VERSION "dbc-export 1 2025.20.8"

NS_ :

BS_:

BU_: ADSP APB APP APS BB BMS CC CP DAS DI DIF DIR EPAS3P EPAS3S EPBL EPBR GTW HVP ICR IDB PCS PM TCU UI UIS VC VCFRONT VCLEFT VCRIGHT VCSEC

BO_ 691 VCRIGHT_logging1Hz: 8 VCRIGHT
 SG_ VCRIGHT_logging1HzIndex M : 0|5@1+ (1,0) [0|31] "" Vector__XXX
 SG_ VCRIGHT_tempIncarCabinProbe m0 : 8|8@1+ (0.5,-40) [-40|85] "degC" Vector__XXX
 SG_ VCRIGHT_tempIncarCabinDeep m0 : 16|8@1+ (0.5,-40) [-40|85] "degC" Vector__XXX
 SG_ VCRIGHT_cabinTempInteriorL2 m0 : 24|8@1+ (0.5,-40) [-40|80] "degC" Vector__XXX
 SG_ VCRIGHT_tempIncarCabinMid m0 : 32|8@1+ (0.5,-40) [-40|85] "degC" Vector__XXX
 SG_ VCRIGHT_cabinTempInteriorSunnyL2 m0 : 40|8@1+ (0.6,-40) [-40|100] "degC" Vector__XXX
 SG_ VCRIGHT_cabinTempInteriorL3 m0 : 48|8@1+ (0.5,-40) [-40|80] "degC" Vector__XXX
 SG_ VCRIGHT_cabinTempInteriorSunnyL3 m0 : 56|8@1+ (0.6,-40) [-40|100] "degC" Vector__XXX
 SG_ VCRIGHT_cabinTempGlassRoof m1 : 8|8@1+ (0.5,-40) [-40|80] "degC" Vector__XXX
 SG_ VCRIGHT_cabinTempWindshield m1 : 16|8@1+ (0.5,-40) [-40|80] "degC" Vector__XXX
 SG_ VCRIGHT_cabinTempInterior m1 : 24|8@1+ (0.5,-40) [-40|80] "degC" Vector__XXX
 SG_ VCRIGHT_cabinTempInteriorSunny m1 : 32|8@1+ (0.6,-40) [-40|100] "degC" Vector__XXX
 SG_ VCRIGHT_cabinTempSideGlassLeft m1 : 40|8@1+ (0.5,-40) [-40|80] "degC" Vector__XXX
 SG_ VCRIGHT_cabinTempSideGlassRight m1 : 48|8@1+ (0.5,-40) [-40|80] "degC" Vector__XXX
 SG_ VCRIGHT_cabinTempBreathLevel m1 : 56|8@1+ (0.5,-40) [-40|80] "degC" Vector__XXX
 SG_ VCRIGHT_pcbaTemperature m2 : 5|11@1+ (0.125,-40) [-40|150] "degC" Vector__XXX
 SG_ VCRIGHT_wattsHeaterLeftTotal m2 : 16|10@1+ (5,0) [0|4000] "W" Vector__XXX
 SG_ VCRIGHT_wattsHeaterRightTotal m2 : 26|10@1+ (5,0) [0|4000] "W" Vector__XXX
 SG_ VCRIGHT_qdotLeftFFUnsat m2 : 36|9@1- (10,0) [-1500|1500] "W" Vector__XXX
 SG_ VCRIGHT_qdotRightFFUnsat m2 : 45|9@1- (10,0) [-1500|1500] "W" Vector__XXX
 SG_ VCRIGHT_nvhLevelDb m2 : 54|9@1+ (0.1,30) [30|80] "dB" Vector__XXX
 SG_ VCRIGHT_hvacSetTempActualLeft m3 : 8|8@1+ (0.1,15) [15|28] "degC" Vector__XXX
 SG_ VCRIGHT_hvacSetTempActualRight m3 : 16|8@1+ (0.1,15) [15|28] "degC" Vector__XXX
 SG_ VCRIGHT_hvacAutoTransitionReason m3 : 24|5@1+ (1,0) [0|31] "" Vector__XXX
 SG_ VCRIGHT_hvacMassflowTarget m3 : 29|8@1+ (1,0) [0|200] "g/s" Vector__XXX
 SG_ VCRIGHT_hvacQdotLimitedLeft m3 : 37|1@1+ (1,0) [0|1] "" Vector__XXX
 SG_ VCRIGHT_hvacQdotLimitedRight m3 : 38|1@1+ (1,0) [0|1] "" Vector__XXX
 SG_ VCRIGHT_LHPanelAirflowBlocked m3 : 39|1@1+ (1,0) [0|1] "" Vector__XXX
 SG_ VCRIGHT_RHPanelAirflowBlocked m3 : 40|1@1+ (1,0) [0|1] "" Vector__XXX
 SG_ VCRIGHT_floorAirflowBlocked m3 : 41|1@1+ (1,0) [0|1] "" Vector__XXX
 SG_ VCRIGHT_defrostAirflowBlocked m3 : 42|1@1+ (1,0) [0|1] "" Vector__XXX
 SG_ VCRIGHT_hvacFilterLifeDetectActi m3 : 43|1@1+ (1,0) [0|1] "" Vector__XXX
 SG_ VCRIGHT_hvacLHBleedOperationMode m3 : 44|1@1+ (1,0) [0|1] "" Vector__XXX
 SG_ VCRIGHT_hvacRHBleedOperationMode m3 : 45|1@1+ (1,0) [0|1] "" Vector__XXX
 SG_ VCRIGHT_hvacLHVaneOperationMode m3 : 46|1@1+ (1,0) [0|1] "" Vector__XXX
 SG_ VCRIGHT_hvacRHVaneOperationMode m3 : 47|1@1+ (1,0) [0|1] "" Vector__XXX
 SG_ VCRIGHT_hvacUpperModeOpMode m3 : 48|1@1+ (1,0) [0|1] "" Vector__XXX
 SG_ VCRIGHT_hvacLowerModeOpMode m3 : 49|1@1+ (1,0) [0|1] "" Vector__XXX
 SG_ VCRIGHT_hvacIntakeOperationMode m3 : 50|1@1+ (1,0) [0|1] "" Vector__XXX
 SG_ VCRIGHT_isProbeFeedbackApplied m3 : 52|3@1+ (1,0) [0|7] "" Vector__XXX
 SG_ VCRIGHT_feedbackPullDownScalar m3 : 55|2@1+ (30,70) [70|130] "-" Vector__XXX
 SG_ VCRIGHT_feedForwardPullDownScala m3 : 57|6@1+ (1,70) [70|130] "-" Vector__XXX
 SG_ VCRIGHT_convectionTargetLeft m4 : 5|9@1+ (4,-1000) [-1000|1000] "W/m2" Vector__XXX
 SG_ VCRIGHT_convectionTargetRight m4 : 14|9@1+ (4,-1000) [-1000|1000] "W/m2" Vector__XXX
 SG_ VCRIGHT_convectionDeliveredLeft m4 : 23|9@1+ (4,-1000) [-1000|1000] "W/m2" Vector__XXX
 SG_ VCRIGHT_convectionDeliveredRight m4 : 32|9@1+ (4,-1000) [-1000|1000] "W/m2" Vector__XXX
 SG_ VCRIGHT_solarLoadRightOccupant m4 : 41|7@1+ (2,0) [0|252] "W/m2" Vector__XXX
 SG_ VCRIGHT_solarLoadLeftOccupant m4 : 48|7@1+ (2,0) [0|252] "W/m2" Vector__XXX
 SG_ VCRIGHT_ptcShutOutletMitigationA m4 : 55|1@1+ (1,0) [0|1] "" Vector__XXX
 SG_ VCRIGHT_solarLoadFromThsTemp m4 : 56|8@1+ (8,-1020) [-1020|1012] "W/m2" Vector__XXX
 SG_ VCRIGHT_ptcHeaterTempDuctHigh m5 : 5|1@1+ (1,0) [0|1] "" Vector__XXX
 SG_ VCRIGHT_ptcHeaterTempDuctFault m5 : 6|1@1+ (1,0) [0|1] "" Vector__XXX
 SG_ VCRIGHT_ptcHeaterNoAirflow m5 : 7|1@1+ (1,0) [0|1] "" Vector__XXX
 SG_ VCRIGHT_ptcHeaterHvacActNotReady m5 : 8|1@1+ (1,0) [0|1] "" Vector__XXX
 SG_ VCRIGHT_ptcHeaterNoUiRequest m5 : 9|1@1+ (1,0) [0|1] "" Vector__XXX
 SG_ VCRIGHT_ptcHeaterNoHighVoltage m5 : 10|1@1+ (1,0) [0|1] "" Vector__XXX
 SG_ VCRIGHT_ptcHeaterLAirPathBlocked m5 : 11|1@1+ (1,0) [0|1] "" Vector__XXX
 SG_ VCRIGHT_ptcHeaterRAirPathBlocked m5 : 12|1@1+ (1,0) [0|1] "" Vector__XXX
 SG_ VCRIGHT_ptcHeaterReqAirpathBlock m5 : 13|1@1+ (1,0) [0|1] "" Vector__XXX
 SG_ VCRIGHT_hvacQdotFeedforward m5 : 16|16@1+ (1,-32767) [-32767|32767] "W" Vector__XXX
 SG_ VCRIGHT_evapLoadInFresh m5 : 32|8@1+ (35,0) [0|8000] "W" Vector__XXX
 SG_ VCRIGHT_evapLoadInRecirc m5 : 40|8@1+ (35,0) [0|8000] "W" Vector__XXX
 SG_ VCRIGHT_cabinTempWshldDefog m5 : 48|8@1+ (0.5,-40) [-40|80] "degC" Vector__XXX
 SG_ VCRIGHT_cabinTempWshldDefogTop m5 : 56|8@1+ (0.5,-40) [-40|80] "degC" Vector__XXX
 SG_ VCRIGHT_hvacLHBleedVoltage m6 : 8|8@1+ (0.02,0) [0|5] "V" Vector__XXX
 SG_ VCRIGHT_hvacRHBleedVoltage m6 : 16|8@1+ (0.02,0) [0|5] "V" Vector__XXX
 SG_ VCRIGHT_hvacLHVaneVoltage m6 : 24|8@1+ (0.02,0) [0|5] "V" Vector__XXX
 SG_ VCRIGHT_hvacRHVaneVoltage m6 : 32|8@1+ (0.02,0) [0|5] "V" Vector__XXX
 SG_ VCRIGHT_hvacUpperModeVoltage m6 : 40|8@1+ (0.02,0) [0|5] "V" Vector__XXX
 SG_ VCRIGHT_hvacLowerModeVoltage m6 : 48|8@1+ (0.02,0) [0|5] "V" Vector__XXX
 SG_ VCRIGHT_hvacIntakeVoltage m6 : 56|8@1+ (0.02,0) [0|5] "V" Vector__XXX
 SG_ VCRIGHT_cabinTempBreathLevelFHea m7 : 8|8@1+ (0.5,-40) [-40|80] "degC" Vector__XXX
 SG_ VCRIGHT_cabinTempBreathLevelFCoo m7 : 16|8@1+ (0.5,-40) [-40|80] "degC" Vector__XXX
 SG_ VCRIGHT_cabinTempBreathLeve_0002 m7 : 24|8@1+ (0.5,-40) [-40|80] "degC" Vector__XXX
 SG_ VCRIGHT_cabinTempBreathLevelF5mi m7 : 32|8@1+ (0.5,-40) [-40|80] "degC" Vector__XXX
 SG_ VCRIGHT_cabinTempBreathLeve_0001 m7 : 40|8@1+ (0.5,-40) [-40|80] "degC" Vector__XXX
 SG_ VCRIGHT_cabinTempBreathLevelF10m m7 : 48|8@1+ (0.5,-40) [-40|80] "degC" Vector__XXX
 SG_ VCRIGHT_cabinTempInteriorFHeatin m7 : 56|8@1+ (0.5,-40) [-40|80] "degC" Vector__XXX
 SG_ VCRIGHT_hvacCabOvrheatProtActive m8 : 5|1@1+ (1,0) [0|1] "" Vector__XXX
 SG_ VCRIGHT_hvacCabinPurgeAllowed m8 : 6|1@1+ (1,0) [0|1] "" Vector__XXX
 SG_ VCRIGHT_hvacCabOvrheatProtAllowe m8 : 7|1@1+ (1,0) [0|1] "" Vector__XXX
 SG_ VCRIGHT_filterLifeBlowerTorque m8 : 8|10@1+ (0.006,-1.5) [-1.5|4.5] "Nm" Vector__XXX
 SG_ VCRIGHT_cabinTempFanCurrent m8 : 18|6@1+ (0.001,-0.01) [-0.01|0.05] "A" Vector__XXX
 SG_ VCRIGHT_cabinTempFanOutput m8 : 24|1@1+ (1,0) [0|1] "" Vector__XXX
 SG_ VCRIGHT_cloudinessEstimatedPct m8 : 25|7@1+ (1,0) [0|100] "%" Vector__XXX
 SG_ VCRIGHT_solarLoadOnVehFiltered m8 : 32|8@1+ (4,0) [0|1016] "W/m2" Vector__XXX
 SG_ VCRIGHT_cabinTempProbeEstimate m8 : 40|8@1+ (0.5,-40) [-40|80] "degC" Vector__XXX
 SG_ VCRIGHT_cabinTempThs m8 : 48|8@1+ (0.5,-40) [-40|80] "degC" Vector__XXX
 SG_ VCRIGHT_cabinTempThsBracket m8 : 56|8@1+ (0.5,-40) [-40|80] "degC" Vector__XXX
 SG_ VCRIGHT_leftHeatOvertempProtect m9 : 5|1@1+ (1,0) [0|1] "" Vector__XXX
 SG_ VCRIGHT_rightHeatOvertempProtect m9 : 6|1@1+ (1,0) [0|1] "" Vector__XXX
 SG_ VCRIGHT_CO2ppm m9 : 7|10@1+ (5,0) [0|4000] "-" Vector__XXX
 SG_ VCRIGHT_timeLeftToCabinModelInit m9 : 17|7@1+ (1,0) [0|127] "" Vector__XXX
 SG_ VCRIGHT_hvacEstimateWindshieldRH m9 : 24|8@1+ (1,0) [0|150] "%" Vector__XXX
 SG_ VCRIGHT_hvacFoggingRiskLevel m9 : 32|7@1+ (1,0) [0|100] "%" Vector__XXX
 SG_ VCRIGHT_hvacCabinHumidityLevel m9 : 39|7@1+ (1,0) [0|100] "%" Vector__XXX
 SG_ VCRIGHT_hvacFlashFoggingDetected m9 : 47|1@1+ (1,0) [0|1] "" Vector__XXX
 SG_ VCRIGHT_solarSensitivityInfr m9 : 48|7@1+ (1,0) [0|100] "-" Vector__XXX
 SG_ VCRIGHT_solarSensitivityInfrCorr m9 : 55|7@1+ (1,0) [0|100] "-" Vector__XXX
 SG_ VCRIGHT_lumbarCurrent m10 : 5|4@1+ (0.2,0) [0|3] "A" Vector__XXX
 SG_ VCRIGHT_ocsCurrent m10 : 9|3@1+ (0.01,0) [0|0.07] "A" Vector__XXX
 SG_ VCRIGHT_rcmCurrent m10 : 12|5@1+ (0.1,0) [0|3.1] "A" Vector__XXX
 SG_ VCRIGHT_radioTunerCurrent m10 : 17|4@1+ (0.1,0) [0|1.5] "A" Vector__XXX
 SG_ VCRIGHT_rearOilPumpCurrent m10 : 21|5@1+ (0.5,0) [0|15.5] "A" Vector__XXX
 SG_ VCRIGHT_rearDefrostCurrent m10 : 26|5@1+ (2,0) [0|62] "A" Vector__XXX
 SG_ VCRIGHT_tailLightCurrent m10 : 31|4@1+ (0.1,0) [0|1.5] "A" Vector__XXX
 SG_ VCRIGHT_turnTailStopLightCurrent m10 : 35|4@1+ (0.1,0) [0|1.5] "A" Vector__XXX
 SG_ VCRIGHT_reverseFogLightsCurrent m10 : 39|4@1+ (0.1,0) [0|1.4] "A" Vector__XXX
 SG_ VCRIGHT_stopReverseTurnLightCurr m10 : 43|4@1+ (0.1,0) [0|1.5] "A" Vector__XXX
 SG_ VCRIGHT_sideMirrorCurrent m10 : 47|5@1+ (0.2,0) [0|6.2] "A" Vector__XXX
 SG_ VCRIGHT_sideMirrorHeaterCurrent m10 : 52|5@1+ (0.2,0) [0|6] "A" Vector__XXX
 SG_ VCRIGHT_frontSeatHeatCushionPwr m10 : 57|7@1+ (1,0) [0|127] "W" Vector__XXX
 SG_ VCRIGHT_trunkInteriorLEDCurrent m11 : 8|4@1+ (5,0) [0|70] "mA" Vector__XXX
 SG_ VCRIGHT_mapPocketLEDsCurrent m11 : 12|4@1+ (5,0) [0|70] "mA" Vector__XXX
 SG_ VCRIGHT_miscEFuseCurrent m11 : 16|5@1+ (0.05,0) [0|1.5] "A" Vector__XXX
 SG_ VCRIGHT_interiorHandleLEDCurrent m11 : 21|4@1+ (2,0) [0|30] "mA" Vector__XXX
 SG_ VCRIGHT_miscInteriorLightsCurren m11 : 25|3@1+ (5,0) [0|30] "mA" Vector__XXX
 SG_ VCRIGHT_frontPuddleLEDCurrent m11 : 28|3@1+ (0.05,0) [0|0.3] "A" Vector__XXX
 SG_ VCRIGHT_rearPuddleLEDCurrent m11 : 31|3@1+ (0.05,0) [0|0.3] "A" Vector__XXX
 SG_ VCRIGHT_liftgateShutfaceLEDCurre m11 : 34|3@1+ (5,0) [0|30] "mA" Vector__XXX
 SG_ VCRIGHT_3rSeatTOSCurrent m11 : 37|4@1+ (5,0) [0|70] "mA" Vector__XXX
 SG_ VCRIGHT_vbatFusedCurrent m11 : 41|4@1+ (0.1,0) [0|1.4] "A" Vector__XXX
 SG_ VCRIGHT_cabinTempGlassGridHeater m11 : 45|8@1+ (0.5,-40) [-40|80] "degC" Vector__XXX
 SG_ VCRIGHT_hvacAirflowReasonRight m11 : 53|5@1+ (1,0) [0|31] "" Vector__XXX
 SG_ VCRIGHT_hvacAirflowReasonLeft m11 : 58|5@1+ (1,0) [0|31] "" Vector__XXX
 SG_ VCRIGHT_hvacMassflowTargetLeft m12 : 5|8@1+ (1,0) [0|200] "g/s" Vector__XXX
 SG_ VCRIGHT_hvacMassflowTargetRight m12 : 13|8@1+ (1,0) [0|200] "g/s" Vector__XXX
 SG_ VCRIGHT_solarLoadLeftOccupantFil m12 : 21|7@1+ (2,0) [0|252] "W/m2" Vector__XXX
 SG_ VCRIGHT_solarLoadRightOccupantFi m12 : 28|7@1+ (2,0) [0|252] "W/m2" Vector__XXX
 SG_ VCRIGHT_windshieldRHCapped m12 : 35|8@1+ (1,0) [0|150] "%" Vector__XXX
 SG_ VCRIGHT_feedbackWarmUpScalar m12 : 43|2@1+ (16,84) [84|116] "-" Vector__XXX
 SG_ VCRIGHT_maxMassflowScalarWarmUp m12 : 45|5@1+ (1,74) [74|100] "-" Vector__XXX
 SG_ VCRIGHT_feedforwardWarmUpScalar m12 : 50|6@1+ (1,80) [80|120] "-" Vector__XXX
 SG_ VCRIGHT_frontSeatHeatBackrestPwr m12 : 56|7@1+ (1,0) [0|127] "W" Vector__XXX
 SG_ VCRIGHT_maxMassflowScalar m13 : 5|6@1+ (1,60) [60|100] "-" Vector__XXX
 SG_ VCRIGHT_massflowTargetAutoInManu m13 : 11|8@1+ (1,0) [0|250] "g/s" Vector__XXX
 SG_ VCRIGHT_airflowReasonAutoInManua m13 : 19|5@1+ (1,0) [0|31] "" Vector__XXX
 SG_ VCRIGHT_airflowReasonAutoIn_0001 m13 : 24|5@1+ (1,0) [0|31] "" Vector__XXX
 SG_ VCRIGHT_airflowReasonAutoIn_0002 m13 : 29|5@1+ (1,0) [0|31] "" Vector__XXX
 SG_ VCRIGHT_cabinTempInteriorFCoolin m13 : 34|8@1+ (0.5,-40) [-40|80] "degC" Vector__XXX
 SG_ VCRIGHT_averageDuctTempFHeating m13 : 42|8@1+ (0.5,-40) [-40|80] "degC" Vector__XXX
 SG_ VCRIGHT_averageDuctTempFCooling m13 : 50|8@1+ (0.5,-40) [-40|80] "degC" Vector__XXX
 SG_ VCRIGHT_hvacBiLevelWhsldRhEst m13 : 58|6@1+ (2,20) [20|120] "%" Vector__XXX
 SG_ VCRIGHT_steeringWheelSurfaceTemp m14 : 5|10@1+ (0.1,-35) [-35|65] "degC" Vector__XXX
 SG_ VCRIGHT_steeringWheelSurfac_0001 m14 : 16|10@1+ (0.1,-35) [-35|65] "degC" Vector__XXX
 SG_ VCRIGHT_timeToComfortHeating m14 : 26|6@1+ (15,-15) [-15|930] "s" Vector__XXX
 SG_ VCRIGHT_timeToComfortCooling m14 : 32|6@1+ (15,-15) [-15|930] "s" Vector__XXX
 SG_ VCRIGHT_cabinWaterMassRaw m14 : 40|8@1+ (0.1,0) [0|25] "g/kg" Vector__XXX
 SG_ VCRIGHT_massflowSingleZoneSplit m14 : 48|7@1+ (1,0) [0|100] "-" Vector__XXX
 SG_ VCRIGHT_VOCPurgeState m14 : 56|3@1+ (1,0) [0|7] "" Vector__XXX
 SG_ VCRIGHT_cameraFoggingMonitorStat m14 : 59|3@1+ (1,0) [0|7] "" Vector__XXX
 SG_ VCRIGHT_cabinOverheatProtectNotR m15 : 5|14@1+ (1,0) [0|16383] "" Vector__XXX
 SG_ VCRIGHT_hvacIntakeReason m15 : 19|5@1+ (1,0) [0|31] "" Vector__XXX
 SG_ VCRIGHT_hvacCabinPurgeActive m15 : 24|1@1+ (1,0) [0|1] "" Vector__XXX
 SG_ VCRIGHT_solarAzimuthCarRef m15 : 25|11@1- (0.5,0) [-511|511.5] "deg" Vector__XXX
 SG_ VCRIGHT_massflowPulldownBias m15 : 36|4@1+ (7,0) [0|100] "%" Vector__XXX
 SG_ VCRIGHT_evapPulldownBias m15 : 40|4@1+ (7,0) [0|100] "%" Vector__XXX
 SG_ VCRIGHT_modeledMassflowFresh m15 : 44|8@1+ (1,0) [0|255] "g/s" Vector__XXX
 SG_ VCRIGHT_modeledMassflowRecirc m15 : 52|8@1+ (1,0) [0|255] "g/s" Vector__XXX
 SG_ VCRIGHT_hvacLimpModeStatus m15 : 60|3@1+ (1,0) [0|7] "" Vector__XXX
 SG_ VCRIGHT_hvacEstimatedCameraWinds m16 : 8|8@1+ (1,0) [0|150] "%" Vector__XXX

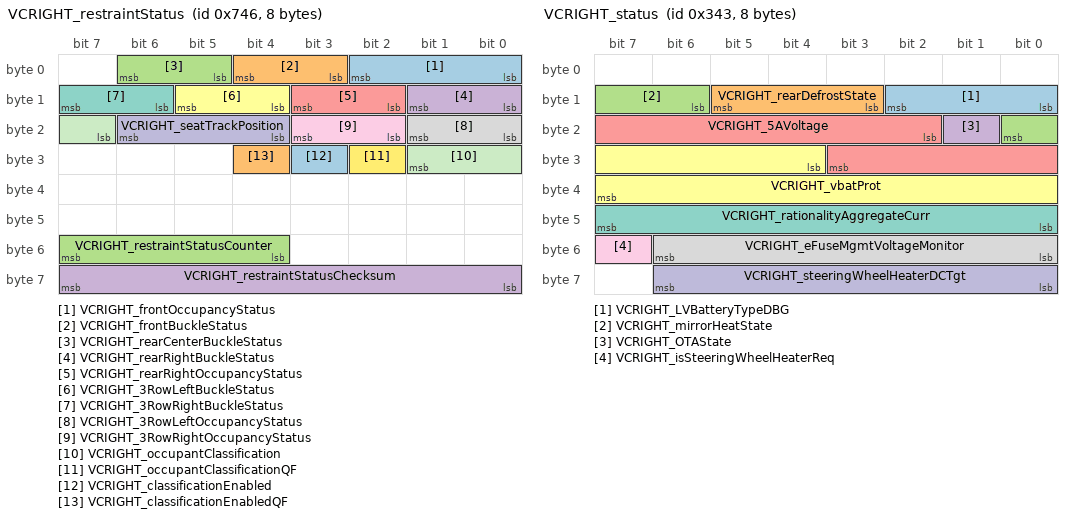
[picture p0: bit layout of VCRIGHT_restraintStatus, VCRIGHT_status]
BO_ 1862 VCRIGHT_restraintStatus: 8 VCRIGHT
 SG_ VCRIGHT_frontOccupancyStatus : 0|3@1+ (1,0) [0|6] "" Vector__XXX
 SG_ VCRIGHT_frontBuckleStatus : 3|2@1+ (1,0) [0|2] "" Vector__XXX
 SG_ VCRIGHT_rearCenterBuckleStatus : 5|2@1+ (1,0) [0|2] "" Vector__XXX
 SG_ VCRIGHT_rearRightBuckleStatus : 8|2@1+ (1,0) [0|2] "" Vector__XXX
 SG_ VCRIGHT_rearRightOccupancyStatus : 10|2@1+ (1,0) [0|2] "" Vector__XXX
 SG_ VCRIGHT_3RowLeftBuckleStatus : 12|2@1+ (1,0) [0|2] "" Vector__XXX
 SG_ VCRIGHT_3RowRightBuckleStatus : 14|2@1+ (1,0) [0|2] "" Vector__XXX
 SG_ VCRIGHT_3RowLeftOccupancyStatus : 16|2@1+ (1,0) [0|2] "" Vector__XXX
 SG_ VCRIGHT_3RowRightOccupancyStatus : 18|2@1+ (1,0) [0|2] "" Vector__XXX
 SG_ VCRIGHT_seatTrackPosition : 20|3@1+ (1,0) [0|6] "" Vector__XXX
 SG_ VCRIGHT_occupantClassification : 23|3@1+ (1,0) [0|6] "" Vector__XXX
 SG_ VCRIGHT_occupantClassificationQF : 26|1@1+ (1,0) [0|1] "" Vector__XXX
 SG_ VCRIGHT_classificationEnabled : 27|1@1+ (1,0) [0|1] "" Vector__XXX
 SG_ VCRIGHT_classificationEnabledQF : 28|1@1+ (1,0) [0|1] "" Vector__XXX
 SG_ VCRIGHT_restraintStatusCounter : 52|4@1+ (1,0) [0|15] "" Vector__XXX
 SG_ VCRIGHT_restraintStatusChecksum : 56|8@1+ (1,0) [0|255] "" Vector__XXX

BO_ 1251 VCRIGHT_seatStatus: 8 VCRIGHT
 SG_ VCRIGHT_seatStatusIndex M : 0|3@1+ (1,0) [0|7] "" Vector__XXX
 SG_ VCRIGHT_frontSeatTrackPos m0 : 8|16@1- (1,0) [-32768|32767] "" Vector__XXX
 SG_ VCRIGHT_frontSeatTrackCurrent m0 : 24|12@1- (0.01,0) [-20.48|20.47] "A" Vector__XXX
 SG_ VCRIGHT_frontSeatTrackDuty m0 : 36|12@1- (0.1,0) [-204.8|204.7] "%" Vector__XXX
 SG_ VCRIGHT_frontSeatTrackState m0 : 48|3@1+ (1,0) [0|7] "" Vector__XXX
 SG_ VCRIGHT_frontSeatTrackCalibrated m0 : 51|1@1+ (1,0) [0|1] "" Vector__XXX
 SG_ VCRIGHT_frontSeatTrackLog m0 : 52|1@1+ (1,0) [0|1] "" Vector__XXX
 SG_ VCRIGHT_frontSeatTrackBridgeSt m0 : 53|2@1+ (1,0) [0|3] "" Vector__XXX
 SG_ VCRIGHT_frontSeatBackPos m1 : 8|16@1- (1,0) [-32768|32767] "" Vector__XXX
 SG_ VCRIGHT_frontSeatBackCurrent m1 : 24|12@1- (0.01,0) [-20.48|20.47] "A" Vector__XXX
 SG_ VCRIGHT_frontSeatBackDuty m1 : 36|12@1- (0.1,0) [-204.8|204.7] "%" Vector__XXX
 SG_ VCRIGHT_frontSeatBackState m1 : 48|3@1+ (1,0) [0|7] "" Vector__XXX
 SG_ VCRIGHT_frontSeatBackCalibrated m1 : 51|1@1+ (1,0) [0|1] "" Vector__XXX
 SG_ VCRIGHT_frontSeatBackLog m1 : 52|1@1+ (1,0) [0|1] "" Vector__XXX
 SG_ VCRIGHT_frontSeatBackBridgeSt m1 : 53|2@1+ (1,0) [0|3] "" Vector__XXX
 SG_ VCRIGHT_frontSeatLiftPos m2 : 8|16@1- (1,0) [-32768|32767] "" Vector__XXX
 SG_ VCRIGHT_frontSeatLiftCurrent m2 : 24|12@1- (0.01,0) [-20.48|20.47] "A" Vector__XXX
 SG_ VCRIGHT_frontSeatLiftDuty m2 : 36|12@1- (0.1,0) [-204.8|204.7] "%" Vector__XXX
 SG_ VCRIGHT_frontSeatLiftState m2 : 48|3@1+ (1,0) [0|7] "" Vector__XXX
 SG_ VCRIGHT_frontSeatLiftCalibrated m2 : 51|1@1+ (1,0) [0|1] "" Vector__XXX
 SG_ VCRIGHT_frontSeatLiftLog m2 : 52|1@1+ (1,0) [0|1] "" Vector__XXX
 SG_ VCRIGHT_frontSeatLiftBridgeSt m2 : 53|2@1+ (1,0) [0|3] "" Vector__XXX
 SG_ VCRIGHT_frontSeatTiltPos m3 : 8|16@1- (1,0) [-32768|32767] "" Vector__XXX
 SG_ VCRIGHT_frontSeatTiltCurrent m3 : 24|12@1- (0.01,0) [-20.48|20.47] "A" Vector__XXX
 SG_ VCRIGHT_frontSeatTiltDuty m3 : 36|12@1- (0.1,0) [-204.8|204.7] "%" Vector__XXX
 SG_ VCRIGHT_frontSeatTiltState m3 : 48|3@1+ (1,0) [0|7] "" Vector__XXX
 SG_ VCRIGHT_frontSeatTiltCalibrated m3 : 51|1@1+ (1,0) [0|1] "" Vector__XXX
 SG_ VCRIGHT_frontSeatTiltLog m3 : 52|1@1+ (1,0) [0|1] "" Vector__XXX
 SG_ VCRIGHT_frontSeatTiltBridgeSt m3 : 53|2@1+ (1,0) [0|3] "" Vector__XXX
 SG_ VCRIGHT_lumbarAState m4 : 3|3@1+ (1,0) [0|7] "" Vector__XXX
 SG_ VCRIGHT_lumbarBState m4 : 6|3@1+ (1,0) [0|7] "" Vector__XXX
 SG_ VCRIGHT_lumbarAPressureHpa m4 : 9|12@1+ (1,0) [0|4095] "" Vector__XXX
 SG_ VCRIGHT_lumbarAPressureHpaFilt m4 : 21|10@1+ (1,0) [0|1023] "" Vector__XXX
 SG_ VCRIGHT_lumbarBPressureHpa m4 : 31|12@1+ (1,0) [0|4095] "" Vector__XXX
 SG_ VCRIGHT_lumbarBPressureHpaFilt m4 : 43|10@1+ (1,0) [0|1023] "" Vector__XXX
 SG_ VCRIGHT_lumbarActiveTooLongErr m4 : 53|1@1+ (1,0) [0|1] "" Vector__XXX
 SG_ VCRIGHT_lumbarMaxPErr m4 : 54|1@1+ (1,0) [0|1] "" Vector__XXX
 SG_ VCRIGHT_lumbarOvercurrentErr m4 : 55|1@1+ (1,0) [0|1] "" Vector__XXX
 SG_ VCRIGHT_lumbarMaxOperatingPErr m4 : 56|1@1+ (1,0) [0|1] "" Vector__XXX
 SG_ VCRIGHT_lumbarMinPErr m4 : 57|1@1+ (1,0) [0|1] "" Vector__XXX
 SG_ VCRIGHT_lumbarGeneralErr m4 : 58|1@1+ (1,0) [0|1] "" Vector__XXX
 SG_ VCRIGHT_lumbarDevMaxPumpPressA m4 : 59|1@1+ (1,0) [0|1] "" Vector__XXX
 SG_ VCRIGHT_lumbarDevMaxPumpPressB m4 : 60|1@1+ (1,0) [0|1] "" Vector__XXX
 SG_ VCRIGHT_frontSeatTrackPosReal m5 : 3|12@1- (1,0) [-2048|2047] "mm" Vector__XXX
 SG_ VCRIGHT_frontSeatBackPosReal m5 : 16|12@1- (0.1,0) [-204.8|204.7] "deg" Vector__XXX
 SG_ VCRIGHT_frontSeatLiftPosReal m5 : 28|12@1- (1,0) [-2048|2047] "mm" Vector__XXX
 SG_ VCRIGHT_frontSeatTiltPosReal m5 : 40|12@1- (0.1,0) [-204.8|204.7] "deg" Vector__XXX
 SG_ VCRIGHT_frontSeatTrackPosOffset m6 : 3|12@1- (1,0) [-2048|2047] "mm" Vector__XXX
 SG_ VCRIGHT_frontSeatBackPosOffset m6 : 16|12@1- (0.1,0) [-204.8|204.7] "deg" Vector__XXX
 SG_ VCRIGHT_frontSeatLiftPosOffset m6 : 28|12@1- (1,0) [-2048|2047] "mm" Vector__XXX
 SG_ VCRIGHT_frontSeatTiltPosOffset m6 : 40|12@1- (0.1,0) [-204.8|204.7] "deg" Vector__XXX

BO_ 739 VCRIGHT_seatStatus2: 7 VCRIGHT
 SG_ VCRIGHT_seatStatus2Index M : 0|4@1+ (1,0) [0|15] "" Vector__XXX
 SG_ VCRIGHT_frontSeatHeatCurrent m0 : 4|12@1+ (0.01,0) [0|40.95] "A" Vector__XXX
 SG_ VCRIGHT_frontSeatHeatDuty m0 : 16|8@1+ (1,0) [0|255] "%" Vector__XXX
 SG_ VCRIGHT_frontSeatHeatTmp m0 : 24|12@1- (0.05,0) [-40|80] "degC" Vector__XXX
 SG_ VCRIGHT_frontSeatHeatTmpTarget m0 : 36|8@1- (0.5,0) [0|60] "degC" Vector__XXX
 SG_ VCRIGHT_frontSeatHeatInhibited m0 : 44|1@1+ (1,0) [0|1] "" Vector__XXX
 SG_ VCRIGHT_frontSeatHeatPowered m0 : 45|1@1+ (1,0) [0|1] "" Vector__XXX
 SG_ VCRIGHT_rearLSeatHeatCurrent m1 : 4|12@1+ (0.01,0) [0|40.95] "A" Vector__XXX
 SG_ VCRIGHT_rearLSeatHeatDuty m1 : 16|8@1+ (1,0) [0|255] "%" Vector__XXX
 SG_ VCRIGHT_rearLSeatHeatTmp m1 : 24|12@1- (0.05,0) [-40|80] "degC" Vector__XXX
 SG_ VCRIGHT_rearLSeatHeatTmpTarget m1 : 36|8@1- (0.5,0) [0|60] "degC" Vector__XXX
 SG_ VCRIGHT_rearLSeatHeatInhibited m1 : 44|1@1+ (1,0) [0|1] "" Vector__XXX
 SG_ VCRIGHT_rearLSeatHeatPowered m1 : 45|1@1+ (1,0) [0|1] "" Vector__XXX
 SG_ VCRIGHT_rearCSeatHeatCurrent m2 : 4|12@1+ (0.01,0) [0|40.95] "A" Vector__XXX
 SG_ VCRIGHT_rearCSeatHeatDuty m2 : 16|8@1+ (1,0) [0|255] "%" Vector__XXX
 SG_ VCRIGHT_rearCSeatHeatTmp m2 : 24|12@1- (0.05,0) [-40|80] "degC" Vector__XXX
 SG_ VCRIGHT_rearCSeatHeatTmpTarget m2 : 36|8@1- (0.5,0) [0|60] "degC" Vector__XXX
 SG_ VCRIGHT_rearCSeatHeatInhibited m2 : 44|1@1+ (1,0) [0|1] "" Vector__XXX
 SG_ VCRIGHT_rearCSeatHeatPowered m2 : 45|1@1+ (1,0) [0|1] "" Vector__XXX
 SG_ VCRIGHT_rearRSeatHeatCurrent m3 : 4|12@1+ (0.01,0) [0|40.95] "A" Vector__XXX
 SG_ VCRIGHT_rearRSeatHeatDuty m3 : 16|8@1+ (1,0) [0|255] "%" Vector__XXX
 SG_ VCRIGHT_rearRSeatHeatTmp m3 : 24|12@1- (0.05,0) [-40|80] "degC" Vector__XXX
 SG_ VCRIGHT_rearRSeatHeatTmpTarget m3 : 36|8@1- (0.5,0) [0|60] "degC" Vector__XXX
 SG_ VCRIGHT_rearRSeatHeatInhibited m3 : 44|1@1+ (1,0) [0|1] "" Vector__XXX
 SG_ VCRIGHT_rearRSeatHeatPowered m3 : 45|1@1+ (1,0) [0|1] "" Vector__XXX

BO_ 835 VCRIGHT_status: 8 VCRIGHT
 SG_ VCRIGHT_LVBatteryTypeDBG : 8|3@1+ (1,0) [0|7] "" Vector__XXX
 SG_ VCRIGHT_rearDefrostState : 11|3@1+ (1,0) [1|7] "" Vector__XXX
 SG_ VCRIGHT_mirrorHeatState : 14|3@1+ (1,0) [1|7] "" Vector__XXX
 SG_ VCRIGHT_OTAState : 17|1@1+ (1,0) [0|1] "" Vector__XXX
 SG_ VCRIGHT_5AVoltage : 18|10@1+ (0.005443676,0) [0|5.568880548] "V" Vector__XXX
 SG_ VCRIGHT_vbatProt : 28|12@1+ (0.005443676,0) [0|22.29185322] "V" Vector__XXX
 SG_ VCRIGHT_rationalityAggregateCurr : 40|8@1+ (0.5,0) [0|127.5] "A" Vector__XXX
 SG_ VCRIGHT_eFuseMgmtVoltageMonitor : 48|7@1+ (0.125,0) [0|15.875] "V" Vector__XXX
 SG_ VCRIGHT_isSteeringWheelHeaterReq : 55|1@1+ (1,0) [0|1] "" Vector__XXX
 SG_ VCRIGHT_steeringWheelHeaterDCTgt : 56|7@1+ (0.01,0) [0|1] "-" Vector__XXX

BO_ 963 VCRIGHT_switchStatus: 8 VCRIGHT
 SG_ VCRIGHT_switchStatusIndex M : 0|1@1+ (1,0) [0|1] "" Vector__XXX
 SG_ VCRIGHT_trunkExtReleasePressedPe m1 : 1|1@1+ (1,0) [0|1] "" Vector__XXX
 SG_ VCRIGHT_frontSeatTrackBack m1 : 2|2@1+ (1,0) [1|3] "" Vector__XXX
 SG_ VCRIGHT_frontSeatTrackForward m1 : 4|2@1+ (1,0) [1|3] "" Vector__XXX
 SG_ VCRIGHT_frontSeatTiltDown m1 : 6|2@1+ (1,0) [1|3] "" Vector__XXX
 SG_ VCRIGHT_frontSeatTiltUp m1 : 8|2@1+ (1,0) [1|3] "" Vector__XXX
 SG_ VCRIGHT_frontSeatLiftDown m1 : 10|2@1+ (1,0) [1|3] "" Vector__XXX
 SG_ VCRIGHT_frontSeatLiftUp m1 : 12|2@1+ (1,0) [1|3] "" Vector__XXX
 SG_ VCRIGHT_frontSeatBackrestBack m1 : 14|2@1+ (1,0) [1|3] "" Vector__XXX
 SG_ VCRIGHT_frontSeatBackrestForward m1 : 16|2@1+ (1,0) [1|3] "" Vector__XXX
 SG_ VCRIGHT_frontSeatLumbarDown m1 : 18|2@1+ (1,0) [1|3] "" Vector__XXX
 SG_ VCRIGHT_frontSeatLumbarUp m1 : 20|2@1+ (1,0) [1|3] "" Vector__XXX
 SG_ VCRIGHT_frontSeatLumbarIn m1 : 22|2@1+ (1,0) [1|3] "" Vector__XXX
 SG_ VCRIGHT_frontSeatLumbarOut m1 : 24|2@1+ (1,0) [1|3] "" Vector__XXX
 SG_ VCRIGHT_frontHandlePWM m1 : 32|7@1+ (1,0) [0|100] "%" Vector__XXX
 SG_ VCRIGHT_rearHandlePWM m1 : 40|7@1+ (1,0) [0|100] "%" Vector__XXX
 SG_ VCRIGHT_gloveboxLightCurrent m1 : 47|5@1+ (2,0) [0|62] "mA" Vector__XXX
 SG_ VCRIGHT_frontSeatALR m1 : 52|2@1+ (1,0) [1|3] "" Vector__XXX
 SG_ VCRIGHT_frontSeatResistiveOccupa m1 : 54|2@1+ (1,0) [1|3] "" Vector__XXX
 SG_ VCRIGHT_2RowSeatReclineSwitchpac m1 : 56|3@1+ (1,0) [0|7] "" Vector__XXX

BO_ 537 VCSEC_TPMSData: 7 VCSEC
 SG_ VCSEC_TPMSDataIndex M : 0|3@1+ (1,0) [0|7] "" Vector__XXX
 SG_ VCSEC_TPMSCapabilityPressureInAd m0 : 3|1@1+ (1,0) [0|1] "" Vector__XXX
 SG_ VCSEC_TPMSCapabilityConfigurable m0 : 4|1@1+ (1,0) [0|1] "" Vector__XXX
 SG_ VCSEC_TPMSPressureRateOfChange0 m0 : 5|10@1- (0.02,0) [-10.24|10.22] "kPa/S" Vector__XXX
 SG_ VCSEC_TPMSPressure0 m0 : 15|9@1+ (0.025,0) [0|12.75] "bar" Vector__XXX
 SG_ VCSEC_TPMSTemperature0 m0 : 24|8@1+ (1,-40) [-40|214] "degC" Vector__XXX
 SG_ VCSEC_TPMSBatVoltage0 m0 : 32|8@1+ (0.01,1.5) [1.5|4.04] "V" Vector__XXX
 SG_ VCSEC_TPMSLocation0 m0 : 40|3@1+ (1,0) [0|7] "" Vector__XXX
 SG_ VCSEC_TPMSTemperatureCompensated m0 : 43|9@1+ (0.025,0) [0|12.75] "bar" Vector__XXX
 SG_ VCSEC_TPMSCapabilityPressur_0001 m1 : 3|1@1+ (1,0) [0|1] "" Vector__XXX
 SG_ VCSEC_TPMSCapabilityConfigu_0001 m1 : 4|1@1+ (1,0) [0|1] "" Vector__XXX
 SG_ VCSEC_TPMSPressureRateOfChange1 m1 : 5|10@1- (0.02,0) [-10.24|10.22] "kPa/S" Vector__XXX
 SG_ VCSEC_TPMSPressure1 m1 : 15|9@1+ (0.025,0) [0|12.75] "bar" Vector__XXX
 SG_ VCSEC_TPMSTemperature1 m1 : 24|8@1+ (1,-40) [-40|214] "degC" Vector__XXX
 SG_ VCSEC_TPMSBatVoltage1 m1 : 32|8@1+ (0.01,1.5) [1.5|4.04] "V" Vector__XXX
 SG_ VCSEC_TPMSLocation1 m1 : 40|3@1+ (1,0) [0|7] "" Vector__XXX
 SG_ VCSEC_TPMSTemperatureCompen_0001 m1 : 43|9@1+ (0.025,0) [0|12.75] "bar" Vector__XXX
 SG_ VCSEC_TPMSCapabilityPressur_0002 m2 : 3|1@1+ (1,0) [0|1] "" Vector__XXX
 SG_ VCSEC_TPMSCapabilityConfigu_0002 m2 : 4|1@1+ (1,0) [0|1] "" Vector__XXX
 SG_ VCSEC_TPMSPressureRateOfChange2 m2 : 5|10@1- (0.02,0) [-10.24|10.22] "kPa/S" Vector__XXX
 SG_ VCSEC_TPMSPressure2 m2 : 15|9@1+ (0.025,0) [0|12.75] "bar" Vector__XXX
 SG_ VCSEC_TPMSTemperature2 m2 : 24|8@1+ (1,-40) [-40|214] "degC" Vector__XXX
 SG_ VCSEC_TPMSBatVoltage2 m2 : 32|8@1+ (0.01,1.5) [1.5|4.04] "V" Vector__XXX
 SG_ VCSEC_TPMSLocation2 m2 : 40|3@1+ (1,0) [0|7] "" Vector__XXX
 SG_ VCSEC_TPMSTemperatureCompen_0002 m2 : 43|9@1+ (0.025,0) [0|12.75] "bar" Vector__XXX
 SG_ VCSEC_TPMSCapabilityPressur_0003 m3 : 3|1@1+ (1,0) [0|1] "" Vector__XXX
 SG_ VCSEC_TPMSCapabilityConfigu_0003 m3 : 4|1@1+ (1,0) [0|1] "" Vector__XXX
 SG_ VCSEC_TPMSPressureRateOfChange3 m3 : 5|10@1- (0.02,0) [-10.24|10.22] "kPa/S" Vector__XXX
 SG_ VCSEC_TPMSPressure3 m3 : 15|9@1+ (0.025,0) [0|12.75] "bar" Vector__XXX
 SG_ VCSEC_TPMSTemperature3 m3 : 24|8@1+ (1,-40) [-40|214] "degC" Vector__XXX
 SG_ VCSEC_TPMSBatVoltage3 m3 : 32|8@1+ (0.01,1.5) [1.5|4.04] "V" Vector__XXX
 SG_ VCSEC_TPMSLocation3 m3 : 40|3@1+ (1,0) [0|7] "" Vector__XXX
 SG_ VCSEC_TPMSTemperatureCompen_0003 m3 : 43|9@1+ (0.025,0) [0|12.75] "bar" Vector__XXX
 SG_ VCSEC_TPMSRecommendedColdPressur m4 : 8|8@1+ (0.025,0) [0|6.35] "bar" Vector__XXX
 SG_ VCSEC_TPMSRecommendedColdPr_0001 m4 : 16|8@1+ (0.025,0) [0|6.35] "bar" Vector__XXX
 SG_ VCSEC_TPMSFeature0 m4 : 24|3@1+ (1,0) [0|7] "" Vector__XXX
 SG_ VCSEC_TPMSFeature1 m4 : 27|3@1+ (1,0) [0|7] "" Vector__XXX
 SG_ VCSEC_TPMSFeature0Count m4 : 32|4@1+ (1,0) [0|15] "" Vector__XXX
 SG_ VCSEC_TPMSFeature0TimeS m4 : 36|11@1+ (1,0) [0|2047] "" Vector__XXX

BO_ 570 VCSEC_TPMSStatus: 8 VCSEC
 SG_ VCSEC_TPMSStatusIndex M : 0|5@1+ (1,0) [0|31] "" Vector__XXX
 SG_ VCSEC_TPMSSystemState : 5|1@1+ (1,0) [0|1] "" Vector__XXX
 SG_ VCSEC_TPMSSensorMACAddress0 m0 : 8|48@1+ (1,0) [0|281474976710655] "" Vector__XXX
 SG_ VCSEC_TPMSSensorMACAddress1 m1 : 8|48@1+ (1,0) [0|281474976710655] "" Vector__XXX
 SG_ VCSEC_TPMSSensorMACAddress2 m2 : 8|48@1+ (1,0) [0|281474976710655] "" Vector__XXX
 SG_ VCSEC_TPMSSensorMACAddress3 m3 : 8|48@1+ (1,0) [0|281474976710655] "" Vector__XXX
 SG_ VCSEC_BLESuccessfulConnEventCoun m4 : 6|15@1+ (1,0) [0|32767] "" Vector__XXX
 SG_ VCSEC_BLEMissedConnEventCount0 m4 : 21|14@1+ (1,0) [0|16383] "" Vector__XXX
 SG_ VCSEC_BLECRCErrorConnEventCount0 m4 : 35|14@1+ (1,0) [0|16383] "" Vector__XXX
 SG_ VCSEC_BLEOtherFailuresCount0 m4 : 49|5@1+ (1,0) [0|31] "" Vector__XXX
 SG_ VCSEC_BLEUnsuccessfulConnEventRa m4 : 54|10@1+ (0.08,0) [0|81.76] "%" Vector__XXX
 SG_ VCSEC_BLESuccessfulConnEven_0001 m5 : 6|15@1+ (1,0) [0|32767] "" Vector__XXX
 SG_ VCSEC_BLEMissedConnEventCount1 m5 : 21|14@1+ (1,0) [0|16383] "" Vector__XXX
 SG_ VCSEC_BLECRCErrorConnEventCount1 m5 : 35|14@1+ (1,0) [0|16383] "" Vector__XXX
 SG_ VCSEC_BLEOtherFailuresCount1 m5 : 49|5@1+ (1,0) [0|31] "" Vector__XXX
 SG_ VCSEC_BLEUnsuccessfulConnEv_0001 m5 : 54|10@1+ (0.08,0) [0|81.76] "%" Vector__XXX
 SG_ VCSEC_BLESuccessfulConnEven_0002 m6 : 6|15@1+ (1,0) [0|32767] "" Vector__XXX
 SG_ VCSEC_BLEMissedConnEventCount2 m6 : 21|14@1+ (1,0) [0|16383] "" Vector__XXX
 SG_ VCSEC_BLECRCErrorConnEventCount2 m6 : 35|14@1+ (1,0) [0|16383] "" Vector__XXX
 SG_ VCSEC_BLEOtherFailuresCount2 m6 : 49|5@1+ (1,0) [0|31] "" Vector__XXX
 SG_ VCSEC_BLEUnsuccessfulConnEv_0002 m6 : 54|10@1+ (0.08,0) [0|81.76] "%" Vector__XXX
 SG_ VCSEC_BLESuccessfulConnEven_0003 m7 : 6|15@1+ (1,0) [0|32767] "" Vector__XXX
 SG_ VCSEC_BLEMissedConnEventCount3 m7 : 21|14@1+ (1,0) [0|16383] "" Vector__XXX
 SG_ VCSEC_BLECRCErrorConnEventCount3 m7 : 35|14@1+ (1,0) [0|16383] "" Vector__XXX
 SG_ VCSEC_BLEOtherFailuresCount3 m7 : 49|5@1+ (1,0) [0|31] "" Vector__XXX
 SG_ VCSEC_BLEUnsuccessfulConnEv_0003 m7 : 54|10@1+ (0.08,0) [0|81.76] "%" Vector__XXX
 SG_ VCSEC_TPMSSensorTIAppCRC0 m8 : 8|32@1+ (1,0) [1|4294967295] "" Vector__XXX
 SG_ VCSEC_TPMSSensorMLXAppCRC0 m8 : 40|24@1+ (1,0) [1|16777215] "" Vector__XXX
 SG_ VCSEC_TPMSSensorTIAppCRC1 m9 : 8|32@1+ (1,0) [1|4294967295] "" Vector__XXX
 SG_ VCSEC_TPMSSensorMLXAppCRC1 m9 : 40|24@1+ (1,0) [1|16777215] "" Vector__XXX
 SG_ VCSEC_TPMSSensorTIAppCRC2 m10 : 8|32@1+ (1,0) [1|4294967295] "" Vector__XXX
 SG_ VCSEC_TPMSSensorMLXAppCRC2 m10 : 40|24@1+ (1,0) [1|16777215] "" Vector__XXX
 SG_ VCSEC_TPMSSensorTIAppCRC3 m11 : 8|32@1+ (1,0) [1|4294967295] "" Vector__XXX
 SG_ VCSEC_TPMSSensorMLXAppCRC3 m11 : 40|24@1+ (1,0) [1|16777215] "" Vector__XXX
 SG_ VCSEC_TPMStotalAwakeTime0 m16 : 8|32@1+ (1,0) [0|4294967295] "" Vector__XXX
 SG_ VCSEC_TPMSTrimAdjusted0 m16 : 40|1@1+ (1,0) [0|1] "" Vector__XXX
 SG_ VCSEC_TPMSGenealogySensorState0 m16 : 41|3@1+ (1,0) [0|7] "" Vector__XXX
 SG_ VCSEC_TPMSSensorType0 m16 : 44|3@1+ (1,0) [0|7] "" Vector__XXX
 SG_ VCSEC_TPMStotalAwakeTime1 m17 : 8|32@1+ (1,0) [0|4294967295] "" Vector__XXX
 SG_ VCSEC_TPMSTrimAdjusted1 m17 : 40|1@1+ (1,0) [0|1] "" Vector__XXX
 SG_ VCSEC_TPMSGenealogySensorState1 m17 : 41|3@1+ (1,0) [0|7] "" Vector__XXX
 SG_ VCSEC_TPMSSensorType1 m17 : 44|3@1+ (1,0) [0|7] "" Vector__XXX
 SG_ VCSEC_TPMStotalAwakeTime2 m18 : 8|32@1+ (1,0) [0|4294967295] "" Vector__XXX
 SG_ VCSEC_TPMSTrimAdjusted2 m18 : 40|1@1+ (1,0) [0|1] "" Vector__XXX
 SG_ VCSEC_TPMSGenealogySensorState2 m18 : 41|3@1+ (1,0) [0|7] "" Vector__XXX
 SG_ VCSEC_TPMSSensorType2 m18 : 44|3@1+ (1,0) [0|7] "" Vector__XXX
 SG_ VCSEC_TPMStotalAwakeTime3 m19 : 8|32@1+ (1,0) [0|4294967295] "" Vector__XXX
 SG_ VCSEC_TPMSTrimAdjusted3 m19 : 40|1@1+ (1,0) [0|1] "" Vector__XXX
 SG_ VCSEC_TPMSGenealogySensorState3 m19 : 41|3@1+ (1,0) [0|7] "" Vector__XXX
 SG_ VCSEC_TPMSSensorType3 m19 : 44|3@1+ (1,0) [0|7] "" Vector__XXX

BO_ 1067 VCSEC_UWBData: 8 VCSEC
 SG_ VCSEC_UWBEndpointIndex M : 0|2@1+ (1,0) [0|3] "" Vector__XXX
 SG_ VCSEC_UWBRearRightDistance0 m0 : 2|12@1+ (1,0) [0|4094] "cm" Vector__XXX
 SG_ VCSEC_UWBRearRightDistance1 m0 : 16|12@1+ (1,0) [0|4094] "cm" Vector__XXX
 SG_ VCSEC_UWBRearRightDistance2 m0 : 28|12@1+ (1,0) [0|4094] "cm" Vector__XXX
 SG_ VCSEC_UWBLeftDistance2 m1 : 2|12@1+ (1,0) [0|4094] "cm" Vector__XXX
 SG_ VCSEC_UWBRightDistance2 m1 : 16|12@1+ (1,0) [0|4094] "cm" Vector__XXX
 SG_ VCSEC_UWBRearDistance2 m1 : 28|12@1+ (1,0) [0|4094] "cm" Vector__XXX
 SG_ VCSEC_UWBRearLeftDistance2 m1 : 40|12@1+ (1,0) [0|4094] "cm" Vector__XXX
 SG_ VCSEC_UWBCenterDistance2 m1 : 52|12@1+ (1,0) [0|4094] "cm" Vector__XXX
 SG_ VCSEC_UWBLeftDistance1 m2 : 2|12@1+ (1,0) [0|4094] "cm" Vector__XXX
 SG_ VCSEC_UWBRightDistance1 m2 : 16|12@1+ (1,0) [0|4094] "cm" Vector__XXX
 SG_ VCSEC_UWBRearDistance1 m2 : 28|12@1+ (1,0) [0|4094] "cm" Vector__XXX
 SG_ VCSEC_UWBRearLeftDistance1 m2 : 40|12@1+ (1,0) [0|4094] "cm" Vector__XXX
 SG_ VCSEC_UWBCenterDistance1 m2 : 52|12@1+ (1,0) [0|4094] "cm" Vector__XXX
 SG_ VCSEC_UWBLeftDistance0 m3 : 2|12@1+ (1,0) [0|4094] "cm" Vector__XXX
 SG_ VCSEC_UWBRightDistance0 m3 : 16|12@1+ (1,0) [0|4094] "cm" Vector__XXX
 SG_ VCSEC_UWBRearDistance0 m3 : 28|12@1+ (1,0) [0|4094] "cm" Vector__XXX
 SG_ VCSEC_UWBRearLeftDistance0 m3 : 40|12@1+ (1,0) [0|4094] "cm" Vector__XXX
 SG_ VCSEC_UWBCenterDistance0 m3 : 52|12@1+ (1,0) [0|4094] "cm" Vector__XXX

BO_ 761 VCSEC_additionalAuthInfo: 8 VCSEC
 SG_ VCSEC_activeKeyDebug : 2|5@1+ (1,0) [0|31] "" Vector__XXX
 SG_ VCSEC_bleChannelDisconnected : 7|4@1+ (1,0) [0|15] "" Vector__XXX
 SG_ VCSEC_bleDisconnectionReason : 11|8@1+ (1,0) [0|255] "" Vector__XXX
 SG_ VCSEC_bleConnetionAttemptWLEntry : 19|5@1+ (1,0) [0|31] "" Vector__XXX
 SG_ VCSEC_AdditionalAuthInfoIndex M : 27|3@1+ (1,0) [0|7] "" Vector__XXX
 SG_ VCSEC_activeKeyReason m0 : 24|3@1+ (1,0) [0|7] "" Vector__XXX
 SG_ VCSEC_activeKeySHA1 m0 : 32|32@1+ (1,0) [0|4294967295] "" Vector__XXX
 SG_ VCSEC_algoUsedForSummonRange0 m1 : 0|1@1+ (1,0) [0|1] "" Vector__XXX
 SG_ VCSEC_keyWithinSummonRange0 m1 : 32|32@1+ (1,0) [0|4294967295] "" Vector__XXX
 SG_ VCSEC_algoUsedForSummonRange1 m2 : 0|1@1+ (1,0) [0|1] "" Vector__XXX
 SG_ VCSEC_keyWithinSummonRange1 m2 : 32|32@1+ (1,0) [0|4294967295] "" Vector__XXX
 SG_ VCSEC_algoUsedForSummonRange2 m3 : 0|1@1+ (1,0) [0|1] "" Vector__XXX
 SG_ VCSEC_keyWithinSummonRange2 m3 : 32|32@1+ (1,0) [0|4294967295] "" Vector__XXX
 SG_ VCSEC_BLEDeviceWithinSummonRange m4 : 32|32@1+ (1,0) [0|4294967295] "" Vector__XXX
 SG_ VCSEC_NFCAuthFromBPillarFormFact m5 : 56|3@1+ (1,0) [0|7] "" Vector__XXX
 SG_ VCSEC_NFCAuthFromCenterConsoleFo m5 : 59|3@1+ (1,0) [0|7] "" Vector__XXX

BO_ 1817 VCSEC_debug100ms: 8 VCSEC
 SG_ VCSEC_debug100msIndex M : 0|5@1+ (1,0) [0|31] "" Vector__XXX
 SG_ VCSEC_walkAwayLockKeyState m0 : 5|2@1+ (1,0) [0|3] "" Vector__XXX
 SG_ VCSEC_thresholdOffsetVersion m0 : 8|3@1+ (1,0) [0|7] "" Vector__XXX
 SG_ VCSEC_walkAwayLockState m0 : 11|3@1+ (1,0) [0|7] "" Vector__XXX
 SG_ VCSEC_rssi0WLEntry m0 : 16|5@1+ (1,0) [0|31] "" Vector__XXX
 SG_ VCSEC_endpointLayout m0 : 21|2@1+ (1,0) [0|3] "" Vector__XXX
 SG_ VCSEC_rssi1WLEntry m0 : 24|5@1+ (1,0) [0|31] "" Vector__XXX
 SG_ VCSEC_rssi2WLEntry m0 : 32|5@1+ (1,0) [0|31] "" Vector__XXX
 SG_ VCSEC_walkUpUnlockState m0 : 37|3@1+ (1,0) [0|7] "" Vector__XXX
 SG_ VCSEC_algoHighThreshLeft m0 : 40|1@1+ (1,0) [0|1] "" Vector__XXX
 SG_ VCSEC_algoHighThreshRight m0 : 41|1@1+ (1,0) [0|1] "" Vector__XXX
 SG_ VCSEC_algoHighThreshCenter m0 : 42|1@1+ (1,0) [0|1] "" Vector__XXX
 SG_ VCSEC_pollingReason m0 : 43|4@1+ (1,0) [0|15] "" Vector__XXX
 SG_ VCSEC_numberOfPubKeysOnWhitelist m0 : 56|5@1+ (1,0) [0|31] "" Vector__XXX
 SG_ VCSEC_thermalDetectState m0 : 61|2@1+ (1,0) [0|3] "" Vector__XXX
 SG_ VCSEC_connection0BondingState m7 : 8|4@1+ (1,0) [0|15] "" Vector__XXX
 SG_ VCSEC_connection1BondingState m7 : 12|4@1+ (1,0) [0|15] "" Vector__XXX
 SG_ VCSEC_connection2BondingState m7 : 16|4@1+ (1,0) [0|15] "" Vector__XXX
 SG_ VCSEC_connection0UWBAvailability m7 : 24|5@1+ (1,0) [0|31] "" Vector__XXX
 SG_ VCSEC_connection1UWBAvailability m7 : 32|5@1+ (1,0) [0|31] "" Vector__XXX
 SG_ VCSEC_connection2UWBAvailability m7 : 40|5@1+ (1,0) [0|31] "" Vector__XXX
 SG_ VCSEC_NISessionStateCenter0 m8 : 8|5@1+ (1,0) [0|31] "" Vector__XXX
 SG_ VCSEC_NISessionStateLeft0 m8 : 16|5@1+ (1,0) [0|31] "" Vector__XXX
 SG_ VCSEC_NISessionStateRight0 m8 : 24|5@1+ (1,0) [0|31] "" Vector__XXX
 SG_ VCSEC_NISessionStateRearLeft0 m8 : 29|5@1+ (1,0) [0|31] "" Vector__XXX
 SG_ VCSEC_NISessionStateRearRight0 m8 : 34|5@1+ (1,0) [0|31] "" Vector__XXX
 SG_ VCSEC_NISessionStateRear0 m8 : 39|5@1+ (1,0) [0|31] "" Vector__XXX
 SG_ VCSEC_NISessionStateCenter1 m8 : 44|5@1+ (1,0) [0|31] "" Vector__XXX
 SG_ VCSEC_NISessionStateLeft1 m8 : 49|5@1+ (1,0) [0|31] "" Vector__XXX
 SG_ VCSEC_NISessionStateRight1 m8 : 54|5@1+ (1,0) [0|31] "" Vector__XXX
 SG_ VCSEC_NISessionStateRearLeft1 m8 : 59|5@1+ (1,0) [0|31] "" Vector__XXX
 SG_ VCSEC_NISessionStateRearRight1 m9 : 8|5@1+ (1,0) [0|31] "" Vector__XXX
 SG_ VCSEC_NISessionStateRear1 m9 : 16|5@1+ (1,0) [0|31] "" Vector__XXX
 SG_ VCSEC_NISessionStateCenter2 m9 : 24|5@1+ (1,0) [0|31] "" Vector__XXX
 SG_ VCSEC_NISessionStateLeft2 m9 : 32|5@1+ (1,0) [0|31] "" Vector__XXX
 SG_ VCSEC_NISessionStateRight2 m9 : 40|5@1+ (1,0) [0|31] "" Vector__XXX
 SG_ VCSEC_NISessionStateRearLeft2 m9 : 48|5@1+ (1,0) [0|31] "" Vector__XXX
 SG_ VCSEC_NISessionStateRearRight2 m9 : 53|5@1+ (1,0) [0|31] "" Vector__XXX
 SG_ VCSEC_NISessionStateRear2 m9 : 58|5@1+ (1,0) [0|31] "" Vector__XXX

BO_ 1655 VC_LVBMS_statusHigh: 8 VC
 SG_ VC_lvbmsStatusHighIndex M : 0|3@1+ (1,0) [0|7] "" Vector__XXX
 SG_ VC_LVBMS_packCurrent m0 : 3|22@1+ (0.001,-2000) [-2000|2194.302] "A" Vector__XXX
 SG_ VC_LVBMS_packVoltage m0 : 25|16@1+ (0.001,0) [0|65.534] "V" Vector__XXX
 SG_ VC_LVBMS_packTemperature m0 : 41|9@1+ (0.5,-50) [-50|205] "degC" Vector__XXX
 SG_ VC_LVBMS_MOSTemperature m0 : 50|12@1+ (0.5,-50) [-50|1997] "degC" Vector__XXX
 SG_ VC_LVBMS_sumCellVoltage m1 : 8|16@1+ (0.001,0) [0|65.534] "V" Vector__XXX
 SG_ VC_LVBMS_maxBrickVoltage m1 : 24|13@1+ (0.001,0) [0|8.19] "V" Vector__XXX
 SG_ VC_LVBMS_maxBrickVoltageIndex m1 : 40|8@1+ (1,0) [0|254] "" Vector__XXX
 SG_ VC_LVBMS_avgBrickVoltage m2 : 3|13@1+ (0.001,0) [0|8.19] "V" Vector__XXX
 SG_ VC_LVBMS_minBrickVoltage m2 : 16|13@1+ (0.001,0) [0|8.19] "V" Vector__XXX
 SG_ VC_LVBMS_minBrickVoltageIndex m2 : 32|8@1+ (1,0) [0|254] "" Vector__XXX
 SG_ VC_LVBMS_voltageTarget m3 : 3|16@1+ (0.001,0) [0|65.534] "V" Vector__XXX
 SG_ VC_LVBMS_currentTarget m3 : 19|17@1+ (0.001,-61) [-61|70.07] "A" Vector__XXX
 SG_ VC_LVBMS_maxAllowedChargeCurrent m3 : 36|13@1+ (0.1,0) [0|819] "A" Vector__XXX
 SG_ VC_LVBMS_maxAllowedDischargeCurr m3 : 49|13@1+ (0.1,0) [0|819] "A" Vector__XXX
 SG_ VC_LVBMS_MOSCommand m4 : 3|1@1+ (1,0) [0|1] "" Vector__XXX
 SG_ VC_LVBMS_ClearErrorCntrCommand m4 : 4|1@1+ (1,0) [0|1] "" Vector__XXX
 SG_ VC_LVBMS_ClearHistoricFaultComma m4 : 5|1@1+ (1,0) [0|1] "" Vector__XXX
 SG_ VC_LVBMS_ResetLVBMSCommand m4 : 6|1@1+ (1,0) [0|1] "" Vector__XXX
 SG_ VC_LVBMS_EnterHibernationCommand m4 : 7|1@1+ (1,0) [0|1] "" Vector__XXX
 SG_ VC_LVBMS_ECPAState m4 : 8|2@1+ (1,0) [0|2] "" Vector__XXX
 SG_ VC_LVBMS_MOSState m4 : 10|2@1+ (1,0) [0|2] "" Vector__XXX
 SG_ VC_LVBMS_VehicleState m4 : 12|2@1+ (1,0) [0|3] "" Vector__XXX
 SG_ VC_LVBMS_LINWakeDisabled m4 : 14|1@1+ (1,0) [0|1] "" Vector__XXX
 SG_ VC_LVBMS_chargeType m4 : 16|3@1+ (1,0) [0|7] "" Vector__XXX
 SG_ VC_LVBMS_cellAndArcProtEnabled m4 : 19|1@1+ (1,0) [0|1] "" Vector__XXX
 SG_ VC_totalLVLoadCurrent m5 : 8|14@1- (0.1,0) [-200|400] "A" Vector__XXX
 SG_ VC_LVPackChargeCurrentLimit m5 : 22|12@1+ (0.1,0) [0|400] "A" Vector__XXX
 SG_ VC_LVPackCurrent m5 : 34|14@1- (0.1,0) [-200|400] "A" Vector__XXX
 SG_ VC_LVBMS_estimatedPackOcv m5 : 48|16@1+ (0.001,0) [0|65.535] "V" Vector__XXX

BO_ 1816 VC_LVBMS_statusLow: 7 VC
 SG_ VC_lvbmsStatusLowIndex M : 0|3@1+ (1,0) [0|7] "" Vector__XXX
 SG_ VC_LVBMS_SOC m0 : 8|7@1+ (1,0) [0|102.2] "%" Vector__XXX
 SG_ VC_LVBMS_SOE m0 : 16|7@1+ (1,0) [0|126] "%" Vector__XXX
 SG_ VC_LVBMS_SOH m0 : 24|7@1+ (1,0) [0|126] "%" Vector__XXX
 SG_ VC_LVBMS_SOP m0 : 32|24@1+ (0.001,0) [0|5080] "W" Vector__XXX
 SG_ VC_LVBMS_AvgSleepCurrent m1 : 8|16@1+ (0.01,-200) [-200|455.34] "A" Vector__XXX
 SG_ VC_LVBMS_TimeSlept m1 : 24|24@1+ (1,0) [0|16777214] "min" Vector__XXX
 SG_ VC_LVBMS_AhCharged m2 : 8|32@1+ (0.001,0) [0|4294967.294] "Ah" Vector__XXX
 SG_ VC_LVBMS_MinSleepCurrent m2 : 40|16@1+ (0.01,-200) [-200|455.34] "A" Vector__XXX
 SG_ VC_LVBMS_AhDischarged m3 : 8|32@1+ (0.001,0) [0|4294967.294] "Ah" Vector__XXX
 SG_ VC_LVBMS_MaxSleepCurrent m3 : 40|16@1+ (0.01,-200) [-200|455.34] "A" Vector__XXX
 SG_ VC_LVBMS_sumCellVoltageFiltered m4 : 8|16@1+ (0.001,0) [0|65.534] "V" Vector__XXX
 SG_ VC_LVBMS_maxCellSOC m4 : 24|7@1+ (1,0) [0|102.2] "%" Vector__XXX
 SG_ VC_LVBMS_minCellSOC m4 : 32|7@1+ (1,0) [0|102.2] "%" Vector__XXX
 SG_ VC_LVBMS_staticSOCCorrection m4 : 39|1@1+ (1,0) [0|1] "" Vector__XXX
 SG_ VC_LVBMS_dynamicSOCCorrection m4 : 40|1@1+ (1,0) [0|1] "" Vector__XXX
 SG_ VC_LVBMS_usableEnergyAvailable m4 : 41|12@1+ (1,0) [0|4000] "Wh" Vector__XXX
 SG_ VC_LVBMS_CellOVLevel1 m5 : 3|1@1+ (1,0) [0|1] "" Vector__XXX
 SG_ VC_LVBMS_CellOVLevel2 m5 : 4|1@1+ (1,0) [0|1] "" Vector__XXX
 SG_ VC_LVBMS_CellOVLevel3 m5 : 5|1@1+ (1,0) [0|1] "" Vector__XXX
 SG_ VC_LVBMS_CellUVLevel1 m5 : 6|1@1+ (1,0) [0|1] "" Vector__XXX
 SG_ VC_LVBMS_CellUVLevel2 m5 : 7|1@1+ (1,0) [0|1] "" Vector__XXX
 SG_ VC_LVBMS_ModuleOTLevel1 m5 : 8|1@1+ (1,0) [0|1] "" Vector__XXX
 SG_ VC_LVBMS_PackOVLevel1 m5 : 9|1@1+ (1,0) [0|1] "" Vector__XXX
 SG_ VC_LVBMS_PackOVLevel2 m5 : 10|1@1+ (1,0) [0|1] "" Vector__XXX
 SG_ VC_LVBMS_DischrgOCLevel1 m5 : 11|1@1+ (1,0) [0|1] "" Vector__XXX
 SG_ VC_LVBMS_DischrgOCLevel2 m5 : 12|1@1+ (1,0) [0|1] "" Vector__XXX
 SG_ VC_LVBMS_ChrgOCLevel1 m5 : 13|1@1+ (1,0) [0|1] "" Vector__XXX
 SG_ VC_LVBMS_ChrgOCLevel2 m5 : 14|1@1+ (1,0) [0|1] "" Vector__XXX
 SG_ VC_LVBMS_MOSFETOTLevel1 m5 : 15|1@1+ (1,0) [0|1] "" Vector__XXX
 SG_ VC_LVBMS_KBValueLostFault m5 : 16|1@1+ (1,0) [0|1] "" Vector__XXX
 SG_ VC_LVBMS_BalanceCircuitFault m5 : 17|1@1+ (1,0) [0|1] "" Vector__XXX
 SG_ VC_LVBMS_MOSStateFault m5 : 18|1@1+ (1,0) [0|1] "" Vector__XXX
 SG_ VC_LVBMS_NTCTempDiffWarnLevel1 m5 : 19|1@1+ (1,0) [0|1] "" Vector__XXX
 SG_ VC_LVBMS_DeepDischargeFlag m5 : 20|1@1+ (1,0) [0|1] "" Vector__XXX
 SG_ VC_LVBMS_SamplingError m5 : 21|1@1+ (1,0) [0|1] "" Vector__XXX
 SG_ VC_LVBMS_MosfetStuckCloseError m5 : 22|1@1+ (1,0) [0|1] "" Vector__XXX
 SG_ VC_LVBMS_MosfetStuckOpenError m5 : 23|1@1+ (1,0) [0|1] "" Vector__XXX

BO_ 1089 VC_pcsInterface: 8 VC
 SG_ VC_pcsInterfaceMuxIndex M : 48|1@1+ (1,0) [0|1] "" Vector__XXX
 SG_ VC_pcsInterfaceCounter : 50|4@1+ (1,0) [0|15] "" Vector__XXX
 SG_ VC_pcsInterfaceChecksum : 56|8@1+ (1,0) [0|255] "" Vector__XXX
 SG_ VC_pcsLVVoltageTarget m0 : 0|13@1+ (0.01,0) [0|65.535] "V" Vector__XXX
 SG_ VC_pcsLVMinVoltageLimit m0 : 13|13@1+ (0.01,0) [0|65.535] "V" Vector__XXX
 SG_ VC_pcsLVMaxVoltageLimit m0 : 27|13@1+ (0.01,0) [0|65.535] "V" Vector__XXX
 SG_ VC_goodForPCSPowerCycle m0 : 46|1@1+ (1,0) [0|1] "" Vector__XXX
 SG_ VC_LVBatteryCannotSupportVehicle m0 : 47|1@1+ (1,0) [0|1] "" Vector__XXX
 SG_ VC_pcsResistanceFiltered m1 : 0|16@1+ (0.01,0) [0|655.34] "mOhm" Vector__XXX
 SG_ VC_pcsLVMaxDchrgCurrentLimit m1 : 16|12@1+ (0.1,0) [0|400] "A" Vector__XXX
 SG_ VC_defaultPcsLVVoltageTarget m1 : 28|13@1+ (0.01,0) [0|65.535] "V" Vector__XXX
 SG_ VC_lvHwProtSelfTestActive m1 : 41|1@1+ (1,0) [0|1] "" Vector__XXX

BO_TX_BU_ 691 : VCRIGHT;
BO_TX_BU_ 1862 : VCRIGHT;
BO_TX_BU_ 1251 : VCRIGHT;
BO_TX_BU_ 739 : VCRIGHT;
BO_TX_BU_ 835 : VCRIGHT;
BO_TX_BU_ 963 : VCRIGHT;
BO_TX_BU_ 537 : VCSEC;
BO_TX_BU_ 570 : VCSEC;
BO_TX_BU_ 1067 : VCSEC;
BO_TX_BU_ 761 : VCSEC;
BO_TX_BU_ 1817 : VCSEC;
BO_TX_BU_ 1655 : VC;
BO_TX_BU_ 1816 : VC;
BO_TX_BU_ 1089 : VC;
CM_ BO_ 691 "Right body controller message: logging1 hz";
CM_ SG_ 691 VCRIGHT_logging1HzIndex "Right body controller: logging1 hz index";
CM_ SG_ 691 VCRIGHT_tempIncarCabinProbe "Right body controller: temp incar cabin probe; raw 255 = signal not available (SNA)";
CM_ SG_ 691 VCRIGHT_tempIncarCabinDeep "Right body controller: temp incar cabin deep; raw 255 = signal not available (SNA)";
CM_ SG_ 691 VCRIGHT_cabinTempInteriorL2 "Right body controller: cabin temp interior L2; raw 255 = signal not available (SNA)";
CM_ SG_ 691 VCRIGHT_tempIncarCabinMid "Right body controller: temp incar cabin mid; raw 250 = signal not available (SNA)";
CM_ SG_ 691 VCRIGHT_cabinTempInteriorSunnyL2 "Right body controller: cabin temp interior sunny L2; raw 255 = signal not available (SNA)";
CM_ SG_ 691 VCRIGHT_cabinTempInteriorL3 "Right body controller: cabin temp interior L3; raw 255 = signal not available (SNA)";
CM_ SG_ 691 VCRIGHT_cabinTempInteriorSunnyL3 "Right body controller: cabin temp interior sunny L3; raw 255 = signal not available (SNA)";
CM_ SG_ 691 VCRIGHT_cabinTempGlassRoof "Modeled cabin temperature near the glass roof; raw 255 = signal not available (SNA)";
CM_ SG_ 691 VCRIGHT_cabinTempWindshield "Windshield temperature estimate; raw 255 = signal not available (SNA)";
CM_ SG_ 691 VCRIGHT_cabinTempInterior "Modeled interior cabin temperature; raw 255 = signal not available (SNA)";
CM_ SG_ 691 VCRIGHT_cabinTempInteriorSunny "Modeled interior surface temperature exposed to direct sunlight; raw 255 = signal not available (SNA)";
CM_ SG_ 691 VCRIGHT_cabinTempSideGlassLeft "Modeled glass temperature left; raw 255 = signal not available (SNA)";
CM_ SG_ 691 VCRIGHT_cabinTempSideGlassRight "Modeled glass temperature right; raw 255 = signal not available (SNA)";
CM_ SG_ 691 VCRIGHT_cabinTempBreathLevel "Modeled cabin temperature near occupant breathing level; raw 255 = signal not available (SNA)";
CM_ SG_ 691 VCRIGHT_pcbaTemperature "Right body controller: pcba temperature";
CM_ SG_ 691 VCRIGHT_wattsHeaterLeftTotal "Right body controller: watts heater left total";
CM_ SG_ 691 VCRIGHT_wattsHeaterRightTotal "Right body controller: watts heater right total";
CM_ SG_ 691 VCRIGHT_qdotLeftFFUnsat "Right body controller: qdot left FF unsat";
CM_ SG_ 691 VCRIGHT_qdotRightFFUnsat "Right body controller: qdot right FF unsat";
CM_ SG_ 691 VCRIGHT_nvhLevelDb "Right body controller: nvh level db";
CM_ SG_ 691 VCRIGHT_hvacSetTempActualLeft "HVAC internal left temperature set point";
CM_ SG_ 691 VCRIGHT_hvacSetTempActualRight "HVAC internal right temperature set point";
CM_ SG_ 691 VCRIGHT_hvacAutoTransitionReason "Reason for airflow mode change when system is operating in auto";
CM_ SG_ 691 VCRIGHT_hvacMassflowTarget "Right body controller: hvac massflow target";
CM_ SG_ 691 VCRIGHT_hvacQdotLimitedLeft "Right body controller: hvac qdot limited left";
CM_ SG_ 691 VCRIGHT_hvacQdotLimitedRight "Right body controller: hvac qdot limited right";
CM_ SG_ 691 VCRIGHT_LHPanelAirflowBlocked "Right body controller: LH panel airflow blocked";
CM_ SG_ 691 VCRIGHT_RHPanelAirflowBlocked "Right body controller: RH panel airflow blocked";
CM_ SG_ 691 VCRIGHT_floorAirflowBlocked "Right body controller: floor airflow blocked";
CM_ SG_ 691 VCRIGHT_defrostAirflowBlocked "Right body controller: defrost airflow blocked";
CM_ SG_ 691 VCRIGHT_hvacFilterLifeDetectActi "Indicates when filter life detection is active";
CM_ SG_ 691 VCRIGHT_hvacLHBleedOperationMode "Right body controller: hvac LH bleed operation mode";
CM_ SG_ 691 VCRIGHT_hvacRHBleedOperationMode "Right body controller: hvac RH bleed operation mode";
CM_ SG_ 691 VCRIGHT_hvacLHVaneOperationMode "Right body controller: hvac LH vane operation mode";
CM_ SG_ 691 VCRIGHT_hvacRHVaneOperationMode "Right body controller: hvac RH vane operation mode";
CM_ SG_ 691 VCRIGHT_hvacUpperModeOpMode "Right body controller: hvac upper mode op mode";
CM_ SG_ 691 VCRIGHT_hvacLowerModeOpMode "Right body controller: hvac lower mode op mode";
CM_ SG_ 691 VCRIGHT_hvacIntakeOperationMode "Right body controller: hvac intake operation mode";
CM_ SG_ 691 VCRIGHT_isProbeFeedbackApplied "Right body controller: is probe feedback applied";
CM_ SG_ 691 VCRIGHT_feedbackPullDownScalar "Right body controller: feedback pull down scalar";
CM_ SG_ 691 VCRIGHT_feedForwardPullDownScala "Right body controller: feed forward pull down scalar";
CM_ SG_ 691 VCRIGHT_convectionTargetLeft "Right body controller: convection target left; raw 511 = signal not available (SNA)";
CM_ SG_ 691 VCRIGHT_convectionTargetRight "Right body controller: convection target right; raw 511 = signal not available (SNA)";
CM_ SG_ 691 VCRIGHT_convectionDeliveredLeft "Right body controller: convection delivered left; raw 511 = signal not available (SNA)";
CM_ SG_ 691 VCRIGHT_convectionDeliveredRight "Right body controller: convection delivered right; raw 511 = signal not available (SNA)";
CM_ SG_ 691 VCRIGHT_solarLoadRightOccupant "Right body controller: solar load right occupant; raw 127 = signal not available (SNA)";
CM_ SG_ 691 VCRIGHT_solarLoadLeftOccupant "Right body controller: solar load left occupant; raw 127 = signal not available (SNA)";
CM_ SG_ 691 VCRIGHT_ptcShutOutletMitigationA "Right body controller: ptc shut outlet mitigation active";
CM_ SG_ 691 VCRIGHT_solarLoadFromThsTemp "Right body controller: solar load from ths temp; raw 255 = signal not available (SNA)";
CM_ SG_ 691 VCRIGHT_ptcHeaterTempDuctHigh "Right body controller: ptc heater temp duct high";
CM_ SG_ 691 VCRIGHT_ptcHeaterTempDuctFault "Right body controller: ptc heater temp duct fault";
CM_ SG_ 691 VCRIGHT_ptcHeaterNoAirflow "Right body controller: ptc heater no airflow";
CM_ SG_ 691 VCRIGHT_ptcHeaterHvacActNotReady "Right body controller: ptc heater hvac act not ready";
CM_ SG_ 691 VCRIGHT_ptcHeaterNoUiRequest "Right body controller: ptc heater no ui request";
CM_ SG_ 691 VCRIGHT_ptcHeaterNoHighVoltage "Right body controller: ptc heater no high voltage";
CM_ SG_ 691 VCRIGHT_ptcHeaterLAirPathBlocked "Right body controller: ptc heater l air path blocked";
CM_ SG_ 691 VCRIGHT_ptcHeaterRAirPathBlocked "Right body controller: ptc heater r air path blocked";
CM_ SG_ 691 VCRIGHT_ptcHeaterReqAirpathBlock "Right body controller: ptc heater req airpath blocked";
CM_ SG_ 691 VCRIGHT_hvacQdotFeedforward "Right body controller: hvac qdot feedforward";
CM_ SG_ 691 VCRIGHT_evapLoadInFresh "Right body controller: evap load in fresh";
CM_ SG_ 691 VCRIGHT_evapLoadInRecirc "Right body controller: evap load in recirc";
CM_ SG_ 691 VCRIGHT_cabinTempWshldDefog "Windshield temperature estimate used for defogging; raw 255 = signal not available (SNA)";
CM_ SG_ 691 VCRIGHT_cabinTempWshldDefogTop "Right body controller: cabin temp wshld defog top; raw 255 = signal not available (SNA)";
CM_ SG_ 691 VCRIGHT_hvacLHBleedVoltage "Right body controller: hvac LH bleed voltage";
CM_ SG_ 691 VCRIGHT_hvacRHBleedVoltage "Right body controller: hvac RH bleed voltage";
CM_ SG_ 691 VCRIGHT_hvacLHVaneVoltage "Right body controller: hvac LH vane voltage";
CM_ SG_ 691 VCRIGHT_hvacRHVaneVoltage "Right body controller: hvac RH vane voltage";
CM_ SG_ 691 VCRIGHT_hvacUpperModeVoltage "Right body controller: hvac upper mode voltage";
CM_ SG_ 691 VCRIGHT_hvacLowerModeVoltage "Right body controller: hvac lower mode voltage";
CM_ SG_ 691 VCRIGHT_hvacIntakeVoltage "Right body controller: hvac intake voltage";
CM_ SG_ 691 VCRIGHT_cabinTempBreathLevelFHea "Right body controller: cabin temp breath level f heating; raw 255 = signal not available (SNA)";
CM_ SG_ 691 VCRIGHT_cabinTempBreathLevelFCoo "Right body controller: cabin temp breath level f cooling; raw 255 = signal not available (SNA)";
CM_ SG_ 691 VCRIGHT_cabinTempBreathLeve_0002 "Right body controller: cabin temp breath level f5min heating; raw 255 = signal not available (SNA)";
CM_ SG_ 691 VCRIGHT_cabinTempBreathLevelF5mi "Right body controller: cabin temp breath level f5min cooling; raw 255 = signal not available (SNA)";
CM_ SG_ 691 VCRIGHT_cabinTempBreathLeve_0001 "Right body controller: cabin temp breath level f10min heating; raw 255 = signal not available (SNA)";
CM_ SG_ 691 VCRIGHT_cabinTempBreathLevelF10m "Right body controller: cabin temp breath level f10min cooling; raw 255 = signal not available (SNA)";
CM_ SG_ 691 VCRIGHT_cabinTempInteriorFHeatin "Right body controller: cabin temp interior f heating; raw 255 = signal not available (SNA)";
CM_ SG_ 691 VCRIGHT_hvacCabOvrheatProtActive "Status of cabin overheat protection";
CM_ SG_ 691 VCRIGHT_hvacCabinPurgeAllowed "Right body controller: hvac cabin purge allowed";
CM_ SG_ 691 VCRIGHT_hvacCabOvrheatProtAllowe "Cabin overheat protection is allowed to run";
CM_ SG_ 691 VCRIGHT_filterLifeBlowerTorque "Right body controller: filter life blower torque; raw 1023 = signal not available (SNA)";
CM_ SG_ 691 VCRIGHT_cabinTempFanCurrent "Right body controller: cabin temp fan current";
CM_ SG_ 691 VCRIGHT_cabinTempFanOutput "Right body controller: cabin temp fan output";
CM_ SG_ 691 VCRIGHT_cloudinessEstimatedPct "Right body controller: cloudiness estimated pct";
CM_ SG_ 691 VCRIGHT_solarLoadOnVehFiltered "Right body controller: solar load on veh filtered; raw 255 = signal not available (SNA)";
CM_ SG_ 691 VCRIGHT_cabinTempProbeEstimate "Right body controller: cabin temp probe estimate; raw 255 = signal not available (SNA)";
CM_ SG_ 691 VCRIGHT_cabinTempThs "Estimated temperature from Tesla HVAC Sensor; raw 255 = signal not available (SNA)";
CM_ SG_ 691 VCRIGHT_cabinTempThsBracket "Right body controller: cabin temp ths bracket; raw 255 = signal not available (SNA)";
CM_ SG_ 691 VCRIGHT_leftHeatOvertempProtect "Right body controller: left heat overtemp protect";
CM_ SG_ 691 VCRIGHT_rightHeatOvertempProtect "Right body controller: right heat overtemp protect";
CM_ SG_ 691 VCRIGHT_CO2ppm "Right body controller: co2ppm; raw 1023 = signal not available (SNA)";
CM_ SG_ 691 VCRIGHT_timeLeftToCabinModelInit "Right body controller: time left to cabin model init";
CM_ SG_ 691 VCRIGHT_hvacEstimateWindshieldRH "Estimated windshield relative humidity";
CM_ SG_ 691 VCRIGHT_hvacFoggingRiskLevel "Control signal of the windshield fogging risk controller";
CM_ SG_ 691 VCRIGHT_hvacCabinHumidityLevel "Control signal of the cabin humidity controller";
CM_ SG_ 691 VCRIGHT_hvacFlashFoggingDetected "Windshield flash fogging risk detected";
CM_ SG_ 691 VCRIGHT_solarSensitivityInfr "Right body controller: solar sensitivity infr";
CM_ SG_ 691 VCRIGHT_solarSensitivityInfrCorr "Right body controller: solar sensitivity infr corr";
CM_ SG_ 691 VCRIGHT_lumbarCurrent "Electrical current of the lumbar ECU";
CM_ SG_ 691 VCRIGHT_ocsCurrent "Electrical current of the OCS ECU";
CM_ SG_ 691 VCRIGHT_rcmCurrent "Electrical current of the RCM ECU";
CM_ SG_ 691 VCRIGHT_radioTunerCurrent "Electrical current of the Radio Tuner";
CM_ SG_ 691 VCRIGHT_rearOilPumpCurrent "Right body controller: rear oil pump current";
CM_ SG_ 691 VCRIGHT_rearDefrostCurrent "Right body controller: rear defrost current";
CM_ SG_ 691 VCRIGHT_tailLightCurrent "Electrical current of the tail and license plate lights";
CM_ SG_ 691 VCRIGHT_turnTailStopLightCurrent "Reports the electrical current of the right rear turn indicator, right rear tail light, or right rear brake light";
CM_ SG_ 691 VCRIGHT_reverseFogLightsCurrent "Electrical current of the trunk fog light; raw 15 = signal not available (SNA)";
CM_ SG_ 691 VCRIGHT_stopReverseTurnLightCurr "Reports the electrical current of the right rear brake light, right rear reverse light, or right rear turn indicator";
CM_ SG_ 691 VCRIGHT_sideMirrorCurrent "Electrical current of side mirror tilt and fold";
CM_ SG_ 691 VCRIGHT_sideMirrorHeaterCurrent "Electrical current of the mirror heater; raw 31 = signal not available (SNA)";
CM_ SG_ 691 VCRIGHT_frontSeatHeatCushionPwr "Right body controller: front seat heat cushion pwr";
CM_ SG_ 691 VCRIGHT_trunkInteriorLEDCurrent "Electrical current of the trunk interior light; raw 15 = signal not available (SNA)";
CM_ SG_ 691 VCRIGHT_mapPocketLEDsCurrent "Electrical current of the map pocket lights; raw 15 = signal not available (SNA)";
CM_ SG_ 691 VCRIGHT_miscEFuseCurrent "Right body controller: misc e fuse current; raw 31 = signal not available (SNA)";
CM_ SG_ 691 VCRIGHT_interiorHandleLEDCurrent "Electrical current of the interior handle LED";
CM_ SG_ 691 VCRIGHT_miscInteriorLightsCurren "Electrical current of the misc interior lights; raw 7 = signal not available (SNA)";
CM_ SG_ 691 VCRIGHT_frontPuddleLEDCurrent "Electrical current of the front puddle LED; raw 7 = signal not available (SNA)";
CM_ SG_ 691 VCRIGHT_rearPuddleLEDCurrent "Electrical current of the rear puddle LED; raw 7 = signal not available (SNA)";
CM_ SG_ 691 VCRIGHT_liftgateShutfaceLEDCurre "Electrical current of the liftgate shutface LED; raw 7 = signal not available (SNA)";
CM_ SG_ 691 VCRIGHT_3rSeatTOSCurrent "Electrical current of the 3R TOS; raw 15 = signal not available (SNA)";
CM_ SG_ 691 VCRIGHT_vbatFusedCurrent "Right body controller: vbat fused current; raw 15 = signal not available (SNA)";
CM_ SG_ 691 VCRIGHT_cabinTempGlassGridHeater "Right body controller: cabin temp glass grid heater; raw 255 = signal not available (SNA)";
CM_ SG_ 691 VCRIGHT_hvacAirflowReasonRight "Right body controller: hvac airflow reason right";
CM_ SG_ 691 VCRIGHT_hvacAirflowReasonLeft "Right body controller: hvac airflow reason left";
CM_ SG_ 691 VCRIGHT_hvacMassflowTargetLeft "Right body controller: hvac massflow target left";
CM_ SG_ 691 VCRIGHT_hvacMassflowTargetRight "Right body controller: hvac massflow target right";
CM_ SG_ 691 VCRIGHT_solarLoadLeftOccupantFil "Right body controller: solar load left occupant filt; raw 127 = signal not available (SNA)";
CM_ SG_ 691 VCRIGHT_solarLoadRightOccupantFi "Right body controller: solar load right occupant filt; raw 127 = signal not available (SNA)";
CM_ SG_ 691 VCRIGHT_windshieldRHCapped "Estimated windshield relative humidity";
CM_ SG_ 691 VCRIGHT_feedbackWarmUpScalar "Right body controller: feedback warm up scalar";
CM_ SG_ 691 VCRIGHT_maxMassflowScalarWarmUp "Right body controller: max massflow scalar warm up";
CM_ SG_ 691 VCRIGHT_feedforwardWarmUpScalar "Right body controller: feedforward warm up scalar";
CM_ SG_ 691 VCRIGHT_frontSeatHeatBackrestPwr "Right body controller: front seat heat backrest pwr";
CM_ SG_ 691 VCRIGHT_maxMassflowScalar "Right body controller: max massflow scalar";
CM_ SG_ 691 VCRIGHT_massflowTargetAutoInManu "Right body controller: massflow target auto in manual mode";
CM_ SG_ 691 VCRIGHT_airflowReasonAutoInManua "Right body controller: airflow reason auto in manual mode";
CM_ SG_ 691 VCRIGHT_airflowReasonAutoIn_0001 "Right body controller: airflow reason auto in manual mode left";
CM_ SG_ 691 VCRIGHT_airflowReasonAutoIn_0002 "Right body controller: airflow reason auto in manual mode right";
CM_ SG_ 691 VCRIGHT_cabinTempInteriorFCoolin "Right body controller: cabin temp interior f cooling; raw 255 = signal not available (SNA)";
CM_ SG_ 691 VCRIGHT_averageDuctTempFHeating "Estimated average duct temp temp 15 min into the drive; raw 255 = signal not available (SNA)";
CM_ SG_ 691 VCRIGHT_averageDuctTempFCooling "Estimated average duct temp temp 15 min into the drive; raw 255 = signal not available (SNA)";
CM_ SG_ 691 VCRIGHT_hvacBiLevelWhsldRhEst "Right body controller: hvac bi level whsld rh est";
CM_ SG_ 691 VCRIGHT_steeringWheelSurfaceTemp "Right body controller: steering wheel surface temp est; raw 1023 = signal not available (SNA)";
CM_ SG_ 691 VCRIGHT_steeringWheelSurfac_0001 "Right body controller: steering wheel surface temp tgt; raw 1023 = signal not available (SNA)";
CM_ SG_ 691 VCRIGHT_timeToComfortHeating "Right body controller: time to comfort heating";
CM_ SG_ 691 VCRIGHT_timeToComfortCooling "Right body controller: time to comfort cooling";
CM_ SG_ 691 VCRIGHT_cabinWaterMassRaw "Right body controller: cabin water mass raw; raw 255 = signal not available (SNA)";
CM_ SG_ 691 VCRIGHT_massflowSingleZoneSplit "Right body controller: massflow single zone split";
CM_ SG_ 691 VCRIGHT_VOCPurgeState "Right body controller: VOC purge state";
CM_ SG_ 691 VCRIGHT_cameraFoggingMonitorStat "Right body controller: camera fogging monitor state";
CM_ SG_ 691 VCRIGHT_cabinOverheatProtectNotR "Reports all reasons cabin overheat protection is not running.";
CM_ SG_ 691 VCRIGHT_hvacIntakeReason "Reason for current intake door position";
CM_ SG_ 691 VCRIGHT_hvacCabinPurgeActive "Indicates if cabin purge is active";
CM_ SG_ 691 VCRIGHT_solarAzimuthCarRef "Right body controller: solar azimuth car ref; raw 1025 = signal not available (SNA)";
CM_ SG_ 691 VCRIGHT_massflowPulldownBias "Right body controller: massflow pulldown bias";
CM_ SG_ 691 VCRIGHT_evapPulldownBias "Right body controller: evap pulldown bias";
CM_ SG_ 691 VCRIGHT_modeledMassflowFresh "Right body controller: modeled massflow fresh";
CM_ SG_ 691 VCRIGHT_modeledMassflowRecirc "Right body controller: modeled massflow recirc";
CM_ SG_ 691 VCRIGHT_hvacLimpModeStatus "Reports the cabin model limp mode status.";
CM_ SG_ 691 VCRIGHT_hvacEstimatedCameraWinds "Right body controller: hvac estimated camera windshield RH";
CM_ BO_ 1862 "Right body controller message: restraint status";
CM_ SG_ 1862 VCRIGHT_frontOccupancyStatus "Right body controller: front occupancy status; raw 7 = signal not available (SNA)";
CM_ SG_ 1862 VCRIGHT_frontBuckleStatus "Status of front right seatbelt buckle; raw 3 = signal not available (SNA)";
CM_ SG_ 1862 VCRIGHT_rearCenterBuckleStatus "Right body controller: rear center buckle status; raw 3 = signal not available (SNA)";
CM_ SG_ 1862 VCRIGHT_rearRightBuckleStatus "Right body controller: rear right buckle status; raw 3 = signal not available (SNA)";
CM_ SG_ 1862 VCRIGHT_rearRightOccupancyStatus "Right body controller: rear right occupancy status; raw 3 = signal not available (SNA)";
CM_ SG_ 1862 VCRIGHT_3RowLeftBuckleStatus "Status of third row left seatbelt buckle; raw 3 = signal not available (SNA)";
CM_ SG_ 1862 VCRIGHT_3RowRightBuckleStatus "Right body controller: 3 row right buckle status; raw 3 = signal not available (SNA)";
CM_ SG_ 1862 VCRIGHT_3RowLeftOccupancyStatus "Right body controller: 3 row left occupancy status; raw 3 = signal not available (SNA)";
CM_ SG_ 1862 VCRIGHT_3RowRightOccupancyStatus "Right body controller: 3 row right occupancy status; raw 3 = signal not available (SNA)";
CM_ SG_ 1862 VCRIGHT_seatTrackPosition "Right body controller: seat track position; raw 7 = signal not available (SNA)";
CM_ SG_ 1862 VCRIGHT_occupantClassification "Right body controller: occupant classification; raw 7 = signal not available (SNA)";
CM_ SG_ 1862 VCRIGHT_occupantClassificationQF "Right body controller: occupant classification QF";
CM_ SG_ 1862 VCRIGHT_classificationEnabled "Indicates whether the RCM should consume VCRIGHT occupant classification rather than another source such as OCS1P";
CM_ SG_ 1862 VCRIGHT_classificationEnabledQF "Indicates whether the VCRIGHT_classificationEnabled signal is valid";
CM_ SG_ 1862 VCRIGHT_restraintStatusCounter "Right body controller: restraint status counter";
CM_ SG_ 1862 VCRIGHT_restraintStatusChecksum "Right body controller: restraint status checksum";
CM_ BO_ 1251 "Right body controller message: seat status";
CM_ SG_ 1251 VCRIGHT_seatStatusIndex "Right body controller: seat status index";
CM_ SG_ 1251 VCRIGHT_frontSeatTrackPos "Motor encoder value representing front left seat track position";
CM_ SG_ 1251 VCRIGHT_frontSeatTrackCurrent "Current drawn by front left seat track motor";
CM_ SG_ 1251 VCRIGHT_frontSeatTrackDuty "Front left seat track motor duty cycle";
CM_ SG_ 1251 VCRIGHT_frontSeatTrackState "State of front right seat track motor";
CM_ SG_ 1251 VCRIGHT_frontSeatTrackCalibrated "Right body controller: front seat track calibrated";
CM_ SG_ 1251 VCRIGHT_frontSeatTrackLog "Right body controller: front seat track log";
CM_ SG_ 1251 VCRIGHT_frontSeatTrackBridgeSt "Bridge state";
CM_ SG_ 1251 VCRIGHT_frontSeatBackPos "Motor encoder value representing front right seat backrest position";
CM_ SG_ 1251 VCRIGHT_frontSeatBackCurrent "Current drawn by front right seat backrest motor";
CM_ SG_ 1251 VCRIGHT_frontSeatBackDuty "Front right seat backrest motor duty cycle";
CM_ SG_ 1251 VCRIGHT_frontSeatBackState "Active state of front right seat backrest";
CM_ SG_ 1251 VCRIGHT_frontSeatBackCalibrated "Right body controller: front seat back calibrated";
CM_ SG_ 1251 VCRIGHT_frontSeatBackLog "Right body controller: front seat back log";
CM_ SG_ 1251 VCRIGHT_frontSeatBackBridgeSt "Bridge state";
CM_ SG_ 1251 VCRIGHT_frontSeatLiftPos "Motor encoder value representing front left seat lift position";
CM_ SG_ 1251 VCRIGHT_frontSeatLiftCurrent "Current drawn by front left seat lift motor";
CM_ SG_ 1251 VCRIGHT_frontSeatLiftDuty "Front left seat lift motor duty cycle";
CM_ SG_ 1251 VCRIGHT_frontSeatLiftState "Status of front left seat motor";
CM_ SG_ 1251 VCRIGHT_frontSeatLiftCalibrated "Right body controller: front seat lift calibrated";
CM_ SG_ 1251 VCRIGHT_frontSeatLiftLog "Right body controller: front seat lift log";
CM_ SG_ 1251 VCRIGHT_frontSeatLiftBridgeSt "Bridge state";
CM_ SG_ 1251 VCRIGHT_frontSeatTiltPos "Motor encoder value representing front left seat tilt position";
CM_ SG_ 1251 VCRIGHT_frontSeatTiltCurrent "Current drawn by front left seat tilt motor";
CM_ SG_ 1251 VCRIGHT_frontSeatTiltDuty "Front left seat tilt motor duty cycle";
CM_ SG_ 1251 VCRIGHT_frontSeatTiltState "State of front right seat tilt motor";
CM_ SG_ 1251 VCRIGHT_frontSeatTiltCalibrated "Right body controller: front seat tilt calibrated";
CM_ SG_ 1251 VCRIGHT_frontSeatTiltLog "Right body controller: front seat tilt log";
CM_ SG_ 1251 VCRIGHT_frontSeatTiltBridgeSt "Bridge state";
CM_ SG_ 1251 VCRIGHT_lumbarAState "State of front right seat lumbar bladder A";
CM_ SG_ 1251 VCRIGHT_lumbarBState "State of front right lumbar bladder B";
CM_ SG_ 1251 VCRIGHT_lumbarAPressureHpa "Right body controller: lumbar a pressure hpa";
CM_ SG_ 1251 VCRIGHT_lumbarAPressureHpaFilt "logs filtered pressure of right seat lumbar bladder A";
CM_ SG_ 1251 VCRIGHT_lumbarBPressureHpa "Right body controller: lumbar b pressure hpa";
CM_ SG_ 1251 VCRIGHT_lumbarBPressureHpaFilt "logs filtered pressure of right seat lumbar bladder B";
CM_ SG_ 1251 VCRIGHT_lumbarActiveTooLongErr "Error reported by lumbar ECU: Valve activated too long";
CM_ SG_ 1251 VCRIGHT_lumbarMaxPErr "Error reported by lumbar ECU: max bladder pressure reached";
CM_ SG_ 1251 VCRIGHT_lumbarOvercurrentErr "Error reported by lumbar ECU: pump overcurrent";
CM_ SG_ 1251 VCRIGHT_lumbarMaxOperatingPErr "Error reported by lumbar ECU: max bladder operating pressure reached";
CM_ SG_ 1251 VCRIGHT_lumbarMinPErr "Error reported by lumbar ECU: min bladder pressure reached";
CM_ SG_ 1251 VCRIGHT_lumbarGeneralErr "Error reported by lumbar ECU: general error";
CM_ SG_ 1251 VCRIGHT_lumbarDevMaxPumpPressA "System has reached Tesla specified maximum pressure for lumbar bladder A";
CM_ SG_ 1251 VCRIGHT_lumbarDevMaxPumpPressB "System has reached Tesla specified maximum pressure for lumbar bladder B";
CM_ SG_ 1251 VCRIGHT_frontSeatTrackPosReal "Front right seat track position in millimeters";
CM_ SG_ 1251 VCRIGHT_frontSeatBackPosReal "Front right seat backrest position in degrees";
CM_ SG_ 1251 VCRIGHT_frontSeatLiftPosReal "Front right seat lift position in millimeters";
CM_ SG_ 1251 VCRIGHT_frontSeatTiltPosReal "Front right seat tilt position in degrees";
CM_ SG_ 1251 VCRIGHT_frontSeatTrackPosOffset "Communicates post calibration position offset of front right seat track in a physical unit";
CM_ SG_ 1251 VCRIGHT_frontSeatBackPosOffset "Communicates post calibration position offset of front right seat backrest in a physical unit";
CM_ SG_ 1251 VCRIGHT_frontSeatLiftPosOffset "Communicates post calibration position offset of front right seat lift in a physical unit";
CM_ SG_ 1251 VCRIGHT_frontSeatTiltPosOffset "Communicates post calibration position offset of front right seat tilt in a physical unit";
CM_ BO_ 739 "Right body controller message: seat status2";
CM_ SG_ 739 VCRIGHT_seatStatus2Index "Right body controller: seat status2 index";
CM_ SG_ 739 VCRIGHT_frontSeatHeatCurrent "Right body controller: front seat heat current; raw 12 = signal not available (SNA)";
CM_ SG_ 739 VCRIGHT_frontSeatHeatDuty "Right body controller: front seat heat duty";
CM_ SG_ 739 VCRIGHT_frontSeatHeatTmp "Right body controller: front seat heat tmp";
CM_ SG_ 739 VCRIGHT_frontSeatHeatTmpTarget "Target temperature for front right seat heater";
CM_ SG_ 739 VCRIGHT_frontSeatHeatInhibited "Front right seat heater duty cycle";
CM_ SG_ 739 VCRIGHT_frontSeatHeatPowered "Right body controller: front seat heat powered";
CM_ SG_ 739 VCRIGHT_rearLSeatHeatCurrent "Current drawn by rear center seat heater";
CM_ SG_ 739 VCRIGHT_rearLSeatHeatDuty "Right body controller: rear l seat heat duty";
CM_ SG_ 739 VCRIGHT_rearLSeatHeatTmp "Right body controller: rear l seat heat tmp";
CM_ SG_ 739 VCRIGHT_rearLSeatHeatTmpTarget "Right body controller: rear l seat heat tmp target";
CM_ SG_ 739 VCRIGHT_rearLSeatHeatInhibited "Right body controller: rear l seat heat inhibited";
CM_ SG_ 739 VCRIGHT_rearLSeatHeatPowered "Right body controller: rear l seat heat powered";
CM_ SG_ 739 VCRIGHT_rearCSeatHeatCurrent "Right body controller: rear c seat heat current";
CM_ SG_ 739 VCRIGHT_rearCSeatHeatDuty "Right body controller: rear c seat heat duty";
CM_ SG_ 739 VCRIGHT_rearCSeatHeatTmp "Right body controller: rear c seat heat tmp";
CM_ SG_ 739 VCRIGHT_rearCSeatHeatTmpTarget "Right body controller: rear c seat heat tmp target";
CM_ SG_ 739 VCRIGHT_rearCSeatHeatInhibited "Right body controller: rear c seat heat inhibited";
CM_ SG_ 739 VCRIGHT_rearCSeatHeatPowered "Right body controller: rear c seat heat powered";
CM_ SG_ 739 VCRIGHT_rearRSeatHeatCurrent "Right body controller: rear r seat heat current";
CM_ SG_ 739 VCRIGHT_rearRSeatHeatDuty "Right body controller: rear r seat heat duty";
CM_ SG_ 739 VCRIGHT_rearRSeatHeatTmp "Right body controller: rear r seat heat tmp";
CM_ SG_ 739 VCRIGHT_rearRSeatHeatTmpTarget "Right body controller: rear r seat heat tmp target";
CM_ SG_ 739 VCRIGHT_rearRSeatHeatInhibited "Right body controller: rear r seat heat inhibited";
CM_ SG_ 739 VCRIGHT_rearRSeatHeatPowered "Right body controller: rear r seat heat powered";
CM_ BO_ 835 "Right body controller message: status";
CM_ SG_ 835 VCRIGHT_LVBatteryTypeDBG "Right body controller: LV battery type DBG";
CM_ SG_ 835 VCRIGHT_rearDefrostState "Right body controller: rear defrost state; raw 0 = signal not available (SNA)";
CM_ SG_ 835 VCRIGHT_mirrorHeatState "Right body controller: mirror heat state; raw 0 = signal not available (SNA)";
CM_ SG_ 835 VCRIGHT_OTAState "Right body controller: OTA state";
CM_ SG_ 835 VCRIGHT_5AVoltage "Right body controller: 5 a voltage";
CM_ SG_ 835 VCRIGHT_vbatProt "Input voltage monitor to controller";
CM_ SG_ 835 VCRIGHT_rationalityAggregateCurr "Right body controller: rationality aggregate current";
CM_ SG_ 835 VCRIGHT_eFuseMgmtVoltageMonitor "Right body controller: e fuse mgmt voltage monitor";
CM_ SG_ 835 VCRIGHT_isSteeringWheelHeaterReq "Right body controller: is steering wheel heater req";
CM_ SG_ 835 VCRIGHT_steeringWheelHeaterDCTgt "Right body controller: steering wheel heater DC tgt; raw 127 = signal not available (SNA)";
CM_ BO_ 963 "Right body controller message: switch status";
CM_ SG_ 963 VCRIGHT_switchStatusIndex "Right body controller: switch status index";
CM_ SG_ 963 VCRIGHT_trunkExtReleasePressedPe "Right body controller: trunk ext release pressed persist";
CM_ SG_ 963 VCRIGHT_frontSeatTrackBack "Right body controller: front seat track back; raw 0 = signal not available (SNA)";
CM_ SG_ 963 VCRIGHT_frontSeatTrackForward "Right body controller: front seat track forward; raw 0 = signal not available (SNA)";
CM_ SG_ 963 VCRIGHT_frontSeatTiltDown "Right body controller: front seat tilt down; raw 0 = signal not available (SNA)";
CM_ SG_ 963 VCRIGHT_frontSeatTiltUp "Right body controller: front seat tilt up; raw 0 = signal not available (SNA)";
CM_ SG_ 963 VCRIGHT_frontSeatLiftDown "Right body controller: front seat lift down; raw 0 = signal not available (SNA)";
CM_ SG_ 963 VCRIGHT_frontSeatLiftUp "Right body controller: front seat lift up; raw 0 = signal not available (SNA)";
CM_ SG_ 963 VCRIGHT_frontSeatBackrestBack "Right body controller: front seat backrest back; raw 0 = signal not available (SNA)";
CM_ SG_ 963 VCRIGHT_frontSeatBackrestForward "Right body controller: front seat backrest forward; raw 0 = signal not available (SNA)";
CM_ SG_ 963 VCRIGHT_frontSeatLumbarDown "Right body controller: front seat lumbar down; raw 0 = signal not available (SNA)";
CM_ SG_ 963 VCRIGHT_frontSeatLumbarUp "Right body controller: front seat lumbar up; raw 0 = signal not available (SNA)";
CM_ SG_ 963 VCRIGHT_frontSeatLumbarIn "Right body controller: front seat lumbar in; raw 0 = signal not available (SNA)";
CM_ SG_ 963 VCRIGHT_frontSeatLumbarOut "Right body controller: front seat lumbar out; raw 0 = signal not available (SNA)";
CM_ SG_ 963 VCRIGHT_frontHandlePWM "Right body controller: front handle PWM";
CM_ SG_ 963 VCRIGHT_rearHandlePWM "Right body controller: rear handle PWM";
CM_ SG_ 963 VCRIGHT_gloveboxLightCurrent "Current through the glovebox LED";
CM_ SG_ 963 VCRIGHT_frontSeatALR "Front right seat automatic locking retractor switch; raw 0 = signal not available (SNA)";
CM_ SG_ 963 VCRIGHT_frontSeatResistiveOccupa "Front right seat occupancy status; raw 0 = signal not available (SNA)";
CM_ SG_ 963 VCRIGHT_2RowSeatReclineSwitchpac "State of the right second row powered recline adjustment switchpack";
CM_ BO_ 537 "Vehicle security controller message: TPMS data";
CM_ SG_ 537 VCSEC_TPMSDataIndex "Vehicle security controller: TPMS data index";
CM_ SG_ 537 VCSEC_TPMSCapabilityPressureInAd "Vehicle security controller: TPMS capability pressure in adv0";
CM_ SG_ 537 VCSEC_TPMSCapabilityConfigurable "Vehicle security controller: TPMS capability configurable pressure0";
CM_ SG_ 537 VCSEC_TPMSPressureRateOfChange0 "Reports the raw pressure value of TPMS sensor 0.";
CM_ SG_ 537 VCSEC_TPMSPressure0 "Indicates Absolute pressure measured by wheel unit; raw 511 = signal not available (SNA)";
CM_ SG_ 537 VCSEC_TPMSTemperature0 "Indicates temperature in tire; raw 255 = signal not available (SNA)";
CM_ SG_ 537 VCSEC_TPMSBatVoltage0 "Sensor battery voltage; raw 255 = signal not available (SNA)";
CM_ SG_ 537 VCSEC_TPMSLocation0 "Indicates the localization result";
CM_ SG_ 537 VCSEC_TPMSTemperatureCompensated "Indicates Absolute pressure measured by wheel unit; raw 511 = signal not available (SNA)";
CM_ SG_ 537 VCSEC_TPMSCapabilityPressur_0001 "Vehicle security controller: TPMS capability pressure in adv1";
CM_ SG_ 537 VCSEC_TPMSCapabilityConfigu_0001 "Vehicle security controller: TPMS capability configurable pressure1";
CM_ SG_ 537 VCSEC_TPMSPressureRateOfChange1 "Reports the raw pressure value of TPMS sensor 1.";
CM_ SG_ 537 VCSEC_TPMSPressure1 "Indicates Absolute pressure measured by wheel unit; raw 511 = signal not available (SNA)";
CM_ SG_ 537 VCSEC_TPMSTemperature1 "Indicates temperature in tire; raw 255 = signal not available (SNA)";
CM_ SG_ 537 VCSEC_TPMSBatVoltage1 "Sensor battery voltage; raw 255 = signal not available (SNA)";
CM_ SG_ 537 VCSEC_TPMSLocation1 "Indicates the localization result";
CM_ SG_ 537 VCSEC_TPMSTemperatureCompen_0001 "Indicates Absolute pressure measured by wheel unit; raw 511 = signal not available (SNA)";
CM_ SG_ 537 VCSEC_TPMSCapabilityPressur_0002 "Vehicle security controller: TPMS capability pressure in adv2";
CM_ SG_ 537 VCSEC_TPMSCapabilityConfigu_0002 "Vehicle security controller: TPMS capability configurable pressure2";
CM_ SG_ 537 VCSEC_TPMSPressureRateOfChange2 "Reports the raw pressure value of TPMS sensor 2.";
CM_ SG_ 537 VCSEC_TPMSPressure2 "Indicates Absolute pressure measured by wheel unit; raw 511 = signal not available (SNA)";
CM_ SG_ 537 VCSEC_TPMSTemperature2 "Indicates temperature in tire; raw 255 = signal not available (SNA)";
CM_ SG_ 537 VCSEC_TPMSBatVoltage2 "Sensor battery voltage; raw 255 = signal not available (SNA)";
CM_ SG_ 537 VCSEC_TPMSLocation2 "Indicates the localization result";
CM_ SG_ 537 VCSEC_TPMSTemperatureCompen_0002 "Indicates Absolute pressure measured by wheel unit; raw 511 = signal not available (SNA)";
CM_ SG_ 537 VCSEC_TPMSCapabilityPressur_0003 "Vehicle security controller: TPMS capability pressure in adv3";
CM_ SG_ 537 VCSEC_TPMSCapabilityConfigu_0003 "Vehicle security controller: TPMS capability configurable pressure3";
CM_ SG_ 537 VCSEC_TPMSPressureRateOfChange3 "Reports the raw pressure value of TPMS sensor 3.";
CM_ SG_ 537 VCSEC_TPMSPressure3 "Indicates Absolute pressure measured by wheel unit; raw 511 = signal not available (SNA)";
CM_ SG_ 537 VCSEC_TPMSTemperature3 "Indicates temperature in tire; raw 255 = signal not available (SNA)";
CM_ SG_ 537 VCSEC_TPMSBatVoltage3 "Sensor battery voltage; raw 255 = signal not available (SNA)";
CM_ SG_ 537 VCSEC_TPMSLocation3 "Indicates the localization result";
CM_ SG_ 537 VCSEC_TPMSTemperatureCompen_0003 "Indicates Absolute pressure measured by wheel unit; raw 511 = signal not available (SNA)";
CM_ SG_ 537 VCSEC_TPMSRecommendedColdPressur "Indicates Absolute pressure measured by wheel unit; raw 255 = signal not available (SNA)";
CM_ SG_ 537 VCSEC_TPMSRecommendedColdPr_0001 "Indicates Absolute pressure measured by wheel unit; raw 255 = signal not available (SNA)";
CM_ SG_ 537 VCSEC_TPMSFeature0 "Vehicle security controller: TPMS feature0";
CM_ SG_ 537 VCSEC_TPMSFeature1 "Vehicle security controller: TPMS feature1";
CM_ SG_ 537 VCSEC_TPMSFeature0Count "Vehicle security controller: TPMS feature0 count";
CM_ SG_ 537 VCSEC_TPMSFeature0TimeS "Vehicle security controller: TPMS feature0 time s";
CM_ BO_ 570 "Vehicle security controller message: TPMS status";
CM_ SG_ 570 VCSEC_TPMSStatusIndex "Vehicle security controller: TPMS status index";
CM_ SG_ 570 VCSEC_TPMSSystemState "High level state the TPMS system is in currently";
CM_ SG_ 570 VCSEC_TPMSSensorMACAddress0 "Vehicle security controller: TPMS sensor MAC address0";
CM_ SG_ 570 VCSEC_TPMSSensorMACAddress1 "Vehicle security controller: TPMS sensor MAC address1";
CM_ SG_ 570 VCSEC_TPMSSensorMACAddress2 "Vehicle security controller: TPMS sensor MAC address2";
CM_ SG_ 570 VCSEC_TPMSSensorMACAddress3 "Vehicle security controller: TPMS sensor MAC address3";
CM_ SG_ 570 VCSEC_BLESuccessfulConnEventCoun "Count of successful BLE connection events";
CM_ SG_ 570 VCSEC_BLEMissedConnEventCount0 "Count of missed BLE connection events";
CM_ SG_ 570 VCSEC_BLECRCErrorConnEventCount0 "Count of BLE connection events ended with a CRC error";
CM_ SG_ 570 VCSEC_BLEOtherFailuresCount0 "Count of other radio related failures";
CM_ SG_ 570 VCSEC_BLEUnsuccessfulConnEventRa "Vehicle security controller: BLE unsuccessful conn event rate0; raw 1023 = signal not available (SNA)";
CM_ SG_ 570 VCSEC_BLESuccessfulConnEven_0001 "Count of successful BLE connection events";
CM_ SG_ 570 VCSEC_BLEMissedConnEventCount1 "Count of missed BLE connection events";
CM_ SG_ 570 VCSEC_BLECRCErrorConnEventCount1 "Count of BLE connection events ended with a CRC error";
CM_ SG_ 570 VCSEC_BLEOtherFailuresCount1 "Count of other radio related failures";
CM_ SG_ 570 VCSEC_BLEUnsuccessfulConnEv_0001 "Vehicle security controller: BLE unsuccessful conn event rate1; raw 1023 = signal not available (SNA)";
CM_ SG_ 570 VCSEC_BLESuccessfulConnEven_0002 "Count of successful BLE connection events";
CM_ SG_ 570 VCSEC_BLEMissedConnEventCount2 "Count of missed BLE connection events";
CM_ SG_ 570 VCSEC_BLECRCErrorConnEventCount2 "Count of BLE connection events ended with a CRC error";
CM_ SG_ 570 VCSEC_BLEOtherFailuresCount2 "Count of other radio related failures";
CM_ SG_ 570 VCSEC_BLEUnsuccessfulConnEv_0002 "Vehicle security controller: BLE unsuccessful conn event rate2; raw 1023 = signal not available (SNA)";
CM_ SG_ 570 VCSEC_BLESuccessfulConnEven_0003 "Count of successful BLE connection events";
CM_ SG_ 570 VCSEC_BLEMissedConnEventCount3 "Count of missed BLE connection events";
CM_ SG_ 570 VCSEC_BLECRCErrorConnEventCount3 "Count of BLE connection events ended with a CRC error";
CM_ SG_ 570 VCSEC_BLEOtherFailuresCount3 "Count of other radio related failures";
CM_ SG_ 570 VCSEC_BLEUnsuccessfulConnEv_0003 "Vehicle security controller: BLE unsuccessful conn event rate3; raw 1023 = signal not available (SNA)";
CM_ SG_ 570 VCSEC_TPMSSensorTIAppCRC0 "Vehicle security controller: TPMS sensor TI app CRC0; raw 0 = signal not available (SNA)";
CM_ SG_ 570 VCSEC_TPMSSensorMLXAppCRC0 "Vehicle security controller: TPMS sensor MLX app CRC0; raw 0 = signal not available (SNA)";
CM_ SG_ 570 VCSEC_TPMSSensorTIAppCRC1 "Vehicle security controller: TPMS sensor TI app CRC1; raw 0 = signal not available (SNA)";
CM_ SG_ 570 VCSEC_TPMSSensorMLXAppCRC1 "Vehicle security controller: TPMS sensor MLX app CRC1; raw 0 = signal not available (SNA)";
CM_ SG_ 570 VCSEC_TPMSSensorTIAppCRC2 "Vehicle security controller: TPMS sensor TI app CRC2; raw 0 = signal not available (SNA)";
CM_ SG_ 570 VCSEC_TPMSSensorMLXAppCRC2 "Vehicle security controller: TPMS sensor MLX app CRC2; raw 0 = signal not available (SNA)";
CM_ SG_ 570 VCSEC_TPMSSensorTIAppCRC3 "Vehicle security controller: TPMS sensor TI app CRC3; raw 0 = signal not available (SNA)";
CM_ SG_ 570 VCSEC_TPMSSensorMLXAppCRC3 "Vehicle security controller: TPMS sensor MLX app CRC3; raw 0 = signal not available (SNA)";
CM_ SG_ 570 VCSEC_TPMStotalAwakeTime0 "Sleep and CPU time count";
CM_ SG_ 570 VCSEC_TPMSTrimAdjusted0 "Vehicle security controller: TPMS trim adjusted0";
CM_ SG_ 570 VCSEC_TPMSGenealogySensorState0 "TPMS genealogy state";
CM_ SG_ 570 VCSEC_TPMSSensorType0 "Tesla TPMS type";
CM_ SG_ 570 VCSEC_TPMStotalAwakeTime1 "Sleep and CPU time count";
CM_ SG_ 570 VCSEC_TPMSTrimAdjusted1 "Vehicle security controller: TPMS trim adjusted1";
CM_ SG_ 570 VCSEC_TPMSGenealogySensorState1 "TPMS genealogy state";
CM_ SG_ 570 VCSEC_TPMSSensorType1 "Tesla TPMS type";
CM_ SG_ 570 VCSEC_TPMStotalAwakeTime2 "Sleep and CPU time count";
CM_ SG_ 570 VCSEC_TPMSTrimAdjusted2 "Vehicle security controller: TPMS trim adjusted2";
CM_ SG_ 570 VCSEC_TPMSGenealogySensorState2 "TPMS genealogy state";
CM_ SG_ 570 VCSEC_TPMSSensorType2 "Tesla TPMS type";
CM_ SG_ 570 VCSEC_TPMStotalAwakeTime3 "Sleep and CPU time count";
CM_ SG_ 570 VCSEC_TPMSTrimAdjusted3 "Vehicle security controller: TPMS trim adjusted3";
CM_ SG_ 570 VCSEC_TPMSGenealogySensorState3 "TPMS genealogy state";
CM_ SG_ 570 VCSEC_TPMSSensorType3 "Tesla TPMS type";
CM_ BO_ 1067 "Vehicle security controller message: UWB data";
CM_ SG_ 1067 VCSEC_UWBEndpointIndex "Vehicle security controller: UWB endpoint index";
CM_ SG_ 1067 VCSEC_UWBRearRightDistance0 "Reports distance between the customer's phone and the endpoint; raw 4095 = signal not available (SNA)";
CM_ SG_ 1067 VCSEC_UWBRearRightDistance1 "Reports distance between the customer's phone and the endpoint; raw 4095 = signal not available (SNA)";
CM_ SG_ 1067 VCSEC_UWBRearRightDistance2 "Reports distance between the customer's phone and the endpoint; raw 4095 = signal not available (SNA)";
CM_ SG_ 1067 VCSEC_UWBLeftDistance2 "Reports distance between the customer's phone and the endpoint; raw 4095 = signal not available (SNA)";
CM_ SG_ 1067 VCSEC_UWBRightDistance2 "Reports distance between the customer's phone and the endpoint; raw 4095 = signal not available (SNA)";
CM_ SG_ 1067 VCSEC_UWBRearDistance2 "Reports distance between the customer's phone and the endpoint; raw 4095 = signal not available (SNA)";
CM_ SG_ 1067 VCSEC_UWBRearLeftDistance2 "Reports distance between the customer's phone and the endpoint; raw 4095 = signal not available (SNA)";
CM_ SG_ 1067 VCSEC_UWBCenterDistance2 "Reports distance between the customer's phone and the endpoint; raw 4095 = signal not available (SNA)";
CM_ SG_ 1067 VCSEC_UWBLeftDistance1 "Reports distance between the customer's phone and the endpoint; raw 4095 = signal not available (SNA)";
CM_ SG_ 1067 VCSEC_UWBRightDistance1 "Reports distance between the customer's phone and the endpoint; raw 4095 = signal not available (SNA)";
CM_ SG_ 1067 VCSEC_UWBRearDistance1 "Reports distance between the customer's phone and the endpoint; raw 4095 = signal not available (SNA)";
CM_ SG_ 1067 VCSEC_UWBRearLeftDistance1 "Reports distance between the customer's phone and the endpoint; raw 4095 = signal not available (SNA)";
CM_ SG_ 1067 VCSEC_UWBCenterDistance1 "Reports distance between the customer's phone and the endpoint; raw 4095 = signal not available (SNA)";
CM_ SG_ 1067 VCSEC_UWBLeftDistance0 "Reports distance between the customer's phone and the endpoint; raw 4095 = signal not available (SNA)";
CM_ SG_ 1067 VCSEC_UWBRightDistance0 "Reports distance between the customer's phone and the endpoint; raw 4095 = signal not available (SNA)";
CM_ SG_ 1067 VCSEC_UWBRearDistance0 "Reports distance between the customer's phone and the endpoint; raw 4095 = signal not available (SNA)";
CM_ SG_ 1067 VCSEC_UWBRearLeftDistance0 "Reports distance between the customer's phone and the endpoint; raw 4095 = signal not available (SNA)";
CM_ SG_ 1067 VCSEC_UWBCenterDistance0 "Reports distance between the customer's phone and the endpoint; raw 4095 = signal not available (SNA)";
CM_ BO_ 761 "Vehicle security controller message: additional auth info";
CM_ SG_ 761 VCSEC_activeKeyDebug "Vehicle security controller: active key debug";
CM_ SG_ 761 VCSEC_bleChannelDisconnected "Connection between vehicle and the BLE authentication device is interrupted.";
CM_ SG_ 761 VCSEC_bleDisconnectionReason "Reasons of the disconnection between vehicle and BLE authentication device.";
CM_ SG_ 761 VCSEC_bleConnetionAttemptWLEntry "Vehicle security controller: ble connetion attempt WL entry";
CM_ SG_ 761 VCSEC_AdditionalAuthInfoIndex "Vehicle security controller: additional auth info index";
CM_ SG_ 761 VCSEC_activeKeyReason "Reason for picking the currently active key";
CM_ SG_ 761 VCSEC_activeKeySHA1 "Vehicle security controller: active key SHA1";
CM_ SG_ 761 VCSEC_algoUsedForSummonRange0 "Vehicle security controller: algo used for summon range0";
CM_ SG_ 761 VCSEC_keyWithinSummonRange0 "Vehicle security controller: key within summon range0";
CM_ SG_ 761 VCSEC_algoUsedForSummonRange1 "Vehicle security controller: algo used for summon range1";
CM_ SG_ 761 VCSEC_keyWithinSummonRange1 "Vehicle security controller: key within summon range1";
CM_ SG_ 761 VCSEC_algoUsedForSummonRange2 "Vehicle security controller: algo used for summon range2";
CM_ SG_ 761 VCSEC_keyWithinSummonRange2 "Vehicle security controller: key within summon range2";
CM_ SG_ 761 VCSEC_BLEDeviceWithinSummonRange "Vehicle security controller: BLE device within summon range";
CM_ SG_ 761 VCSEC_NFCAuthFromBPillarFormFact "Reports the form factor authentication at B-pillar Near Field Communication (NFC) reader.";
CM_ SG_ 761 VCSEC_NFCAuthFromCenterConsoleFo "Reports the form factor authenticating at center console Near Field Communication (NFC) reader.";
CM_ BO_ 1817 "Vehicle security controller message: debug100ms";
CM_ SG_ 1817 VCSEC_debug100msIndex "Vehicle security controller: debug100ms index";
CM_ SG_ 1817 VCSEC_walkAwayLockKeyState "Walk away lock key state of the vehicle";
CM_ SG_ 1817 VCSEC_thresholdOffsetVersion "Vehicle security controller: threshold offset version";
CM_ SG_ 1817 VCSEC_walkAwayLockState "Walk away lock state of the vehicle";
CM_ SG_ 1817 VCSEC_rssi0WLEntry "Whitelist entry of the rssi0 device";
CM_ SG_ 1817 VCSEC_endpointLayout "Vehicle security controller: endpoint layout";
CM_ SG_ 1817 VCSEC_rssi1WLEntry "Whitelist entry of the rssi1 device";
CM_ SG_ 1817 VCSEC_rssi2WLEntry "Whitelist entry of the rssi2 device";
CM_ SG_ 1817 VCSEC_walkUpUnlockState "Status of walk up unlock state";
CM_ SG_ 1817 VCSEC_algoHighThreshLeft "Vehicle security controller: algo high thresh left";
CM_ SG_ 1817 VCSEC_algoHighThreshRight "Vehicle security controller: algo high thresh right";
CM_ SG_ 1817 VCSEC_algoHighThreshCenter "Vehicle security controller: algo high thresh center";
CM_ SG_ 1817 VCSEC_pollingReason "Reason that the vehicle is currently polling for location";
CM_ SG_ 1817 VCSEC_numberOfPubKeysOnWhitelist "Number of public keys on keys whitelist.";
CM_ SG_ 1817 VCSEC_thermalDetectState "Reports the current state of thermal detection.";
CM_ SG_ 1817 VCSEC_connection0BondingState "state of the GAP bonding statemachine";
CM_ SG_ 1817 VCSEC_connection1BondingState "state of the GAP bonding statemachine";
CM_ SG_ 1817 VCSEC_connection2BondingState "state of the GAP bonding statemachine";
CM_ SG_ 1817 VCSEC_connection0UWBAvailability "state of the UWB availability on the BLE connection";
CM_ SG_ 1817 VCSEC_connection1UWBAvailability "state of the UWB availability on the BLE connection";
CM_ SG_ 1817 VCSEC_connection2UWBAvailability "state of the UWB availability on the BLE connection";
CM_ SG_ 1817 VCSEC_NISessionStateCenter0 "Vehicle security controller: NI session state center0";
CM_ SG_ 1817 VCSEC_NISessionStateLeft0 "Vehicle security controller: NI session state left0";
CM_ SG_ 1817 VCSEC_NISessionStateRight0 "Vehicle security controller: NI session state right0";
CM_ SG_ 1817 VCSEC_NISessionStateRearLeft0 "Vehicle security controller: NI session state rear left0";
CM_ SG_ 1817 VCSEC_NISessionStateRearRight0 "Vehicle security controller: NI session state rear right0";
CM_ SG_ 1817 VCSEC_NISessionStateRear0 "Vehicle security controller: NI session state rear0";
CM_ SG_ 1817 VCSEC_NISessionStateCenter1 "Vehicle security controller: NI session state center1";
CM_ SG_ 1817 VCSEC_NISessionStateLeft1 "Vehicle security controller: NI session state left1";
CM_ SG_ 1817 VCSEC_NISessionStateRight1 "Vehicle security controller: NI session state right1";
CM_ SG_ 1817 VCSEC_NISessionStateRearLeft1 "Vehicle security controller: NI session state rear left1";
CM_ SG_ 1817 VCSEC_NISessionStateRearRight1 "Vehicle security controller: NI session state rear right1";
CM_ SG_ 1817 VCSEC_NISessionStateRear1 "Vehicle security controller: NI session state rear1";
CM_ SG_ 1817 VCSEC_NISessionStateCenter2 "Vehicle security controller: NI session state center2";
CM_ SG_ 1817 VCSEC_NISessionStateLeft2 "Vehicle security controller: NI session state left2";
CM_ SG_ 1817 VCSEC_NISessionStateRight2 "Vehicle security controller: NI session state right2";
CM_ SG_ 1817 VCSEC_NISessionStateRearLeft2 "Vehicle security controller: NI session state rear left2";
CM_ SG_ 1817 VCSEC_NISessionStateRearRight2 "Vehicle security controller: NI session state rear right2";
CM_ SG_ 1817 VCSEC_NISessionStateRear2 "Vehicle security controller: NI session state rear2";
CM_ BO_ 1655 "VC ECU message: LVBMS status high";
CM_ SG_ 1655 VC_lvbmsStatusHighIndex "VC ECU: lvbms status high index";
CM_ SG_ 1655 VC_LVBMS_packCurrent "Electrical current into the low voltage battery; raw 4194303 = signal not available (SNA)";
CM_ SG_ 1655 VC_LVBMS_packVoltage "Voltage of the low voltage battery; raw 65535 = signal not available (SNA)";
CM_ SG_ 1655 VC_LVBMS_packTemperature "Temperature of the low voltage battery; raw 511 = signal not available (SNA)";
CM_ SG_ 1655 VC_LVBMS_MOSTemperature "Temperature of the MOSFET on the low voltage battery; raw 4095 = signal not available (SNA)";
CM_ SG_ 1655 VC_LVBMS_sumCellVoltage "Sum of the cell voltage of the low voltage battery; raw 65535 = signal not available (SNA)";
CM_ SG_ 1655 VC_LVBMS_maxBrickVoltage "Maximum cell voltage in the low voltage battery; raw 8191 = signal not available (SNA)";
CM_ SG_ 1655 VC_LVBMS_maxBrickVoltageIndex "VC ECU: LVBMS max brick voltage index; raw 255 = signal not available (SNA)";
CM_ SG_ 1655 VC_LVBMS_avgBrickVoltage "Average voltage of all cells in the low voltage battery; raw 8191 = signal not available (SNA)";
CM_ SG_ 1655 VC_LVBMS_minBrickVoltage "Minimum cell voltage in the low voltage battery; raw 8191 = signal not available (SNA)";
CM_ SG_ 1655 VC_LVBMS_minBrickVoltageIndex "VC ECU: LVBMS min brick voltage index; raw 255 = signal not available (SNA)";
CM_ SG_ 1655 VC_LVBMS_voltageTarget "Voltage target of the LV battery; raw 65535 = signal not available (SNA)";
CM_ SG_ 1655 VC_LVBMS_currentTarget "Target current requested by the LV battery; raw 131071 = signal not available (SNA)";
CM_ SG_ 1655 VC_LVBMS_maxAllowedChargeCurrent "Maximum allowed charge current of the battery; raw 8191 = signal not available (SNA)";
CM_ SG_ 1655 VC_LVBMS_maxAllowedDischargeCurr "Maximum allowed discharge current of the battery; raw 8191 = signal not available (SNA)";
CM_ SG_ 1655 VC_LVBMS_MOSCommand "Current state of the MOS command to the LV battery";
CM_ SG_ 1655 VC_LVBMS_ClearErrorCntrCommand "VC ECU: LVBMS clear error cntr command";
CM_ SG_ 1655 VC_LVBMS_ClearHistoricFaultComma "VC ECU: LVBMS clear historic fault command";
CM_ SG_ 1655 VC_LVBMS_ResetLVBMSCommand "Reset command issued to LVBMS, commanded by VC";
CM_ SG_ 1655 VC_LVBMS_EnterHibernationCommand "VC ECU: LVBMS enter hibernation command";
CM_ SG_ 1655 VC_LVBMS_ECPAState "Current state of the E-CPA on the LV battery; raw 3 = signal not available (SNA)";
CM_ SG_ 1655 VC_LVBMS_MOSState "Current state of the MOS on the LV battery; raw 3 = signal not available (SNA)";
CM_ SG_ 1655 VC_LVBMS_VehicleState "VC ECU: LVBMS vehicle state";
CM_ SG_ 1655 VC_LVBMS_LINWakeDisabled "VC ECU: LVBMS LIN wake disabled";
CM_ SG_ 1655 VC_LVBMS_chargeType "VC ECU: LVBMS charge type; raw 4 = signal not available (SNA)";
CM_ SG_ 1655 VC_LVBMS_cellAndArcProtEnabled "Indicates whether the VC has commanded cell protections to be active";
CM_ SG_ 1655 VC_totalLVLoadCurrent "Total LV load current of the vehicle.";
CM_ SG_ 1655 VC_LVPackChargeCurrentLimit "Charge current limit for the LV battery pack.";
CM_ SG_ 1655 VC_LVPackCurrent "Current of the LV battery pack.";
CM_ SG_ 1655 VC_LVBMS_estimatedPackOcv "VC ECU: LVBMS estimated pack ocv";
CM_ BO_ 1816 "VC ECU message: LVBMS status low";
CM_ SG_ 1816 VC_lvbmsStatusLowIndex "VC ECU: lvbms status low index";
CM_ SG_ 1816 VC_LVBMS_SOC "State of charge reported by the low voltage battery sensor; raw 127 = signal not available (SNA)";
CM_ SG_ 1816 VC_LVBMS_SOE "State of energy reported by the low voltage battery; raw 127 = signal not available (SNA)";
CM_ SG_ 1816 VC_LVBMS_SOH "State of health reported by the low voltage battery; raw 127 = signal not available (SNA)";
CM_ SG_ 1816 VC_LVBMS_SOP "VC ECU: LVBMS SOP; raw 16777215 = signal not available (SNA)";
CM_ SG_ 1816 VC_LVBMS_AvgSleepCurrent "Low voltage battery average sleep current; raw 65535 = signal not available (SNA)";
CM_ SG_ 1816 VC_LVBMS_TimeSlept "VC ECU: LVBMS time slept; raw 16777215 = signal not available (SNA)";
CM_ SG_ 1816 VC_LVBMS_AhCharged "Low voltage battery charge state; raw 4294967295 = signal not available (SNA)";
CM_ SG_ 1816 VC_LVBMS_MinSleepCurrent "VC ECU: LVBMS min sleep current; raw 65535 = signal not available (SNA)";
CM_ SG_ 1816 VC_LVBMS_AhDischarged "Low voltage battery charge state; raw 4294967295 = signal not available (SNA)";
CM_ SG_ 1816 VC_LVBMS_MaxSleepCurrent "VC ECU: LVBMS max sleep current; raw 65535 = signal not available (SNA)";
CM_ SG_ 1816 VC_LVBMS_sumCellVoltageFiltered "VC ECU: LVBMS sum cell voltage filtered; raw 65535 = signal not available (SNA)";
CM_ SG_ 1816 VC_LVBMS_maxCellSOC "SOC estimate of the highest SOC cell; raw 127 = signal not available (SNA)";
CM_ SG_ 1816 VC_LVBMS_minCellSOC "SOC estimate of the lowest SOC cell; raw 127 = signal not available (SNA)";
CM_ SG_ 1816 VC_LVBMS_staticSOCCorrection "Flag indicating the LVBMS is performing static SOC correction.";
CM_ SG_ 1816 VC_LVBMS_dynamicSOCCorrection "Flag indicating the LVBMS is performing dynamic SOC correction.";
CM_ SG_ 1816 VC_LVBMS_usableEnergyAvailable "Available/remaining usable pack energy; raw 4095 = signal not available (SNA)";
CM_ SG_ 1816 VC_LVBMS_CellOVLevel1 "VC ECU: LVBMS cell OV level1";
CM_ SG_ 1816 VC_LVBMS_CellOVLevel2 "VC ECU: LVBMS cell OV level2";
CM_ SG_ 1816 VC_LVBMS_CellOVLevel3 "VC ECU: LVBMS cell OV level3";
CM_ SG_ 1816 VC_LVBMS_CellUVLevel1 "VC ECU: LVBMS cell UV level1";
CM_ SG_ 1816 VC_LVBMS_CellUVLevel2 "VC ECU: LVBMS cell UV level2";
CM_ SG_ 1816 VC_LVBMS_ModuleOTLevel1 "VC ECU: LVBMS module OT level1";
CM_ SG_ 1816 VC_LVBMS_PackOVLevel1 "VC ECU: LVBMS pack OV level1";
CM_ SG_ 1816 VC_LVBMS_PackOVLevel2 "Pack Over Voltage Level 2 flag status";
CM_ SG_ 1816 VC_LVBMS_DischrgOCLevel1 "VC ECU: LVBMS dischrg OC level1";
CM_ SG_ 1816 VC_LVBMS_DischrgOCLevel2 "Discharge Over Current Level 2 flag status";
CM_ SG_ 1816 VC_LVBMS_ChrgOCLevel1 "VC ECU: LVBMS chrg OC level1";
CM_ SG_ 1816 VC_LVBMS_ChrgOCLevel2 "Charge Over Current Level 2 flag status";
CM_ SG_ 1816 VC_LVBMS_MOSFETOTLevel1 "VC ECU: LVBMS MOSFETOT level1";
CM_ SG_ 1816 VC_LVBMS_KBValueLostFault "Loss of CATL specific internal value flag status. Lost value causes offset in current sensor reading.";
CM_ SG_ 1816 VC_LVBMS_BalanceCircuitFault "Balance Circuit Fault flag status";
CM_ SG_ 1816 VC_LVBMS_MOSStateFault "Mosfet fault state flag status. Not to be confused with VC_LVBMS_MOSState.";
CM_ SG_ 1816 VC_LVBMS_NTCTempDiffWarnLevel1 "VC ECU: LVBMS NTC temp diff warn level1";
CM_ SG_ 1816 VC_LVBMS_DeepDischargeFlag "Deep Discharge flag status";
CM_ SG_ 1816 VC_LVBMS_SamplingError "Sampling Error flag status";
CM_ SG_ 1816 VC_LVBMS_MosfetStuckCloseError "Mosfet Stuck Close flag status";
CM_ SG_ 1816 VC_LVBMS_MosfetStuckOpenError "Mosfet Stuck Open flag status";
CM_ BO_ 1089 "VC ECU message: pcs interface";
CM_ SG_ 1089 VC_pcsInterfaceMuxIndex "VC ECU: pcs interface mux index";
CM_ SG_ 1089 VC_pcsInterfaceCounter "VC ECU: pcs interface counter";
CM_ SG_ 1089 VC_pcsInterfaceChecksum "VC ECU: pcs interface checksum";
CM_ SG_ 1089 VC_pcsLVVoltageTarget "VC ECU: pcs LV voltage target";
CM_ SG_ 1089 VC_pcsLVMinVoltageLimit "VC ECU: pcs LV min voltage limit";
CM_ SG_ 1089 VC_pcsLVMaxVoltageLimit "VC ECU: pcs LV max voltage limit";
CM_ SG_ 1089 VC_goodForPCSPowerCycle "VC ECU: good for PCS power cycle";
CM_ SG_ 1089 VC_LVBatteryCannotSupportVehicle "VC ECU: LV battery cannot support vehicle";
CM_ SG_ 1089 VC_pcsResistanceFiltered "VC ECU: pcs resistance filtered; raw 65535 = signal not available (SNA)";
CM_ SG_ 1089 VC_pcsLVMaxDchrgCurrentLimit "VC ECU: pcs LV max dchrg current limit";
CM_ SG_ 1089 VC_defaultPcsLVVoltageTarget "VC ECU: default pcs LV voltage target";
CM_ SG_ 1089 VC_lvHwProtSelfTestActive "Reports whether Low Voltage (LV) Hardware (HW) protection self-tests are running or about to run due to a retry.";
BA_DEF_ BO_ "GenMsgCycleTime" INT 0 3600000;
BA_DEF_ BO_ "GenMsgSendType" ENUM "Cyclic","NotUsed","NotUsed","NotUsed","NotUsed","NotUsed","NotUsed","IfActive","NoMsgSendType","NotUsed";
BA_DEF_ BO_ "VFrameFormat" ENUM "StandardCAN","ExtendedCAN","reserved","J1939PG","reserved","reserved","reserved","reserved","reserved","reserved","reserved","reserved","reserved","reserved","StandardCAN_FD","ExtendedCAN_FD";
BA_DEF_ BO_ "CANFD_BRS" ENUM "0","1";
BA_DEF_ SG_ "GenSigSNA" STRING;
BA_DEF_ SG_ "SystemSignalLongSymbol" STRING;
BA_DEF_ SG_ "Confidence" ENUM "validated","plausible","layout-only","contradicted";
BA_DEF_DEF_ "GenMsgCycleTime" 0;
BA_DEF_DEF_ "GenMsgSendType" "NoMsgSendType";
BA_DEF_DEF_ "VFrameFormat" "StandardCAN";
BA_DEF_DEF_ "CANFD_BRS" "1";
BA_DEF_DEF_ "GenSigSNA" "";
BA_DEF_DEF_ "SystemSignalLongSymbol" "";
BA_DEF_DEF_ "Confidence" "layout-only";
BA_ "GenMsgCycleTime" BO_ 691 60;
BA_ "GenMsgSendType" BO_ 691 0;
BA_ "GenMsgCycleTime" BO_ 1862 50;
BA_ "GenMsgSendType" BO_ 1862 0;
BA_ "GenMsgCycleTime" BO_ 1251 100;
BA_ "GenMsgSendType" BO_ 1251 0;
BA_ "GenMsgCycleTime" BO_ 739 200;
BA_ "GenMsgSendType" BO_ 739 0;
BA_ "GenMsgCycleTime" BO_ 835 100;
BA_ "GenMsgSendType" BO_ 835 0;
BA_ "GenMsgCycleTime" BO_ 963 100;
BA_ "GenMsgSendType" BO_ 963 0;
BA_ "GenMsgCycleTime" BO_ 537 100;
BA_ "GenMsgSendType" BO_ 537 0;
BA_ "GenMsgCycleTime" BO_ 570 1000;
BA_ "GenMsgSendType" BO_ 570 0;
BA_ "GenMsgCycleTime" BO_ 1067 100;
BA_ "GenMsgSendType" BO_ 1067 0;
BA_ "GenMsgCycleTime" BO_ 761 100;
BA_ "GenMsgSendType" BO_ 761 0;
BA_ "GenMsgCycleTime" BO_ 1817 50;
BA_ "GenMsgSendType" BO_ 1817 0;
BA_ "GenMsgCycleTime" BO_ 1655 33;
BA_ "GenMsgSendType" BO_ 1655 0;
BA_ "GenMsgCycleTime" BO_ 1816 100;
BA_ "GenMsgSendType" BO_ 1816 0;
BA_ "GenMsgCycleTime" BO_ 1089 50;
BA_ "GenMsgSendType" BO_ 1089 0;
BA_ "Confidence" SG_ 691 VCRIGHT_logging1HzIndex 1;
BA_ "Confidence" SG_ 691 VCRIGHT_tempIncarCabinProbe 0;
BA_ "GenSigSNA" SG_ 691 VCRIGHT_tempIncarCabinProbe "255";
BA_ "Confidence" SG_ 691 VCRIGHT_tempIncarCabinDeep 1;
BA_ "GenSigSNA" SG_ 691 VCRIGHT_tempIncarCabinDeep "255";
BA_ "Confidence" SG_ 691 VCRIGHT_cabinTempInteriorL2 1;
BA_ "GenSigSNA" SG_ 691 VCRIGHT_cabinTempInteriorL2 "255";
BA_ "Confidence" SG_ 691 VCRIGHT_tempIncarCabinMid 0;
BA_ "GenSigSNA" SG_ 691 VCRIGHT_tempIncarCabinMid "250";
BA_ "Confidence" SG_ 691 VCRIGHT_cabinTempInteriorSunnyL2 1;
BA_ "GenSigSNA" SG_ 691 VCRIGHT_cabinTempInteriorSunnyL2 "255";
BA_ "Confidence" SG_ 691 VCRIGHT_cabinTempInteriorL3 1;
BA_ "GenSigSNA" SG_ 691 VCRIGHT_cabinTempInteriorL3 "255";
BA_ "Confidence" SG_ 691 VCRIGHT_cabinTempInteriorSunnyL3 1;
BA_ "GenSigSNA" SG_ 691 VCRIGHT_cabinTempInteriorSunnyL3 "255";
BA_ "Confidence" SG_ 691 VCRIGHT_cabinTempGlassRoof 0;
BA_ "GenSigSNA" SG_ 691 VCRIGHT_cabinTempGlassRoof "255";
BA_ "Confidence" SG_ 691 VCRIGHT_cabinTempWindshield 0;
BA_ "GenSigSNA" SG_ 691 VCRIGHT_cabinTempWindshield "255";
BA_ "Confidence" SG_ 691 VCRIGHT_cabinTempInterior 0;
BA_ "GenSigSNA" SG_ 691 VCRIGHT_cabinTempInterior "255";
BA_ "Confidence" SG_ 691 VCRIGHT_cabinTempInteriorSunny 0;
BA_ "GenSigSNA" SG_ 691 VCRIGHT_cabinTempInteriorSunny "255";
BA_ "Confidence" SG_ 691 VCRIGHT_cabinTempSideGlassLeft 0;
BA_ "GenSigSNA" SG_ 691 VCRIGHT_cabinTempSideGlassLeft "255";
BA_ "Confidence" SG_ 691 VCRIGHT_cabinTempSideGlassRight 0;
BA_ "GenSigSNA" SG_ 691 VCRIGHT_cabinTempSideGlassRight "255";
BA_ "Confidence" SG_ 691 VCRIGHT_cabinTempBreathLevel 0;
BA_ "GenSigSNA" SG_ 691 VCRIGHT_cabinTempBreathLevel "255";
BA_ "Confidence" SG_ 691 VCRIGHT_pcbaTemperature 0;
BA_ "Confidence" SG_ 691 VCRIGHT_wattsHeaterLeftTotal 0;
BA_ "Confidence" SG_ 691 VCRIGHT_wattsHeaterRightTotal 0;
BA_ "Confidence" SG_ 691 VCRIGHT_qdotLeftFFUnsat 0;
BA_ "Confidence" SG_ 691 VCRIGHT_qdotRightFFUnsat 0;
BA_ "Confidence" SG_ 691 VCRIGHT_nvhLevelDb 0;
BA_ "Confidence" SG_ 691 VCRIGHT_hvacSetTempActualLeft 0;
BA_ "Confidence" SG_ 691 VCRIGHT_hvacSetTempActualRight 0;
BA_ "Confidence" SG_ 691 VCRIGHT_hvacAutoTransitionReason 0;
BA_ "Confidence" SG_ 691 VCRIGHT_hvacMassflowTarget 0;
BA_ "Confidence" SG_ 691 VCRIGHT_hvacQdotLimitedLeft 0;
BA_ "Confidence" SG_ 691 VCRIGHT_hvacQdotLimitedRight 0;
BA_ "Confidence" SG_ 691 VCRIGHT_LHPanelAirflowBlocked 0;
BA_ "Confidence" SG_ 691 VCRIGHT_RHPanelAirflowBlocked 0;
BA_ "Confidence" SG_ 691 VCRIGHT_floorAirflowBlocked 0;
BA_ "Confidence" SG_ 691 VCRIGHT_defrostAirflowBlocked 0;
BA_ "Confidence" SG_ 691 VCRIGHT_hvacFilterLifeDetectActi 0;
BA_ "SystemSignalLongSymbol" SG_ 691 VCRIGHT_hvacFilterLifeDetectActi "VCRIGHT_hvacFilterLifeDetectActive";
BA_ "Confidence" SG_ 691 VCRIGHT_hvacLHBleedOperationMode 0;
BA_ "Confidence" SG_ 691 VCRIGHT_hvacRHBleedOperationMode 0;
BA_ "Confidence" SG_ 691 VCRIGHT_hvacLHVaneOperationMode 0;
BA_ "Confidence" SG_ 691 VCRIGHT_hvacRHVaneOperationMode 0;
BA_ "Confidence" SG_ 691 VCRIGHT_hvacUpperModeOpMode 0;
BA_ "Confidence" SG_ 691 VCRIGHT_hvacLowerModeOpMode 0;
BA_ "Confidence" SG_ 691 VCRIGHT_hvacIntakeOperationMode 0;
BA_ "Confidence" SG_ 691 VCRIGHT_isProbeFeedbackApplied 0;
BA_ "Confidence" SG_ 691 VCRIGHT_feedbackPullDownScalar 0;
BA_ "Confidence" SG_ 691 VCRIGHT_feedForwardPullDownScala 0;
BA_ "SystemSignalLongSymbol" SG_ 691 VCRIGHT_feedForwardPullDownScala "VCRIGHT_feedForwardPullDownScalar";
BA_ "Confidence" SG_ 691 VCRIGHT_convectionTargetLeft 0;
BA_ "GenSigSNA" SG_ 691 VCRIGHT_convectionTargetLeft "511";
BA_ "Confidence" SG_ 691 VCRIGHT_convectionTargetRight 0;
BA_ "GenSigSNA" SG_ 691 VCRIGHT_convectionTargetRight "511";
BA_ "Confidence" SG_ 691 VCRIGHT_convectionDeliveredLeft 0;
BA_ "GenSigSNA" SG_ 691 VCRIGHT_convectionDeliveredLeft "511";
BA_ "Confidence" SG_ 691 VCRIGHT_convectionDeliveredRight 0;
BA_ "GenSigSNA" SG_ 691 VCRIGHT_convectionDeliveredRight "511";
BA_ "Confidence" SG_ 691 VCRIGHT_solarLoadRightOccupant 0;
BA_ "GenSigSNA" SG_ 691 VCRIGHT_solarLoadRightOccupant "127";
BA_ "Confidence" SG_ 691 VCRIGHT_solarLoadLeftOccupant 0;
BA_ "GenSigSNA" SG_ 691 VCRIGHT_solarLoadLeftOccupant "127";
BA_ "Confidence" SG_ 691 VCRIGHT_ptcShutOutletMitigationA 0;
BA_ "SystemSignalLongSymbol" SG_ 691 VCRIGHT_ptcShutOutletMitigationA "VCRIGHT_ptcShutOutletMitigationActive";
BA_ "Confidence" SG_ 691 VCRIGHT_solarLoadFromThsTemp 0;
BA_ "GenSigSNA" SG_ 691 VCRIGHT_solarLoadFromThsTemp "255";
BA_ "SystemSignalLongSymbol" SG_ 691 VCRIGHT_ptcHeaterReqAirpathBlock "VCRIGHT_ptcHeaterReqAirpathBlocked";
BA_ "Confidence" SG_ 691 VCRIGHT_hvacQdotFeedforward 1;
BA_ "Confidence" SG_ 691 VCRIGHT_evapLoadInFresh 1;
BA_ "Confidence" SG_ 691 VCRIGHT_evapLoadInRecirc 1;
BA_ "Confidence" SG_ 691 VCRIGHT_cabinTempWshldDefog 0;
BA_ "GenSigSNA" SG_ 691 VCRIGHT_cabinTempWshldDefog "255";
BA_ "Confidence" SG_ 691 VCRIGHT_cabinTempWshldDefogTop 0;
BA_ "GenSigSNA" SG_ 691 VCRIGHT_cabinTempWshldDefogTop "255";
BA_ "Confidence" SG_ 691 VCRIGHT_hvacLHBleedVoltage 0;
BA_ "Confidence" SG_ 691 VCRIGHT_hvacRHBleedVoltage 0;
BA_ "Confidence" SG_ 691 VCRIGHT_hvacLHVaneVoltage 0;
BA_ "Confidence" SG_ 691 VCRIGHT_hvacRHVaneVoltage 0;
BA_ "Confidence" SG_ 691 VCRIGHT_hvacUpperModeVoltage 0;
BA_ "Confidence" SG_ 691 VCRIGHT_hvacLowerModeVoltage 0;
BA_ "Confidence" SG_ 691 VCRIGHT_hvacIntakeVoltage 0;
BA_ "Confidence" SG_ 691 VCRIGHT_cabinTempBreathLevelFHea 1;
BA_ "GenSigSNA" SG_ 691 VCRIGHT_cabinTempBreathLevelFHea "255";
BA_ "SystemSignalLongSymbol" SG_ 691 VCRIGHT_cabinTempBreathLevelFHea "VCRIGHT_cabinTempBreathLevelFHeating";
BA_ "Confidence" SG_ 691 VCRIGHT_cabinTempBreathLevelFCoo 1;
BA_ "GenSigSNA" SG_ 691 VCRIGHT_cabinTempBreathLevelFCoo "255";
BA_ "SystemSignalLongSymbol" SG_ 691 VCRIGHT_cabinTempBreathLevelFCoo "VCRIGHT_cabinTempBreathLevelFCooling";
BA_ "Confidence" SG_ 691 VCRIGHT_cabinTempBreathLeve_0002 1;
BA_ "GenSigSNA" SG_ 691 VCRIGHT_cabinTempBreathLeve_0002 "255";
BA_ "SystemSignalLongSymbol" SG_ 691 VCRIGHT_cabinTempBreathLeve_0002 "VCRIGHT_cabinTempBreathLevelF5minHeating";
BA_ "Confidence" SG_ 691 VCRIGHT_cabinTempBreathLevelF5mi 1;
BA_ "GenSigSNA" SG_ 691 VCRIGHT_cabinTempBreathLevelF5mi "255";
BA_ "SystemSignalLongSymbol" SG_ 691 VCRIGHT_cabinTempBreathLevelF5mi "VCRIGHT_cabinTempBreathLevelF5minCooling";
BA_ "Confidence" SG_ 691 VCRIGHT_cabinTempBreathLeve_0001 1;
BA_ "GenSigSNA" SG_ 691 VCRIGHT_cabinTempBreathLeve_0001 "255";
BA_ "SystemSignalLongSymbol" SG_ 691 VCRIGHT_cabinTempBreathLeve_0001 "VCRIGHT_cabinTempBreathLevelF10minHeating";
BA_ "Confidence" SG_ 691 VCRIGHT_cabinTempBreathLevelF10m 1;
BA_ "GenSigSNA" SG_ 691 VCRIGHT_cabinTempBreathLevelF10m "255";
BA_ "SystemSignalLongSymbol" SG_ 691 VCRIGHT_cabinTempBreathLevelF10m "VCRIGHT_cabinTempBreathLevelF10minCooling";
BA_ "Confidence" SG_ 691 VCRIGHT_cabinTempInteriorFHeatin 1;
BA_ "GenSigSNA" SG_ 691 VCRIGHT_cabinTempInteriorFHeatin "255";
BA_ "SystemSignalLongSymbol" SG_ 691 VCRIGHT_cabinTempInteriorFHeatin "VCRIGHT_cabinTempInteriorFHeating";
BA_ "Confidence" SG_ 691 VCRIGHT_hvacCabOvrheatProtActive 0;
BA_ "Confidence" SG_ 691 VCRIGHT_hvacCabinPurgeAllowed 0;
BA_ "Confidence" SG_ 691 VCRIGHT_hvacCabOvrheatProtAllowe 0;
BA_ "SystemSignalLongSymbol" SG_ 691 VCRIGHT_hvacCabOvrheatProtAllowe "VCRIGHT_hvacCabOvrheatProtAllowed";
BA_ "Confidence" SG_ 691 VCRIGHT_filterLifeBlowerTorque 1;
BA_ "GenSigSNA" SG_ 691 VCRIGHT_filterLifeBlowerTorque "1023";
BA_ "Confidence" SG_ 691 VCRIGHT_cabinTempFanCurrent 0;
BA_ "Confidence" SG_ 691 VCRIGHT_cabinTempFanOutput 0;
BA_ "Confidence" SG_ 691 VCRIGHT_cloudinessEstimatedPct 0;
BA_ "Confidence" SG_ 691 VCRIGHT_solarLoadOnVehFiltered 0;
BA_ "GenSigSNA" SG_ 691 VCRIGHT_solarLoadOnVehFiltered "255";
BA_ "Confidence" SG_ 691 VCRIGHT_cabinTempProbeEstimate 0;
BA_ "GenSigSNA" SG_ 691 VCRIGHT_cabinTempProbeEstimate "255";
BA_ "Confidence" SG_ 691 VCRIGHT_cabinTempThs 0;
BA_ "GenSigSNA" SG_ 691 VCRIGHT_cabinTempThs "255";
BA_ "Confidence" SG_ 691 VCRIGHT_cabinTempThsBracket 0;
BA_ "GenSigSNA" SG_ 691 VCRIGHT_cabinTempThsBracket "255";
BA_ "Confidence" SG_ 691 VCRIGHT_leftHeatOvertempProtect 0;
BA_ "Confidence" SG_ 691 VCRIGHT_rightHeatOvertempProtect 0;
BA_ "Confidence" SG_ 691 VCRIGHT_CO2ppm 0;
BA_ "GenSigSNA" SG_ 691 VCRIGHT_CO2ppm "1023";
BA_ "Confidence" SG_ 691 VCRIGHT_timeLeftToCabinModelInit 0;
BA_ "Confidence" SG_ 691 VCRIGHT_hvacEstimateWindshieldRH 0;
BA_ "Confidence" SG_ 691 VCRIGHT_hvacFoggingRiskLevel 0;
BA_ "Confidence" SG_ 691 VCRIGHT_hvacCabinHumidityLevel 0;
BA_ "Confidence" SG_ 691 VCRIGHT_hvacFlashFoggingDetected 0;
BA_ "Confidence" SG_ 691 VCRIGHT_solarSensitivityInfr 0;
BA_ "Confidence" SG_ 691 VCRIGHT_solarSensitivityInfrCorr 0;
BA_ "Confidence" SG_ 691 VCRIGHT_lumbarCurrent 0;
BA_ "Confidence" SG_ 691 VCRIGHT_ocsCurrent 0;
BA_ "Confidence" SG_ 691 VCRIGHT_rcmCurrent 0;
BA_ "Confidence" SG_ 691 VCRIGHT_radioTunerCurrent 0;
BA_ "Confidence" SG_ 691 VCRIGHT_rearOilPumpCurrent 0;
BA_ "Confidence" SG_ 691 VCRIGHT_rearDefrostCurrent 0;
BA_ "Confidence" SG_ 691 VCRIGHT_tailLightCurrent 0;
BA_ "Confidence" SG_ 691 VCRIGHT_turnTailStopLightCurrent 0;
BA_ "Confidence" SG_ 691 VCRIGHT_reverseFogLightsCurrent 0;
BA_ "GenSigSNA" SG_ 691 VCRIGHT_reverseFogLightsCurrent "15";
BA_ "Confidence" SG_ 691 VCRIGHT_stopReverseTurnLightCurr 0;
BA_ "SystemSignalLongSymbol" SG_ 691 VCRIGHT_stopReverseTurnLightCurr "VCRIGHT_stopReverseTurnLightCurrent";
BA_ "Confidence" SG_ 691 VCRIGHT_sideMirrorCurrent 0;
BA_ "Confidence" SG_ 691 VCRIGHT_sideMirrorHeaterCurrent 0;
BA_ "GenSigSNA" SG_ 691 VCRIGHT_sideMirrorHeaterCurrent "31";
BA_ "Confidence" SG_ 691 VCRIGHT_frontSeatHeatCushionPwr 0;
BA_ "Confidence" SG_ 691 VCRIGHT_trunkInteriorLEDCurrent 0;
BA_ "GenSigSNA" SG_ 691 VCRIGHT_trunkInteriorLEDCurrent "15";
BA_ "Confidence" SG_ 691 VCRIGHT_mapPocketLEDsCurrent 0;
BA_ "GenSigSNA" SG_ 691 VCRIGHT_mapPocketLEDsCurrent "15";
BA_ "Confidence" SG_ 691 VCRIGHT_miscEFuseCurrent 0;
BA_ "GenSigSNA" SG_ 691 VCRIGHT_miscEFuseCurrent "31";
BA_ "Confidence" SG_ 691 VCRIGHT_interiorHandleLEDCurrent 0;
BA_ "Confidence" SG_ 691 VCRIGHT_miscInteriorLightsCurren 0;
BA_ "GenSigSNA" SG_ 691 VCRIGHT_miscInteriorLightsCurren "7";
BA_ "SystemSignalLongSymbol" SG_ 691 VCRIGHT_miscInteriorLightsCurren "VCRIGHT_miscInteriorLightsCurrent";
BA_ "Confidence" SG_ 691 VCRIGHT_frontPuddleLEDCurrent 0;
BA_ "GenSigSNA" SG_ 691 VCRIGHT_frontPuddleLEDCurrent "7";
BA_ "Confidence" SG_ 691 VCRIGHT_rearPuddleLEDCurrent 0;
BA_ "GenSigSNA" SG_ 691 VCRIGHT_rearPuddleLEDCurrent "7";
BA_ "Confidence" SG_ 691 VCRIGHT_liftgateShutfaceLEDCurre 0;
BA_ "GenSigSNA" SG_ 691 VCRIGHT_liftgateShutfaceLEDCurre "7";
BA_ "SystemSignalLongSymbol" SG_ 691 VCRIGHT_liftgateShutfaceLEDCurre "VCRIGHT_liftgateShutfaceLEDCurrent";
BA_ "Confidence" SG_ 691 VCRIGHT_3rSeatTOSCurrent 0;
BA_ "GenSigSNA" SG_ 691 VCRIGHT_3rSeatTOSCurrent "15";
BA_ "Confidence" SG_ 691 VCRIGHT_vbatFusedCurrent 0;
BA_ "GenSigSNA" SG_ 691 VCRIGHT_vbatFusedCurrent "15";
BA_ "Confidence" SG_ 691 VCRIGHT_cabinTempGlassGridHeater 0;
BA_ "GenSigSNA" SG_ 691 VCRIGHT_cabinTempGlassGridHeater "255";
BA_ "Confidence" SG_ 691 VCRIGHT_hvacAirflowReasonRight 0;
BA_ "Confidence" SG_ 691 VCRIGHT_hvacAirflowReasonLeft 0;
BA_ "Confidence" SG_ 691 VCRIGHT_hvacMassflowTargetLeft 0;
BA_ "Confidence" SG_ 691 VCRIGHT_hvacMassflowTargetRight 0;
BA_ "Confidence" SG_ 691 VCRIGHT_solarLoadLeftOccupantFil 0;
BA_ "GenSigSNA" SG_ 691 VCRIGHT_solarLoadLeftOccupantFil "127";
BA_ "SystemSignalLongSymbol" SG_ 691 VCRIGHT_solarLoadLeftOccupantFil "VCRIGHT_solarLoadLeftOccupantFilt";
BA_ "Confidence" SG_ 691 VCRIGHT_solarLoadRightOccupantFi 0;
BA_ "GenSigSNA" SG_ 691 VCRIGHT_solarLoadRightOccupantFi "127";
BA_ "SystemSignalLongSymbol" SG_ 691 VCRIGHT_solarLoadRightOccupantFi "VCRIGHT_solarLoadRightOccupantFilt";
BA_ "Confidence" SG_ 691 VCRIGHT_windshieldRHCapped 0;
BA_ "Confidence" SG_ 691 VCRIGHT_feedbackWarmUpScalar 0;
BA_ "Confidence" SG_ 691 VCRIGHT_maxMassflowScalarWarmUp 0;
BA_ "Confidence" SG_ 691 VCRIGHT_feedforwardWarmUpScalar 0;
BA_ "Confidence" SG_ 691 VCRIGHT_frontSeatHeatBackrestPwr 0;
BA_ "Confidence" SG_ 691 VCRIGHT_maxMassflowScalar 0;
BA_ "Confidence" SG_ 691 VCRIGHT_massflowTargetAutoInManu 0;
BA_ "SystemSignalLongSymbol" SG_ 691 VCRIGHT_massflowTargetAutoInManu "VCRIGHT_massflowTargetAutoInManualMode";
BA_ "Confidence" SG_ 691 VCRIGHT_airflowReasonAutoInManua 0;
BA_ "SystemSignalLongSymbol" SG_ 691 VCRIGHT_airflowReasonAutoInManua "VCRIGHT_airflowReasonAutoInManualMode";
BA_ "Confidence" SG_ 691 VCRIGHT_airflowReasonAutoIn_0001 0;
BA_ "SystemSignalLongSymbol" SG_ 691 VCRIGHT_airflowReasonAutoIn_0001 "VCRIGHT_airflowReasonAutoInManualModeLeft";
BA_ "Confidence" SG_ 691 VCRIGHT_airflowReasonAutoIn_0002 0;
BA_ "SystemSignalLongSymbol" SG_ 691 VCRIGHT_airflowReasonAutoIn_0002 "VCRIGHT_airflowReasonAutoInManualModeRight";
BA_ "Confidence" SG_ 691 VCRIGHT_cabinTempInteriorFCoolin 1;
BA_ "GenSigSNA" SG_ 691 VCRIGHT_cabinTempInteriorFCoolin "255";
BA_ "SystemSignalLongSymbol" SG_ 691 VCRIGHT_cabinTempInteriorFCoolin "VCRIGHT_cabinTempInteriorFCooling";
BA_ "Confidence" SG_ 691 VCRIGHT_averageDuctTempFHeating 1;
BA_ "GenSigSNA" SG_ 691 VCRIGHT_averageDuctTempFHeating "255";
BA_ "Confidence" SG_ 691 VCRIGHT_averageDuctTempFCooling 1;
BA_ "GenSigSNA" SG_ 691 VCRIGHT_averageDuctTempFCooling "255";
BA_ "Confidence" SG_ 691 VCRIGHT_hvacBiLevelWhsldRhEst 0;
BA_ "Confidence" SG_ 691 VCRIGHT_steeringWheelSurfaceTemp 0;
BA_ "GenSigSNA" SG_ 691 VCRIGHT_steeringWheelSurfaceTemp "1023";
BA_ "SystemSignalLongSymbol" SG_ 691 VCRIGHT_steeringWheelSurfaceTemp "VCRIGHT_steeringWheelSurfaceTempEst";
BA_ "Confidence" SG_ 691 VCRIGHT_steeringWheelSurfac_0001 0;
BA_ "GenSigSNA" SG_ 691 VCRIGHT_steeringWheelSurfac_0001 "1023";
BA_ "SystemSignalLongSymbol" SG_ 691 VCRIGHT_steeringWheelSurfac_0001 "VCRIGHT_steeringWheelSurfaceTempTgt";
BA_ "Confidence" SG_ 691 VCRIGHT_timeToComfortHeating 0;
BA_ "Confidence" SG_ 691 VCRIGHT_timeToComfortCooling 0;
BA_ "Confidence" SG_ 691 VCRIGHT_cabinWaterMassRaw 1;
BA_ "GenSigSNA" SG_ 691 VCRIGHT_cabinWaterMassRaw "255";
BA_ "Confidence" SG_ 691 VCRIGHT_massflowSingleZoneSplit 1;
BA_ "Confidence" SG_ 691 VCRIGHT_VOCPurgeState 1;
BA_ "Confidence" SG_ 691 VCRIGHT_cameraFoggingMonitorStat 1;
BA_ "SystemSignalLongSymbol" SG_ 691 VCRIGHT_cameraFoggingMonitorStat "VCRIGHT_cameraFoggingMonitorState";
BA_ "Confidence" SG_ 691 VCRIGHT_cabinOverheatProtectNotR 0;
BA_ "SystemSignalLongSymbol" SG_ 691 VCRIGHT_cabinOverheatProtectNotR "VCRIGHT_cabinOverheatProtectNotRunningReasonRaw";
BA_ "Confidence" SG_ 691 VCRIGHT_hvacIntakeReason 0;
BA_ "Confidence" SG_ 691 VCRIGHT_hvacCabinPurgeActive 0;
BA_ "Confidence" SG_ 691 VCRIGHT_solarAzimuthCarRef 0;
BA_ "GenSigSNA" SG_ 691 VCRIGHT_solarAzimuthCarRef "1025";
BA_ "Confidence" SG_ 691 VCRIGHT_massflowPulldownBias 0;
BA_ "Confidence" SG_ 691 VCRIGHT_evapPulldownBias 0;
BA_ "Confidence" SG_ 691 VCRIGHT_modeledMassflowFresh 0;
BA_ "Confidence" SG_ 691 VCRIGHT_modeledMassflowRecirc 0;
BA_ "Confidence" SG_ 691 VCRIGHT_hvacLimpModeStatus 0;
BA_ "Confidence" SG_ 691 VCRIGHT_hvacEstimatedCameraWinds 1;
BA_ "SystemSignalLongSymbol" SG_ 691 VCRIGHT_hvacEstimatedCameraWinds "VCRIGHT_hvacEstimatedCameraWindshieldRH";
BA_ "Confidence" SG_ 1862 VCRIGHT_frontOccupancyStatus 0;
BA_ "GenSigSNA" SG_ 1862 VCRIGHT_frontOccupancyStatus "7";
BA_ "Confidence" SG_ 1862 VCRIGHT_frontBuckleStatus 0;
BA_ "GenSigSNA" SG_ 1862 VCRIGHT_frontBuckleStatus "3";
BA_ "Confidence" SG_ 1862 VCRIGHT_rearCenterBuckleStatus 0;
BA_ "GenSigSNA" SG_ 1862 VCRIGHT_rearCenterBuckleStatus "3";
BA_ "Confidence" SG_ 1862 VCRIGHT_rearRightBuckleStatus 0;
BA_ "GenSigSNA" SG_ 1862 VCRIGHT_rearRightBuckleStatus "3";
BA_ "Confidence" SG_ 1862 VCRIGHT_rearRightOccupancyStatus 0;
BA_ "GenSigSNA" SG_ 1862 VCRIGHT_rearRightOccupancyStatus "3";
BA_ "Confidence" SG_ 1862 VCRIGHT_3RowLeftBuckleStatus 0;
BA_ "GenSigSNA" SG_ 1862 VCRIGHT_3RowLeftBuckleStatus "3";
BA_ "Confidence" SG_ 1862 VCRIGHT_3RowRightBuckleStatus 0;
BA_ "GenSigSNA" SG_ 1862 VCRIGHT_3RowRightBuckleStatus "3";
BA_ "Confidence" SG_ 1862 VCRIGHT_3RowLeftOccupancyStatus 0;
BA_ "GenSigSNA" SG_ 1862 VCRIGHT_3RowLeftOccupancyStatus "3";
BA_ "Confidence" SG_ 1862 VCRIGHT_3RowRightOccupancyStatus 0;
BA_ "GenSigSNA" SG_ 1862 VCRIGHT_3RowRightOccupancyStatus "3";
BA_ "Confidence" SG_ 1862 VCRIGHT_seatTrackPosition 0;
BA_ "GenSigSNA" SG_ 1862 VCRIGHT_seatTrackPosition "7";
BA_ "Confidence" SG_ 1862 VCRIGHT_occupantClassification 0;
BA_ "GenSigSNA" SG_ 1862 VCRIGHT_occupantClassification "7";
BA_ "Confidence" SG_ 1862 VCRIGHT_occupantClassificationQF 0;
BA_ "Confidence" SG_ 1862 VCRIGHT_classificationEnabled 0;
BA_ "Confidence" SG_ 1862 VCRIGHT_classificationEnabledQF 0;
BA_ "Confidence" SG_ 1862 VCRIGHT_restraintStatusCounter 0;
BA_ "Confidence" SG_ 1862 VCRIGHT_restraintStatusChecksum 0;
BA_ "Confidence" SG_ 1251 VCRIGHT_seatStatusIndex 1;
BA_ "Confidence" SG_ 1251 VCRIGHT_frontSeatTrackPos 0;
BA_ "Confidence" SG_ 1251 VCRIGHT_frontSeatTrackCurrent 0;
BA_ "Confidence" SG_ 1251 VCRIGHT_frontSeatTrackDuty 0;
BA_ "Confidence" SG_ 1251 VCRIGHT_frontSeatTrackState 0;
BA_ "Confidence" SG_ 1251 VCRIGHT_frontSeatTrackCalibrated 0;
BA_ "Confidence" SG_ 1251 VCRIGHT_frontSeatTrackLog 0;
BA_ "Confidence" SG_ 1251 VCRIGHT_frontSeatTrackBridgeSt 0;
BA_ "Confidence" SG_ 1251 VCRIGHT_frontSeatBackPos 0;
BA_ "Confidence" SG_ 1251 VCRIGHT_frontSeatBackCurrent 0;
BA_ "Confidence" SG_ 1251 VCRIGHT_frontSeatBackDuty 0;
BA_ "Confidence" SG_ 1251 VCRIGHT_frontSeatBackState 0;
BA_ "Confidence" SG_ 1251 VCRIGHT_frontSeatBackCalibrated 0;
BA_ "Confidence" SG_ 1251 VCRIGHT_frontSeatBackLog 0;
BA_ "Confidence" SG_ 1251 VCRIGHT_frontSeatBackBridgeSt 0;
BA_ "Confidence" SG_ 1251 VCRIGHT_frontSeatLiftPos 0;
BA_ "Confidence" SG_ 1251 VCRIGHT_frontSeatLiftCurrent 0;
BA_ "Confidence" SG_ 1251 VCRIGHT_frontSeatLiftDuty 0;
BA_ "Confidence" SG_ 1251 VCRIGHT_frontSeatLiftState 0;
BA_ "Confidence" SG_ 1251 VCRIGHT_frontSeatLiftCalibrated 0;
BA_ "Confidence" SG_ 1251 VCRIGHT_frontSeatLiftLog 0;
BA_ "Confidence" SG_ 1251 VCRIGHT_frontSeatLiftBridgeSt 0;
BA_ "Confidence" SG_ 1251 VCRIGHT_frontSeatTiltPos 0;
BA_ "Confidence" SG_ 1251 VCRIGHT_frontSeatTiltCurrent 0;
BA_ "Confidence" SG_ 1251 VCRIGHT_frontSeatTiltDuty 0;
BA_ "Confidence" SG_ 1251 VCRIGHT_frontSeatTiltState 0;
BA_ "Confidence" SG_ 1251 VCRIGHT_frontSeatTiltCalibrated 0;
BA_ "Confidence" SG_ 1251 VCRIGHT_frontSeatTiltLog 0;
BA_ "Confidence" SG_ 1251 VCRIGHT_frontSeatTiltBridgeSt 0;
BA_ "Confidence" SG_ 1251 VCRIGHT_lumbarAState 0;
BA_ "Confidence" SG_ 1251 VCRIGHT_lumbarBState 0;
BA_ "Confidence" SG_ 1251 VCRIGHT_lumbarAPressureHpa 0;
BA_ "Confidence" SG_ 1251 VCRIGHT_lumbarAPressureHpaFilt 0;
BA_ "Confidence" SG_ 1251 VCRIGHT_lumbarBPressureHpa 0;
BA_ "Confidence" SG_ 1251 VCRIGHT_lumbarBPressureHpaFilt 0;
BA_ "Confidence" SG_ 1251 VCRIGHT_lumbarActiveTooLongErr 0;
BA_ "Confidence" SG_ 1251 VCRIGHT_lumbarMaxPErr 0;
BA_ "Confidence" SG_ 1251 VCRIGHT_lumbarOvercurrentErr 0;
BA_ "Confidence" SG_ 1251 VCRIGHT_lumbarMaxOperatingPErr 0;
BA_ "Confidence" SG_ 1251 VCRIGHT_lumbarMinPErr 0;
BA_ "Confidence" SG_ 1251 VCRIGHT_lumbarGeneralErr 0;
BA_ "Confidence" SG_ 1251 VCRIGHT_lumbarDevMaxPumpPressA 0;
BA_ "Confidence" SG_ 1251 VCRIGHT_lumbarDevMaxPumpPressB 0;
BA_ "Confidence" SG_ 1251 VCRIGHT_frontSeatTrackPosReal 0;
BA_ "Confidence" SG_ 1251 VCRIGHT_frontSeatBackPosReal 0;
BA_ "Confidence" SG_ 1251 VCRIGHT_frontSeatLiftPosReal 0;
BA_ "Confidence" SG_ 1251 VCRIGHT_frontSeatTiltPosReal 0;
BA_ "Confidence" SG_ 1251 VCRIGHT_frontSeatTrackPosOffset 0;
BA_ "Confidence" SG_ 1251 VCRIGHT_frontSeatBackPosOffset 0;
BA_ "Confidence" SG_ 1251 VCRIGHT_frontSeatLiftPosOffset 0;
BA_ "Confidence" SG_ 1251 VCRIGHT_frontSeatTiltPosOffset 0;
BA_ "Confidence" SG_ 739 VCRIGHT_seatStatus2Index 1;
BA_ "Confidence" SG_ 739 VCRIGHT_frontSeatHeatCurrent 0;
BA_ "GenSigSNA" SG_ 739 VCRIGHT_frontSeatHeatCurrent "12";
BA_ "Confidence" SG_ 739 VCRIGHT_frontSeatHeatDuty 0;
BA_ "Confidence" SG_ 739 VCRIGHT_frontSeatHeatTmp 0;
BA_ "Confidence" SG_ 739 VCRIGHT_frontSeatHeatTmpTarget 0;
BA_ "Confidence" SG_ 739 VCRIGHT_frontSeatHeatInhibited 0;
BA_ "Confidence" SG_ 739 VCRIGHT_frontSeatHeatPowered 0;
BA_ "Confidence" SG_ 739 VCRIGHT_rearLSeatHeatCurrent 0;
BA_ "Confidence" SG_ 739 VCRIGHT_rearLSeatHeatDuty 0;
BA_ "Confidence" SG_ 739 VCRIGHT_rearLSeatHeatTmp 0;
BA_ "Confidence" SG_ 739 VCRIGHT_rearLSeatHeatTmpTarget 0;
BA_ "Confidence" SG_ 739 VCRIGHT_rearLSeatHeatInhibited 0;
BA_ "Confidence" SG_ 739 VCRIGHT_rearLSeatHeatPowered 0;
BA_ "Confidence" SG_ 739 VCRIGHT_rearCSeatHeatCurrent 0;
BA_ "Confidence" SG_ 739 VCRIGHT_rearCSeatHeatDuty 0;
BA_ "Confidence" SG_ 739 VCRIGHT_rearCSeatHeatTmp 0;
BA_ "Confidence" SG_ 739 VCRIGHT_rearCSeatHeatTmpTarget 0;
BA_ "Confidence" SG_ 739 VCRIGHT_rearCSeatHeatInhibited 0;
BA_ "Confidence" SG_ 739 VCRIGHT_rearCSeatHeatPowered 0;
BA_ "Confidence" SG_ 739 VCRIGHT_rearRSeatHeatCurrent 0;
BA_ "Confidence" SG_ 739 VCRIGHT_rearRSeatHeatDuty 0;
BA_ "Confidence" SG_ 739 VCRIGHT_rearRSeatHeatTmp 0;
BA_ "Confidence" SG_ 739 VCRIGHT_rearRSeatHeatTmpTarget 0;
BA_ "Confidence" SG_ 739 VCRIGHT_rearRSeatHeatInhibited 0;
BA_ "Confidence" SG_ 739 VCRIGHT_rearRSeatHeatPowered 0;
BA_ "Confidence" SG_ 835 VCRIGHT_LVBatteryTypeDBG 0;
BA_ "Confidence" SG_ 835 VCRIGHT_rearDefrostState 0;
BA_ "GenSigSNA" SG_ 835 VCRIGHT_rearDefrostState "0";
BA_ "Confidence" SG_ 835 VCRIGHT_mirrorHeatState 0;
BA_ "GenSigSNA" SG_ 835 VCRIGHT_mirrorHeatState "0";
BA_ "Confidence" SG_ 835 VCRIGHT_OTAState 0;
BA_ "Confidence" SG_ 835 VCRIGHT_5AVoltage 0;
BA_ "Confidence" SG_ 835 VCRIGHT_vbatProt 0;
BA_ "Confidence" SG_ 835 VCRIGHT_rationalityAggregateCurr 0;
BA_ "SystemSignalLongSymbol" SG_ 835 VCRIGHT_rationalityAggregateCurr "VCRIGHT_rationalityAggregateCurrent";
BA_ "Confidence" SG_ 835 VCRIGHT_eFuseMgmtVoltageMonitor 0;
BA_ "Confidence" SG_ 835 VCRIGHT_isSteeringWheelHeaterReq 0;
BA_ "Confidence" SG_ 835 VCRIGHT_steeringWheelHeaterDCTgt 0;
BA_ "GenSigSNA" SG_ 835 VCRIGHT_steeringWheelHeaterDCTgt "127";
BA_ "Confidence" SG_ 963 VCRIGHT_switchStatusIndex 1;
BA_ "Confidence" SG_ 963 VCRIGHT_trunkExtReleasePressedPe 0;
BA_ "SystemSignalLongSymbol" SG_ 963 VCRIGHT_trunkExtReleasePressedPe "VCRIGHT_trunkExtReleasePressedPersist";
BA_ "Confidence" SG_ 963 VCRIGHT_frontSeatTrackBack 0;
BA_ "GenSigSNA" SG_ 963 VCRIGHT_frontSeatTrackBack "0";
BA_ "Confidence" SG_ 963 VCRIGHT_frontSeatTrackForward 0;
BA_ "GenSigSNA" SG_ 963 VCRIGHT_frontSeatTrackForward "0";
BA_ "Confidence" SG_ 963 VCRIGHT_frontSeatTiltDown 0;
BA_ "GenSigSNA" SG_ 963 VCRIGHT_frontSeatTiltDown "0";
BA_ "Confidence" SG_ 963 VCRIGHT_frontSeatTiltUp 0;
BA_ "GenSigSNA" SG_ 963 VCRIGHT_frontSeatTiltUp "0";
BA_ "Confidence" SG_ 963 VCRIGHT_frontSeatLiftDown 0;
BA_ "GenSigSNA" SG_ 963 VCRIGHT_frontSeatLiftDown "0";
BA_ "Confidence" SG_ 963 VCRIGHT_frontSeatLiftUp 0;
BA_ "GenSigSNA" SG_ 963 VCRIGHT_frontSeatLiftUp "0";
BA_ "Confidence" SG_ 963 VCRIGHT_frontSeatBackrestBack 0;
BA_ "GenSigSNA" SG_ 963 VCRIGHT_frontSeatBackrestBack "0";
BA_ "Confidence" SG_ 963 VCRIGHT_frontSeatBackrestForward 0;
BA_ "GenSigSNA" SG_ 963 VCRIGHT_frontSeatBackrestForward "0";
BA_ "Confidence" SG_ 963 VCRIGHT_frontSeatLumbarDown 0;
BA_ "GenSigSNA" SG_ 963 VCRIGHT_frontSeatLumbarDown "0";
BA_ "Confidence" SG_ 963 VCRIGHT_frontSeatLumbarUp 0;
BA_ "GenSigSNA" SG_ 963 VCRIGHT_frontSeatLumbarUp "0";
BA_ "Confidence" SG_ 963 VCRIGHT_frontSeatLumbarIn 0;
BA_ "GenSigSNA" SG_ 963 VCRIGHT_frontSeatLumbarIn "0";
BA_ "Confidence" SG_ 963 VCRIGHT_frontSeatLumbarOut 0;
BA_ "GenSigSNA" SG_ 963 VCRIGHT_frontSeatLumbarOut "0";
BA_ "Confidence" SG_ 963 VCRIGHT_frontHandlePWM 0;
BA_ "Confidence" SG_ 963 VCRIGHT_rearHandlePWM 0;
BA_ "Confidence" SG_ 963 VCRIGHT_gloveboxLightCurrent 0;
BA_ "Confidence" SG_ 963 VCRIGHT_frontSeatALR 0;
BA_ "GenSigSNA" SG_ 963 VCRIGHT_frontSeatALR "0";
BA_ "Confidence" SG_ 963 VCRIGHT_frontSeatResistiveOccupa 0;
BA_ "GenSigSNA" SG_ 963 VCRIGHT_frontSeatResistiveOccupa "0";
BA_ "SystemSignalLongSymbol" SG_ 963 VCRIGHT_frontSeatResistiveOccupa "VCRIGHT_frontSeatResistiveOccupancy";
BA_ "Confidence" SG_ 963 VCRIGHT_2RowSeatReclineSwitchpac 0;
BA_ "SystemSignalLongSymbol" SG_ 963 VCRIGHT_2RowSeatReclineSwitchpac "VCRIGHT_2RowSeatReclineSwitchpackState";
BA_ "Confidence" SG_ 537 VCSEC_TPMSDataIndex 1;
BA_ "Confidence" SG_ 537 VCSEC_TPMSCapabilityPressureInAd 0;
BA_ "SystemSignalLongSymbol" SG_ 537 VCSEC_TPMSCapabilityPressureInAd "VCSEC_TPMSCapabilityPressureInAdv0";
BA_ "Confidence" SG_ 537 VCSEC_TPMSCapabilityConfigurable 0;
BA_ "SystemSignalLongSymbol" SG_ 537 VCSEC_TPMSCapabilityConfigurable "VCSEC_TPMSCapabilityConfigurablePressure0";
BA_ "Confidence" SG_ 537 VCSEC_TPMSPressureRateOfChange0 0;
BA_ "Confidence" SG_ 537 VCSEC_TPMSPressure0 0;
BA_ "GenSigSNA" SG_ 537 VCSEC_TPMSPressure0 "511";
BA_ "Confidence" SG_ 537 VCSEC_TPMSTemperature0 0;
BA_ "GenSigSNA" SG_ 537 VCSEC_TPMSTemperature0 "255";
BA_ "Confidence" SG_ 537 VCSEC_TPMSBatVoltage0 0;
BA_ "GenSigSNA" SG_ 537 VCSEC_TPMSBatVoltage0 "255";
BA_ "Confidence" SG_ 537 VCSEC_TPMSLocation0 0;
BA_ "Confidence" SG_ 537 VCSEC_TPMSTemperatureCompensated 0;
BA_ "GenSigSNA" SG_ 537 VCSEC_TPMSTemperatureCompensated "511";
BA_ "SystemSignalLongSymbol" SG_ 537 VCSEC_TPMSTemperatureCompensated "VCSEC_TPMSTemperatureCompensatedPressure0";
BA_ "Confidence" SG_ 537 VCSEC_TPMSCapabilityPressur_0001 0;
BA_ "SystemSignalLongSymbol" SG_ 537 VCSEC_TPMSCapabilityPressur_0001 "VCSEC_TPMSCapabilityPressureInAdv1";
BA_ "Confidence" SG_ 537 VCSEC_TPMSCapabilityConfigu_0001 0;
BA_ "SystemSignalLongSymbol" SG_ 537 VCSEC_TPMSCapabilityConfigu_0001 "VCSEC_TPMSCapabilityConfigurablePressure1";
BA_ "Confidence" SG_ 537 VCSEC_TPMSPressureRateOfChange1 0;
BA_ "Confidence" SG_ 537 VCSEC_TPMSPressure1 0;
BA_ "GenSigSNA" SG_ 537 VCSEC_TPMSPressure1 "511";
BA_ "Confidence" SG_ 537 VCSEC_TPMSTemperature1 0;
BA_ "GenSigSNA" SG_ 537 VCSEC_TPMSTemperature1 "255";
BA_ "Confidence" SG_ 537 VCSEC_TPMSBatVoltage1 0;
BA_ "GenSigSNA" SG_ 537 VCSEC_TPMSBatVoltage1 "255";
BA_ "Confidence" SG_ 537 VCSEC_TPMSLocation1 0;
BA_ "Confidence" SG_ 537 VCSEC_TPMSTemperatureCompen_0001 0;
BA_ "GenSigSNA" SG_ 537 VCSEC_TPMSTemperatureCompen_0001 "511";
BA_ "SystemSignalLongSymbol" SG_ 537 VCSEC_TPMSTemperatureCompen_0001 "VCSEC_TPMSTemperatureCompensatedPressure1";
BA_ "Confidence" SG_ 537 VCSEC_TPMSCapabilityPressur_0002 0;
BA_ "SystemSignalLongSymbol" SG_ 537 VCSEC_TPMSCapabilityPressur_0002 "VCSEC_TPMSCapabilityPressureInAdv2";
BA_ "Confidence" SG_ 537 VCSEC_TPMSCapabilityConfigu_0002 0;
BA_ "SystemSignalLongSymbol" SG_ 537 VCSEC_TPMSCapabilityConfigu_0002 "VCSEC_TPMSCapabilityConfigurablePressure2";
BA_ "Confidence" SG_ 537 VCSEC_TPMSPressureRateOfChange2 0;
BA_ "Confidence" SG_ 537 VCSEC_TPMSPressure2 0;
BA_ "GenSigSNA" SG_ 537 VCSEC_TPMSPressure2 "511";
BA_ "Confidence" SG_ 537 VCSEC_TPMSTemperature2 0;
BA_ "GenSigSNA" SG_ 537 VCSEC_TPMSTemperature2 "255";
BA_ "Confidence" SG_ 537 VCSEC_TPMSBatVoltage2 0;
BA_ "GenSigSNA" SG_ 537 VCSEC_TPMSBatVoltage2 "255";
BA_ "Confidence" SG_ 537 VCSEC_TPMSLocation2 0;
BA_ "Confidence" SG_ 537 VCSEC_TPMSTemperatureCompen_0002 0;
BA_ "GenSigSNA" SG_ 537 VCSEC_TPMSTemperatureCompen_0002 "511";
BA_ "SystemSignalLongSymbol" SG_ 537 VCSEC_TPMSTemperatureCompen_0002 "VCSEC_TPMSTemperatureCompensatedPressure2";
BA_ "Confidence" SG_ 537 VCSEC_TPMSCapabilityPressur_0003 0;
BA_ "SystemSignalLongSymbol" SG_ 537 VCSEC_TPMSCapabilityPressur_0003 "VCSEC_TPMSCapabilityPressureInAdv3";
BA_ "Confidence" SG_ 537 VCSEC_TPMSCapabilityConfigu_0003 0;
BA_ "SystemSignalLongSymbol" SG_ 537 VCSEC_TPMSCapabilityConfigu_0003 "VCSEC_TPMSCapabilityConfigurablePressure3";
BA_ "Confidence" SG_ 537 VCSEC_TPMSPressureRateOfChange3 0;
BA_ "Confidence" SG_ 537 VCSEC_TPMSPressure3 0;
BA_ "GenSigSNA" SG_ 537 VCSEC_TPMSPressure3 "511";
BA_ "Confidence" SG_ 537 VCSEC_TPMSTemperature3 0;
BA_ "GenSigSNA" SG_ 537 VCSEC_TPMSTemperature3 "255";
BA_ "Confidence" SG_ 537 VCSEC_TPMSBatVoltage3 0;
BA_ "GenSigSNA" SG_ 537 VCSEC_TPMSBatVoltage3 "255";
BA_ "Confidence" SG_ 537 VCSEC_TPMSLocation3 0;
BA_ "Confidence" SG_ 537 VCSEC_TPMSTemperatureCompen_0003 0;
BA_ "GenSigSNA" SG_ 537 VCSEC_TPMSTemperatureCompen_0003 "511";
BA_ "SystemSignalLongSymbol" SG_ 537 VCSEC_TPMSTemperatureCompen_0003 "VCSEC_TPMSTemperatureCompensatedPressure3";
BA_ "Confidence" SG_ 537 VCSEC_TPMSRecommendedColdPressur 0;
BA_ "GenSigSNA" SG_ 537 VCSEC_TPMSRecommendedColdPressur "255";
BA_ "SystemSignalLongSymbol" SG_ 537 VCSEC_TPMSRecommendedColdPressur "VCSEC_TPMSRecommendedColdPressureFront";
BA_ "Confidence" SG_ 537 VCSEC_TPMSRecommendedColdPr_0001 0;
BA_ "GenSigSNA" SG_ 537 VCSEC_TPMSRecommendedColdPr_0001 "255";
BA_ "SystemSignalLongSymbol" SG_ 537 VCSEC_TPMSRecommendedColdPr_0001 "VCSEC_TPMSRecommendedColdPressureRear";
BA_ "Confidence" SG_ 537 VCSEC_TPMSFeature0 0;
BA_ "Confidence" SG_ 537 VCSEC_TPMSFeature1 0;
BA_ "Confidence" SG_ 537 VCSEC_TPMSFeature0Count 0;
BA_ "Confidence" SG_ 537 VCSEC_TPMSFeature0TimeS 0;
BA_ "Confidence" SG_ 570 VCSEC_TPMSStatusIndex 1;
BA_ "Confidence" SG_ 570 VCSEC_TPMSSystemState 1;
BA_ "Confidence" SG_ 570 VCSEC_TPMSSensorMACAddress0 0;
BA_ "Confidence" SG_ 570 VCSEC_TPMSSensorMACAddress1 0;
BA_ "Confidence" SG_ 570 VCSEC_TPMSSensorMACAddress2 0;
BA_ "Confidence" SG_ 570 VCSEC_TPMSSensorMACAddress3 0;
BA_ "Confidence" SG_ 570 VCSEC_BLESuccessfulConnEventCoun 1;
BA_ "SystemSignalLongSymbol" SG_ 570 VCSEC_BLESuccessfulConnEventCoun "VCSEC_BLESuccessfulConnEventCount0";
BA_ "Confidence" SG_ 570 VCSEC_BLEMissedConnEventCount0 1;
BA_ "Confidence" SG_ 570 VCSEC_BLECRCErrorConnEventCount0 1;
BA_ "Confidence" SG_ 570 VCSEC_BLEOtherFailuresCount0 1;
BA_ "Confidence" SG_ 570 VCSEC_BLEUnsuccessfulConnEventRa 1;
BA_ "GenSigSNA" SG_ 570 VCSEC_BLEUnsuccessfulConnEventRa "1023";
BA_ "SystemSignalLongSymbol" SG_ 570 VCSEC_BLEUnsuccessfulConnEventRa "VCSEC_BLEUnsuccessfulConnEventRate0";
BA_ "Confidence" SG_ 570 VCSEC_BLESuccessfulConnEven_0001 1;
BA_ "SystemSignalLongSymbol" SG_ 570 VCSEC_BLESuccessfulConnEven_0001 "VCSEC_BLESuccessfulConnEventCount1";
BA_ "Confidence" SG_ 570 VCSEC_BLEMissedConnEventCount1 1;
BA_ "Confidence" SG_ 570 VCSEC_BLECRCErrorConnEventCount1 1;
BA_ "Confidence" SG_ 570 VCSEC_BLEOtherFailuresCount1 1;
BA_ "Confidence" SG_ 570 VCSEC_BLEUnsuccessfulConnEv_0001 1;
BA_ "GenSigSNA" SG_ 570 VCSEC_BLEUnsuccessfulConnEv_0001 "1023";
BA_ "SystemSignalLongSymbol" SG_ 570 VCSEC_BLEUnsuccessfulConnEv_0001 "VCSEC_BLEUnsuccessfulConnEventRate1";
BA_ "Confidence" SG_ 570 VCSEC_BLESuccessfulConnEven_0002 1;
BA_ "SystemSignalLongSymbol" SG_ 570 VCSEC_BLESuccessfulConnEven_0002 "VCSEC_BLESuccessfulConnEventCount2";
BA_ "Confidence" SG_ 570 VCSEC_BLEMissedConnEventCount2 1;
BA_ "Confidence" SG_ 570 VCSEC_BLECRCErrorConnEventCount2 1;
BA_ "Confidence" SG_ 570 VCSEC_BLEOtherFailuresCount2 1;
BA_ "Confidence" SG_ 570 VCSEC_BLEUnsuccessfulConnEv_0002 1;
BA_ "GenSigSNA" SG_ 570 VCSEC_BLEUnsuccessfulConnEv_0002 "1023";
BA_ "SystemSignalLongSymbol" SG_ 570 VCSEC_BLEUnsuccessfulConnEv_0002 "VCSEC_BLEUnsuccessfulConnEventRate2";
BA_ "Confidence" SG_ 570 VCSEC_BLESuccessfulConnEven_0003 1;
BA_ "SystemSignalLongSymbol" SG_ 570 VCSEC_BLESuccessfulConnEven_0003 "VCSEC_BLESuccessfulConnEventCount3";
BA_ "Confidence" SG_ 570 VCSEC_BLEMissedConnEventCount3 1;
BA_ "Confidence" SG_ 570 VCSEC_BLECRCErrorConnEventCount3 1;
BA_ "Confidence" SG_ 570 VCSEC_BLEOtherFailuresCount3 1;
BA_ "Confidence" SG_ 570 VCSEC_BLEUnsuccessfulConnEv_0003 1;
BA_ "GenSigSNA" SG_ 570 VCSEC_BLEUnsuccessfulConnEv_0003 "1023";
BA_ "SystemSignalLongSymbol" SG_ 570 VCSEC_BLEUnsuccessfulConnEv_0003 "VCSEC_BLEUnsuccessfulConnEventRate3";
BA_ "Confidence" SG_ 570 VCSEC_TPMSSensorTIAppCRC0 0;
BA_ "GenSigSNA" SG_ 570 VCSEC_TPMSSensorTIAppCRC0 "0";
BA_ "Confidence" SG_ 570 VCSEC_TPMSSensorMLXAppCRC0 0;
BA_ "GenSigSNA" SG_ 570 VCSEC_TPMSSensorMLXAppCRC0 "0";
BA_ "Confidence" SG_ 570 VCSEC_TPMSSensorTIAppCRC1 0;
BA_ "GenSigSNA" SG_ 570 VCSEC_TPMSSensorTIAppCRC1 "0";
BA_ "Confidence" SG_ 570 VCSEC_TPMSSensorMLXAppCRC1 0;
BA_ "GenSigSNA" SG_ 570 VCSEC_TPMSSensorMLXAppCRC1 "0";
BA_ "Confidence" SG_ 570 VCSEC_TPMSSensorTIAppCRC2 0;
BA_ "GenSigSNA" SG_ 570 VCSEC_TPMSSensorTIAppCRC2 "0";
BA_ "Confidence" SG_ 570 VCSEC_TPMSSensorMLXAppCRC2 0;
BA_ "GenSigSNA" SG_ 570 VCSEC_TPMSSensorMLXAppCRC2 "0";
BA_ "Confidence" SG_ 570 VCSEC_TPMSSensorTIAppCRC3 0;
BA_ "GenSigSNA" SG_ 570 VCSEC_TPMSSensorTIAppCRC3 "0";
BA_ "Confidence" SG_ 570 VCSEC_TPMSSensorMLXAppCRC3 0;
BA_ "GenSigSNA" SG_ 570 VCSEC_TPMSSensorMLXAppCRC3 "0";
BA_ "Confidence" SG_ 570 VCSEC_TPMStotalAwakeTime0 0;
BA_ "Confidence" SG_ 570 VCSEC_TPMSTrimAdjusted0 0;
BA_ "Confidence" SG_ 570 VCSEC_TPMSGenealogySensorState0 0;
BA_ "Confidence" SG_ 570 VCSEC_TPMSSensorType0 0;
BA_ "Confidence" SG_ 570 VCSEC_TPMStotalAwakeTime1 0;
BA_ "Confidence" SG_ 570 VCSEC_TPMSTrimAdjusted1 0;
BA_ "Confidence" SG_ 570 VCSEC_TPMSGenealogySensorState1 0;
BA_ "Confidence" SG_ 570 VCSEC_TPMSSensorType1 0;
BA_ "Confidence" SG_ 570 VCSEC_TPMStotalAwakeTime2 0;
BA_ "Confidence" SG_ 570 VCSEC_TPMSTrimAdjusted2 0;
BA_ "Confidence" SG_ 570 VCSEC_TPMSGenealogySensorState2 0;
BA_ "Confidence" SG_ 570 VCSEC_TPMSSensorType2 0;
BA_ "Confidence" SG_ 570 VCSEC_TPMStotalAwakeTime3 0;
BA_ "Confidence" SG_ 570 VCSEC_TPMSTrimAdjusted3 0;
BA_ "Confidence" SG_ 570 VCSEC_TPMSGenealogySensorState3 0;
BA_ "Confidence" SG_ 570 VCSEC_TPMSSensorType3 0;
BA_ "Confidence" SG_ 1067 VCSEC_UWBEndpointIndex 1;
BA_ "Confidence" SG_ 1067 VCSEC_UWBRearRightDistance0 1;
BA_ "GenSigSNA" SG_ 1067 VCSEC_UWBRearRightDistance0 "4095";
BA_ "Confidence" SG_ 1067 VCSEC_UWBRearRightDistance1 1;
BA_ "GenSigSNA" SG_ 1067 VCSEC_UWBRearRightDistance1 "4095";
BA_ "Confidence" SG_ 1067 VCSEC_UWBRearRightDistance2 1;
BA_ "GenSigSNA" SG_ 1067 VCSEC_UWBRearRightDistance2 "4095";
BA_ "Confidence" SG_ 1067 VCSEC_UWBLeftDistance2 1;
BA_ "GenSigSNA" SG_ 1067 VCSEC_UWBLeftDistance2 "4095";
BA_ "Confidence" SG_ 1067 VCSEC_UWBRightDistance2 0;
BA_ "GenSigSNA" SG_ 1067 VCSEC_UWBRightDistance2 "4095";
BA_ "Confidence" SG_ 1067 VCSEC_UWBRearDistance2 0;
BA_ "GenSigSNA" SG_ 1067 VCSEC_UWBRearDistance2 "4095";
BA_ "Confidence" SG_ 1067 VCSEC_UWBRearLeftDistance2 0;
BA_ "GenSigSNA" SG_ 1067 VCSEC_UWBRearLeftDistance2 "4095";
BA_ "Confidence" SG_ 1067 VCSEC_UWBCenterDistance2 0;
BA_ "GenSigSNA" SG_ 1067 VCSEC_UWBCenterDistance2 "4095";
BA_ "Confidence" SG_ 1067 VCSEC_UWBLeftDistance1 1;
BA_ "GenSigSNA" SG_ 1067 VCSEC_UWBLeftDistance1 "4095";
BA_ "Confidence" SG_ 1067 VCSEC_UWBRightDistance1 0;
BA_ "GenSigSNA" SG_ 1067 VCSEC_UWBRightDistance1 "4095";
BA_ "Confidence" SG_ 1067 VCSEC_UWBRearDistance1 0;
BA_ "GenSigSNA" SG_ 1067 VCSEC_UWBRearDistance1 "4095";
BA_ "Confidence" SG_ 1067 VCSEC_UWBRearLeftDistance1 0;
BA_ "GenSigSNA" SG_ 1067 VCSEC_UWBRearLeftDistance1 "4095";
BA_ "Confidence" SG_ 1067 VCSEC_UWBCenterDistance1 0;
BA_ "GenSigSNA" SG_ 1067 VCSEC_UWBCenterDistance1 "4095";
BA_ "Confidence" SG_ 1067 VCSEC_UWBLeftDistance0 1;
BA_ "GenSigSNA" SG_ 1067 VCSEC_UWBLeftDistance0 "4095";
BA_ "Confidence" SG_ 1067 VCSEC_UWBRightDistance0 0;
BA_ "GenSigSNA" SG_ 1067 VCSEC_UWBRightDistance0 "4095";
BA_ "Confidence" SG_ 1067 VCSEC_UWBRearDistance0 0;
BA_ "GenSigSNA" SG_ 1067 VCSEC_UWBRearDistance0 "4095";
BA_ "Confidence" SG_ 1067 VCSEC_UWBRearLeftDistance0 0;
BA_ "GenSigSNA" SG_ 1067 VCSEC_UWBRearLeftDistance0 "4095";
BA_ "Confidence" SG_ 1067 VCSEC_UWBCenterDistance0 0;
BA_ "GenSigSNA" SG_ 1067 VCSEC_UWBCenterDistance0 "4095";
BA_ "Confidence" SG_ 761 VCSEC_activeKeyDebug 0;
BA_ "Confidence" SG_ 761 VCSEC_bleChannelDisconnected 0;
BA_ "Confidence" SG_ 761 VCSEC_bleDisconnectionReason 0;
BA_ "Confidence" SG_ 761 VCSEC_bleConnetionAttemptWLEntry 0;
BA_ "Confidence" SG_ 761 VCSEC_AdditionalAuthInfoIndex 1;
BA_ "Confidence" SG_ 761 VCSEC_activeKeyReason 0;
BA_ "Confidence" SG_ 761 VCSEC_activeKeySHA1 0;
BA_ "Confidence" SG_ 761 VCSEC_algoUsedForSummonRange0 0;
BA_ "Confidence" SG_ 761 VCSEC_keyWithinSummonRange0 0;
BA_ "Confidence" SG_ 761 VCSEC_algoUsedForSummonRange1 0;
BA_ "Confidence" SG_ 761 VCSEC_keyWithinSummonRange1 0;
BA_ "Confidence" SG_ 761 VCSEC_algoUsedForSummonRange2 0;
BA_ "Confidence" SG_ 761 VCSEC_keyWithinSummonRange2 0;
BA_ "Confidence" SG_ 761 VCSEC_BLEDeviceWithinSummonRange 0;
BA_ "Confidence" SG_ 761 VCSEC_NFCAuthFromBPillarFormFact 1;
BA_ "SystemSignalLongSymbol" SG_ 761 VCSEC_NFCAuthFromBPillarFormFact "VCSEC_NFCAuthFromBPillarFormFactor";
BA_ "Confidence" SG_ 761 VCSEC_NFCAuthFromCenterConsoleFo 1;
BA_ "SystemSignalLongSymbol" SG_ 761 VCSEC_NFCAuthFromCenterConsoleFo "VCSEC_NFCAuthFromCenterConsoleFormFactor";
BA_ "Confidence" SG_ 1817 VCSEC_debug100msIndex 1;
BA_ "Confidence" SG_ 1817 VCSEC_walkAwayLockKeyState 0;
BA_ "Confidence" SG_ 1817 VCSEC_thresholdOffsetVersion 0;
BA_ "Confidence" SG_ 1817 VCSEC_walkAwayLockState 0;
BA_ "Confidence" SG_ 1817 VCSEC_rssi0WLEntry 0;
BA_ "Confidence" SG_ 1817 VCSEC_endpointLayout 0;
BA_ "Confidence" SG_ 1817 VCSEC_rssi1WLEntry 0;
BA_ "Confidence" SG_ 1817 VCSEC_rssi2WLEntry 0;
BA_ "Confidence" SG_ 1817 VCSEC_walkUpUnlockState 0;
BA_ "Confidence" SG_ 1817 VCSEC_algoHighThreshLeft 0;
BA_ "Confidence" SG_ 1817 VCSEC_algoHighThreshRight 0;
BA_ "Confidence" SG_ 1817 VCSEC_algoHighThreshCenter 0;
BA_ "Confidence" SG_ 1817 VCSEC_pollingReason 0;
BA_ "Confidence" SG_ 1817 VCSEC_numberOfPubKeysOnWhitelist 1;
BA_ "Confidence" SG_ 1817 VCSEC_thermalDetectState 1;
BA_ "Confidence" SG_ 1817 VCSEC_connection0BondingState 0;
BA_ "Confidence" SG_ 1817 VCSEC_connection1BondingState 0;
BA_ "Confidence" SG_ 1817 VCSEC_connection2BondingState 0;
BA_ "Confidence" SG_ 1817 VCSEC_connection0UWBAvailability 0;
BA_ "Confidence" SG_ 1817 VCSEC_connection1UWBAvailability 0;
BA_ "Confidence" SG_ 1817 VCSEC_connection2UWBAvailability 0;
BA_ "Confidence" SG_ 1817 VCSEC_NISessionStateCenter0 0;
BA_ "Confidence" SG_ 1817 VCSEC_NISessionStateLeft0 0;
BA_ "Confidence" SG_ 1817 VCSEC_NISessionStateRight0 0;
BA_ "Confidence" SG_ 1817 VCSEC_NISessionStateRearLeft0 0;
BA_ "Confidence" SG_ 1817 VCSEC_NISessionStateRearRight0 0;
BA_ "Confidence" SG_ 1817 VCSEC_NISessionStateRear0 0;
BA_ "Confidence" SG_ 1817 VCSEC_NISessionStateCenter1 0;
BA_ "Confidence" SG_ 1817 VCSEC_NISessionStateLeft1 0;
BA_ "Confidence" SG_ 1817 VCSEC_NISessionStateRight1 0;
BA_ "Confidence" SG_ 1817 VCSEC_NISessionStateRearLeft1 0;
BA_ "Confidence" SG_ 1817 VCSEC_NISessionStateRearRight1 0;
BA_ "Confidence" SG_ 1817 VCSEC_NISessionStateRear1 0;
BA_ "Confidence" SG_ 1817 VCSEC_NISessionStateCenter2 0;
BA_ "Confidence" SG_ 1817 VCSEC_NISessionStateLeft2 0;
BA_ "Confidence" SG_ 1817 VCSEC_NISessionStateRight2 0;
BA_ "Confidence" SG_ 1817 VCSEC_NISessionStateRearLeft2 0;
BA_ "Confidence" SG_ 1817 VCSEC_NISessionStateRearRight2 0;
BA_ "Confidence" SG_ 1817 VCSEC_NISessionStateRear2 0;
BA_ "Confidence" SG_ 1655 VC_lvbmsStatusHighIndex 1;
BA_ "Confidence" SG_ 1655 VC_LVBMS_packCurrent 0;
BA_ "GenSigSNA" SG_ 1655 VC_LVBMS_packCurrent "4194303";
BA_ "Confidence" SG_ 1655 VC_LVBMS_packVoltage 0;
BA_ "GenSigSNA" SG_ 1655 VC_LVBMS_packVoltage "65535";
BA_ "Confidence" SG_ 1655 VC_LVBMS_packTemperature 0;
BA_ "GenSigSNA" SG_ 1655 VC_LVBMS_packTemperature "511";
BA_ "Confidence" SG_ 1655 VC_LVBMS_MOSTemperature 0;
BA_ "GenSigSNA" SG_ 1655 VC_LVBMS_MOSTemperature "4095";
BA_ "Confidence" SG_ 1655 VC_LVBMS_sumCellVoltage 0;
BA_ "GenSigSNA" SG_ 1655 VC_LVBMS_sumCellVoltage "65535";
BA_ "Confidence" SG_ 1655 VC_LVBMS_maxBrickVoltage 0;
BA_ "GenSigSNA" SG_ 1655 VC_LVBMS_maxBrickVoltage "8191";
BA_ "Confidence" SG_ 1655 VC_LVBMS_maxBrickVoltageIndex 0;
BA_ "GenSigSNA" SG_ 1655 VC_LVBMS_maxBrickVoltageIndex "255";
BA_ "Confidence" SG_ 1655 VC_LVBMS_avgBrickVoltage 1;
BA_ "GenSigSNA" SG_ 1655 VC_LVBMS_avgBrickVoltage "8191";
BA_ "Confidence" SG_ 1655 VC_LVBMS_minBrickVoltage 1;
BA_ "GenSigSNA" SG_ 1655 VC_LVBMS_minBrickVoltage "8191";
BA_ "Confidence" SG_ 1655 VC_LVBMS_minBrickVoltageIndex 1;
BA_ "GenSigSNA" SG_ 1655 VC_LVBMS_minBrickVoltageIndex "255";
BA_ "Confidence" SG_ 1655 VC_LVBMS_voltageTarget 0;
BA_ "GenSigSNA" SG_ 1655 VC_LVBMS_voltageTarget "65535";
BA_ "Confidence" SG_ 1655 VC_LVBMS_currentTarget 1;
BA_ "GenSigSNA" SG_ 1655 VC_LVBMS_currentTarget "131071";
BA_ "Confidence" SG_ 1655 VC_LVBMS_maxAllowedChargeCurrent 1;
BA_ "GenSigSNA" SG_ 1655 VC_LVBMS_maxAllowedChargeCurrent "8191";
BA_ "Confidence" SG_ 1655 VC_LVBMS_maxAllowedDischargeCurr 1;
BA_ "GenSigSNA" SG_ 1655 VC_LVBMS_maxAllowedDischargeCurr "8191";
BA_ "SystemSignalLongSymbol" SG_ 1655 VC_LVBMS_maxAllowedDischargeCurr "VC_LVBMS_maxAllowedDischargeCurrent";
BA_ "Confidence" SG_ 1655 VC_LVBMS_MOSCommand 0;
BA_ "Confidence" SG_ 1655 VC_LVBMS_ClearErrorCntrCommand 0;
BA_ "Confidence" SG_ 1655 VC_LVBMS_ClearHistoricFaultComma 0;
BA_ "SystemSignalLongSymbol" SG_ 1655 VC_LVBMS_ClearHistoricFaultComma "VC_LVBMS_ClearHistoricFaultCommand";
BA_ "Confidence" SG_ 1655 VC_LVBMS_ResetLVBMSCommand 0;
BA_ "Confidence" SG_ 1655 VC_LVBMS_EnterHibernationCommand 0;
BA_ "Confidence" SG_ 1655 VC_LVBMS_ECPAState 0;
BA_ "GenSigSNA" SG_ 1655 VC_LVBMS_ECPAState "3";
BA_ "Confidence" SG_ 1655 VC_LVBMS_MOSState 0;
BA_ "GenSigSNA" SG_ 1655 VC_LVBMS_MOSState "3";
BA_ "Confidence" SG_ 1655 VC_LVBMS_VehicleState 0;
BA_ "Confidence" SG_ 1655 VC_LVBMS_LINWakeDisabled 0;
BA_ "Confidence" SG_ 1655 VC_LVBMS_chargeType 0;
BA_ "GenSigSNA" SG_ 1655 VC_LVBMS_chargeType "4";
BA_ "Confidence" SG_ 1655 VC_LVBMS_cellAndArcProtEnabled 0;
BA_ "Confidence" SG_ 1655 VC_totalLVLoadCurrent 0;
BA_ "Confidence" SG_ 1655 VC_LVPackChargeCurrentLimit 0;
BA_ "Confidence" SG_ 1655 VC_LVPackCurrent 0;
BA_ "Confidence" SG_ 1655 VC_LVBMS_estimatedPackOcv 0;
BA_ "Confidence" SG_ 1816 VC_lvbmsStatusLowIndex 1;
BA_ "Confidence" SG_ 1816 VC_LVBMS_SOC 1;
BA_ "GenSigSNA" SG_ 1816 VC_LVBMS_SOC "127";
BA_ "Confidence" SG_ 1816 VC_LVBMS_SOE 0;
BA_ "GenSigSNA" SG_ 1816 VC_LVBMS_SOE "127";
BA_ "Confidence" SG_ 1816 VC_LVBMS_SOH 0;
BA_ "GenSigSNA" SG_ 1816 VC_LVBMS_SOH "127";
BA_ "Confidence" SG_ 1816 VC_LVBMS_SOP 1;
BA_ "GenSigSNA" SG_ 1816 VC_LVBMS_SOP "16777215";
BA_ "Confidence" SG_ 1816 VC_LVBMS_AvgSleepCurrent 0;
BA_ "GenSigSNA" SG_ 1816 VC_LVBMS_AvgSleepCurrent "65535";
BA_ "Confidence" SG_ 1816 VC_LVBMS_TimeSlept 0;
BA_ "GenSigSNA" SG_ 1816 VC_LVBMS_TimeSlept "16777215";
BA_ "Confidence" SG_ 1816 VC_LVBMS_AhCharged 0;
BA_ "GenSigSNA" SG_ 1816 VC_LVBMS_AhCharged "4294967295";
BA_ "Confidence" SG_ 1816 VC_LVBMS_MinSleepCurrent 0;
BA_ "GenSigSNA" SG_ 1816 VC_LVBMS_MinSleepCurrent "65535";
BA_ "Confidence" SG_ 1816 VC_LVBMS_AhDischarged 0;
BA_ "GenSigSNA" SG_ 1816 VC_LVBMS_AhDischarged "4294967295";
BA_ "Confidence" SG_ 1816 VC_LVBMS_MaxSleepCurrent 0;
BA_ "GenSigSNA" SG_ 1816 VC_LVBMS_MaxSleepCurrent "65535";
BA_ "Confidence" SG_ 1816 VC_LVBMS_sumCellVoltageFiltered 0;
BA_ "GenSigSNA" SG_ 1816 VC_LVBMS_sumCellVoltageFiltered "65535";
BA_ "Confidence" SG_ 1816 VC_LVBMS_maxCellSOC 1;
BA_ "GenSigSNA" SG_ 1816 VC_LVBMS_maxCellSOC "127";
BA_ "Confidence" SG_ 1816 VC_LVBMS_minCellSOC 1;
BA_ "GenSigSNA" SG_ 1816 VC_LVBMS_minCellSOC "127";
BA_ "Confidence" SG_ 1816 VC_LVBMS_staticSOCCorrection 1;
BA_ "Confidence" SG_ 1816 VC_LVBMS_dynamicSOCCorrection 1;
BA_ "Confidence" SG_ 1816 VC_LVBMS_usableEnergyAvailable 1;
BA_ "GenSigSNA" SG_ 1816 VC_LVBMS_usableEnergyAvailable "4095";
BA_ "Confidence" SG_ 1816 VC_LVBMS_PackOVLevel2 1;
BA_ "Confidence" SG_ 1816 VC_LVBMS_DischrgOCLevel2 1;
BA_ "Confidence" SG_ 1816 VC_LVBMS_ChrgOCLevel2 1;
BA_ "Confidence" SG_ 1816 VC_LVBMS_KBValueLostFault 1;
BA_ "Confidence" SG_ 1816 VC_LVBMS_BalanceCircuitFault 1;
BA_ "Confidence" SG_ 1816 VC_LVBMS_MOSStateFault 1;
BA_ "Confidence" SG_ 1816 VC_LVBMS_DeepDischargeFlag 1;
BA_ "Confidence" SG_ 1816 VC_LVBMS_SamplingError 1;
BA_ "Confidence" SG_ 1816 VC_LVBMS_MosfetStuckCloseError 1;
BA_ "Confidence" SG_ 1816 VC_LVBMS_MosfetStuckOpenError 1;
BA_ "Confidence" SG_ 1089 VC_pcsInterfaceMuxIndex 1;
BA_ "Confidence" SG_ 1089 VC_pcsInterfaceCounter 0;
BA_ "Confidence" SG_ 1089 VC_pcsInterfaceChecksum 0;
BA_ "Confidence" SG_ 1089 VC_pcsLVVoltageTarget 0;
BA_ "Confidence" SG_ 1089 VC_pcsLVMinVoltageLimit 0;
BA_ "Confidence" SG_ 1089 VC_pcsLVMaxVoltageLimit 0;
BA_ "Confidence" SG_ 1089 VC_goodForPCSPowerCycle 0;
BA_ "Confidence" SG_ 1089 VC_LVBatteryCannotSupportVehicle 0;
BA_ "Confidence" SG_ 1089 VC_pcsResistanceFiltered 0;
BA_ "GenSigSNA" SG_ 1089 VC_pcsResistanceFiltered "65535";
BA_ "Confidence" SG_ 1089 VC_pcsLVMaxDchrgCurrentLimit 0;
BA_ "Confidence" SG_ 1089 VC_defaultPcsLVVoltageTarget 0;
BA_ "Confidence" SG_ 1089 VC_lvHwProtSelfTestActive 0;
VAL_ 691 VCRIGHT_logging1HzIndex 17 "END" 16 "HVAC_MISCELLANEOUS_4" 15 "HVAC_MISCELLANEOUS_3" 14 "STEERING_WHEEL_HEAT" 13 "HVAC_COMFORT_SOLAR_3" 12 "HVAC_COMFORT_SOLAR_2" 11 "HSD_CURRENTS_2" 10 "HSD_CURRENTS_1" 9 "HVAC_MISCELLANEOUS_2" 8 "HVAC_MISCELLANEOUS_1" 7 "HVAC_TEMP_SENSORS_AND_ESTIMATES_3" 6 "HVAC_ACTUATOR_VOLTAGES" 5 "HEATER_AND_DUCT_TARGETS" 4 "HVAC_COMFORT_SOLAR" 3 "HVAC_STATUS_AIRFLOW" 2 "HVAC_HUMIDITY_HEATER_TEMP" 1 "HVAC_TEMP_SENSORS_AND_ESTIMATES_2" 0 "HVAC_TEMP_SENSORS_AND_ESTIMATES_1" ;
VAL_ 691 VCRIGHT_tempIncarCabinProbe 255 "SNA" ;
VAL_ 691 VCRIGHT_tempIncarCabinDeep 255 "SNA" ;
VAL_ 691 VCRIGHT_cabinTempInteriorL2 255 "SNA" ;
VAL_ 691 VCRIGHT_tempIncarCabinMid 250 "SNA" ;
VAL_ 691 VCRIGHT_cabinTempInteriorSunnyL2 255 "SNA" ;
VAL_ 691 VCRIGHT_cabinTempInteriorL3 255 "SNA" ;
VAL_ 691 VCRIGHT_cabinTempInteriorSunnyL3 255 "SNA" ;
VAL_ 691 VCRIGHT_cabinTempGlassRoof 255 "SNA" ;
VAL_ 691 VCRIGHT_cabinTempWindshield 255 "SNA" ;
VAL_ 691 VCRIGHT_cabinTempInterior 255 "SNA" ;
VAL_ 691 VCRIGHT_cabinTempInteriorSunny 255 "SNA" ;
VAL_ 691 VCRIGHT_cabinTempSideGlassLeft 255 "SNA" ;
VAL_ 691 VCRIGHT_cabinTempSideGlassRight 255 "SNA" ;
VAL_ 691 VCRIGHT_cabinTempBreathLevel 255 "SNA" ;
VAL_ 691 VCRIGHT_hvacAutoTransitionReason 23 "END" 22 "VOC_PURGE" 21 "RETURN_FROM_DEFOG_OVERRIDE" 20 "HVAC_AIR_HUMID" 19 "BIODEFENSE" 18 "DUCT_TARGETS_INVALID" 17 "HVAC_OFF" 16 "EVAP_OIL_PURGE" 15 "EVAP_DRYING" 14 "CABIN_PURGE" 13 "SET_TEMP_HI" 12 "SET_TEMP_LO" 11 "DEFOG_OVERRIDE" 10 "BI_LEVEL_LANDING" 9 "DUCTS_COLD" 8 "TEMP_TARGET_LOW" 7 "OCCUPANT_CONVECTION_REQUIREMENT" 6 "EXCESS_OCCUPANT_CONVECTION" 5 "TEMP_TARGET_ABOVE_THRESHOLD" 4 "TEMP_TARGET_BELOW_THRESHOLD" 3 "HUMIDITY_LOW" 2 "HUMIDITY_MODERATE" 1 "HUMIDITY_HIGH" 0 "NONE" ;
VAL_ 691 VCRIGHT_hvacLHBleedOperationMode 1 "HVACACTUATOR_OPERATION_MODE_CALIBRATION" 0 "HVACACTUATOR_OPERATION_MODE_NORMAL" ;
VAL_ 691 VCRIGHT_hvacRHBleedOperationMode 1 "HVACACTUATOR_OPERATION_MODE_CALIBRATION" 0 "HVACACTUATOR_OPERATION_MODE_NORMAL" ;
VAL_ 691 VCRIGHT_hvacLHVaneOperationMode 1 "HVACACTUATOR_OPERATION_MODE_CALIBRATION" 0 "HVACACTUATOR_OPERATION_MODE_NORMAL" ;
VAL_ 691 VCRIGHT_hvacRHVaneOperationMode 1 "HVACACTUATOR_OPERATION_MODE_CALIBRATION" 0 "HVACACTUATOR_OPERATION_MODE_NORMAL" ;
VAL_ 691 VCRIGHT_hvacUpperModeOpMode 1 "HVACACTUATOR_OPERATION_MODE_CALIBRATION" 0 "HVACACTUATOR_OPERATION_MODE_NORMAL" ;
VAL_ 691 VCRIGHT_hvacLowerModeOpMode 1 "HVACACTUATOR_OPERATION_MODE_CALIBRATION" 0 "HVACACTUATOR_OPERATION_MODE_NORMAL" ;
VAL_ 691 VCRIGHT_hvacIntakeOperationMode 1 "HVACACTUATOR_OPERATION_MODE_CALIBRATION" 0 "HVACACTUATOR_OPERATION_MODE_NORMAL" ;
VAL_ 691 VCRIGHT_isProbeFeedbackApplied 4 "NEGATIVEHIGH" 3 "POSITIVEHIGH" 2 "NEGATIVE" 1 "POSITIVE" 0 "OFF" ;
VAL_ 691 VCRIGHT_convectionTargetLeft 511 "SNA" ;
VAL_ 691 VCRIGHT_convectionTargetRight 511 "SNA" ;
VAL_ 691 VCRIGHT_convectionDeliveredLeft 511 "SNA" ;
VAL_ 691 VCRIGHT_convectionDeliveredRight 511 "SNA" ;
VAL_ 691 VCRIGHT_solarLoadRightOccupant 127 "SNA" ;
VAL_ 691 VCRIGHT_solarLoadLeftOccupant 127 "SNA" ;
VAL_ 691 VCRIGHT_solarLoadFromThsTemp 255 "SNA" ;
VAL_ 691 VCRIGHT_cabinTempWshldDefog 255 "SNA" ;
VAL_ 691 VCRIGHT_cabinTempWshldDefogTop 255 "SNA" ;
VAL_ 691 VCRIGHT_cabinTempBreathLevelFHea 255 "SNA" ;
VAL_ 691 VCRIGHT_cabinTempBreathLevelFCoo 255 "SNA" ;
VAL_ 691 VCRIGHT_cabinTempBreathLeve_0002 255 "SNA" ;
VAL_ 691 VCRIGHT_cabinTempBreathLevelF5mi 255 "SNA" ;
VAL_ 691 VCRIGHT_cabinTempBreathLeve_0001 255 "SNA" ;
VAL_ 691 VCRIGHT_cabinTempBreathLevelF10m 255 "SNA" ;
VAL_ 691 VCRIGHT_cabinTempInteriorFHeatin 255 "SNA" ;
VAL_ 691 VCRIGHT_filterLifeBlowerTorque 1023 "SNA" ;
VAL_ 691 VCRIGHT_solarLoadOnVehFiltered 255 "SNA" ;
VAL_ 691 VCRIGHT_cabinTempProbeEstimate 255 "SNA" ;
VAL_ 691 VCRIGHT_cabinTempThs 255 "SNA" ;
VAL_ 691 VCRIGHT_cabinTempThsBracket 255 "SNA" ;
VAL_ 691 VCRIGHT_CO2ppm 1023 "SNA" ;
VAL_ 691 VCRIGHT_reverseFogLightsCurrent 15 "SNA" ;
VAL_ 691 VCRIGHT_sideMirrorHeaterCurrent 31 "SNA" ;
VAL_ 691 VCRIGHT_trunkInteriorLEDCurrent 15 "SNA" ;
VAL_ 691 VCRIGHT_mapPocketLEDsCurrent 15 "SNA" ;
VAL_ 691 VCRIGHT_miscEFuseCurrent 31 "SNA" ;
VAL_ 691 VCRIGHT_miscInteriorLightsCurren 7 "SNA" ;
VAL_ 691 VCRIGHT_frontPuddleLEDCurrent 7 "SNA" ;
VAL_ 691 VCRIGHT_rearPuddleLEDCurrent 7 "SNA" ;
VAL_ 691 VCRIGHT_liftgateShutfaceLEDCurre 7 "SNA" ;
VAL_ 691 VCRIGHT_3rSeatTOSCurrent 15 "SNA" ;
VAL_ 691 VCRIGHT_vbatFusedCurrent 15 "SNA" ;
VAL_ 691 VCRIGHT_cabinTempGlassGridHeater 255 "SNA" ;
VAL_ 691 VCRIGHT_hvacAirflowReasonRight 21 "NONE" 20 "ODOR_ROUTINE" 19 "DRIVERLESS_SELF_TEST" 18 "VOC_PURGE" 17 "STRATIFICATION_TOP_PAD_AREA" 16 "HOT_DUCT_LOCKOUT" 15 "COLD_DUCT_LOCKOUT" 14 "BIOWEAPON_DEFENSE" 13 "EVAP_OIL_PURGE" 12 "EVAP_DRYING" 11 "SCREEN_PROTECTION" 10 "CABIN_OVERHEAT_PROTECT" 9 "CABIN_PURGE" 8 "OUTLET_TEMP_LIMIT" 7 "OCCUPANT_CONVECTION_REQUIREMENT" 6 "STRATIFICATION_INTERIOR_SURFACES" 5 "STRATIFICATION_GLASS_ROOF" 4 "MINIMUM_AUTO_AIRFLOW" 3 "CABIN_TEMPERATURE_CONTROL" 2 "UI_SHORTCUT" 1 "MANUAL_FAN_SPEED" 0 "HVAC_OFF" ;
VAL_ 691 VCRIGHT_hvacAirflowReasonLeft 21 "NONE" 20 "ODOR_ROUTINE" 19 "DRIVERLESS_SELF_TEST" 18 "VOC_PURGE" 17 "STRATIFICATION_TOP_PAD_AREA" 16 "HOT_DUCT_LOCKOUT" 15 "COLD_DUCT_LOCKOUT" 14 "BIOWEAPON_DEFENSE" 13 "EVAP_OIL_PURGE" 12 "EVAP_DRYING" 11 "SCREEN_PROTECTION" 10 "CABIN_OVERHEAT_PROTECT" 9 "CABIN_PURGE" 8 "OUTLET_TEMP_LIMIT" 7 "OCCUPANT_CONVECTION_REQUIREMENT" 6 "STRATIFICATION_INTERIOR_SURFACES" 5 "STRATIFICATION_GLASS_ROOF" 4 "MINIMUM_AUTO_AIRFLOW" 3 "CABIN_TEMPERATURE_CONTROL" 2 "UI_SHORTCUT" 1 "MANUAL_FAN_SPEED" 0 "HVAC_OFF" ;
VAL_ 691 VCRIGHT_solarLoadLeftOccupantFil 127 "SNA" ;
VAL_ 691 VCRIGHT_solarLoadRightOccupantFi 127 "SNA" ;
VAL_ 691 VCRIGHT_airflowReasonAutoInManua 21 "NONE" 20 "ODOR_ROUTINE" 19 "DRIVERLESS_SELF_TEST" 18 "VOC_PURGE" 17 "STRATIFICATION_TOP_PAD_AREA" 16 "HOT_DUCT_LOCKOUT" 15 "COLD_DUCT_LOCKOUT" 14 "BIOWEAPON_DEFENSE" 13 "EVAP_OIL_PURGE" 12 "EVAP_DRYING" 11 "SCREEN_PROTECTION" 10 "CABIN_OVERHEAT_PROTECT" 9 "CABIN_PURGE" 8 "OUTLET_TEMP_LIMIT" 7 "OCCUPANT_CONVECTION_REQUIREMENT" 6 "STRATIFICATION_INTERIOR_SURFACES" 5 "STRATIFICATION_GLASS_ROOF" 4 "MINIMUM_AUTO_AIRFLOW" 3 "CABIN_TEMPERATURE_CONTROL" 2 "UI_SHORTCUT" 1 "MANUAL_FAN_SPEED" 0 "HVAC_OFF" ;
VAL_ 691 VCRIGHT_airflowReasonAutoIn_0001 21 "NONE" 20 "ODOR_ROUTINE" 19 "DRIVERLESS_SELF_TEST" 18 "VOC_PURGE" 17 "STRATIFICATION_TOP_PAD_AREA" 16 "HOT_DUCT_LOCKOUT" 15 "COLD_DUCT_LOCKOUT" 14 "BIOWEAPON_DEFENSE" 13 "EVAP_OIL_PURGE" 12 "EVAP_DRYING" 11 "SCREEN_PROTECTION" 10 "CABIN_OVERHEAT_PROTECT" 9 "CABIN_PURGE" 8 "OUTLET_TEMP_LIMIT" 7 "OCCUPANT_CONVECTION_REQUIREMENT" 6 "STRATIFICATION_INTERIOR_SURFACES" 5 "STRATIFICATION_GLASS_ROOF" 4 "MINIMUM_AUTO_AIRFLOW" 3 "CABIN_TEMPERATURE_CONTROL" 2 "UI_SHORTCUT" 1 "MANUAL_FAN_SPEED" 0 "HVAC_OFF" ;
VAL_ 691 VCRIGHT_airflowReasonAutoIn_0002 21 "NONE" 20 "ODOR_ROUTINE" 19 "DRIVERLESS_SELF_TEST" 18 "VOC_PURGE" 17 "STRATIFICATION_TOP_PAD_AREA" 16 "HOT_DUCT_LOCKOUT" 15 "COLD_DUCT_LOCKOUT" 14 "BIOWEAPON_DEFENSE" 13 "EVAP_OIL_PURGE" 12 "EVAP_DRYING" 11 "SCREEN_PROTECTION" 10 "CABIN_OVERHEAT_PROTECT" 9 "CABIN_PURGE" 8 "OUTLET_TEMP_LIMIT" 7 "OCCUPANT_CONVECTION_REQUIREMENT" 6 "STRATIFICATION_INTERIOR_SURFACES" 5 "STRATIFICATION_GLASS_ROOF" 4 "MINIMUM_AUTO_AIRFLOW" 3 "CABIN_TEMPERATURE_CONTROL" 2 "UI_SHORTCUT" 1 "MANUAL_FAN_SPEED" 0 "HVAC_OFF" ;
VAL_ 691 VCRIGHT_cabinTempInteriorFCoolin 255 "SNA" ;
VAL_ 691 VCRIGHT_averageDuctTempFHeating 255 "SNA" ;
VAL_ 691 VCRIGHT_averageDuctTempFCooling 255 "SNA" ;
VAL_ 691 VCRIGHT_steeringWheelSurfaceTemp 1023 "SNA" ;
VAL_ 691 VCRIGHT_steeringWheelSurfac_0001 1023 "SNA" ;
VAL_ 691 VCRIGHT_timeToComfortHeating 63 "HVAC_OFF" 62 "UNATTAINABLE" 0 "IN_COMFORT_BAND" ;
VAL_ 691 VCRIGHT_timeToComfortCooling 63 "HVAC_OFF" 62 "UNATTAINABLE" 0 "IN_COMFORT_BAND" ;
VAL_ 691 VCRIGHT_cabinWaterMassRaw 255 "SNA" ;
VAL_ 691 VCRIGHT_VOCPurgeState 5 "PURGING_AND_DRYING" 4 "WAITING" 3 "PURGING" 2 "IDLE" 1 "INACTIVE" 0 "INIT" ;
VAL_ 691 VCRIGHT_cameraFoggingMonitorStat 6 "PRE_RUN_PURGE" 5 "IDLE" 4 "INACTIVE" 3 "RUNNING" 2 "WAKEUP" 1 "MONITORING" 0 "INIT" ;
VAL_ 691 VCRIGHT_hvacIntakeReason 26 "INTAKE_REASON_ODOR_ROUTINE" 25 "INTAKE_REASON_HVAC_OFF_IN_MOTION" 24 "INTAKE_REASON_LIFTGATE_CLOSING" 23 "INTAKE_REASON_DRIVERLESS_SELF_TEST" 22 "INTAKE_REASON_VOC_PURGE" 21 "INTAKE_REASON_STEAMING" 20 "INTAKE_REASON_PULLDOWN_IN_FRESH" 19 "INTAKE_REASON_RECIRC_NVH" 18 "INTAKE_REASON_CO2_PURGE" 17 "INTAKE_REASON_HVAC_OFF" 16 "INTAKE_REASON_PARK_POSITION" 15 "INTAKE_REASON_EVAP_DRYING" 14 "INTAKE_REASON_OIL_PURGE" 13 "INTAKE_REASON_CABIN_PURGE" 12 "INTAKE_REASON_COP" 11 "INTAKE_REASON_ENHANCED_FILTERATION" 10 "INTAKE_REASON_CHARGE_PORT_THAW" 9 "INTAKE_REASON_PRECON_OVERRIDE" 8 "INTAKE_REASON_HUMIDITY" 7 "INTAKE_REASON_BIO_WEAPON_STEADY" 6 "INTAKE_REASON_BIO_WEAPON_INIT" 5 "INTAKE_REASON_TEMPERATURE_CONTROL" 4 "INTAKE_REASON_MANUAL_RECIRC" 3 "INTAKE_REASON_MANUAL_FRESH" 2 "INTAKE_REASON_CAR_WASH" 1 "INTAKE_REASON_UDS" 0 "INTAKE_REASON_NONE" ;
VAL_ 691 VCRIGHT_solarAzimuthCarRef -1023 "SNA" ;
VAL_ 691 VCRIGHT_hvacLimpModeStatus 4 "LIMP_MODE_FAULTED" 3 "LIMP_MODE_ACTIVE" 2 "LIMP_MODE_READY" 1 "LIMP_MODE_WAITING_FOR_SENSORS" 0 "LIMP_MODE_NOT_NEEDED" ;
VAL_ 1862 VCRIGHT_frontOccupancyStatus 7 "SEAT_OCCUPANCY_SNA" 3 "SEAT_NOT_CONFIGURED" 2 "SEAT_OCCUPANCY_FAULTED" 1 "SEAT_OCCUPIED" 0 "SEAT_UNOCCUPIED" ;
VAL_ 1862 VCRIGHT_frontBuckleStatus 3 "SEAT_BELT_BUCKLE_NOT_CONFIGURED" 2 "SEAT_BELT_BUCKLE_STATUS_FAULTED" 1 "SEAT_BELT_BUCKLE_STATUS_LATCHED" 0 "SEAT_BELT_BUCKLE_STATUS_UNLATCHED" ;
VAL_ 1862 VCRIGHT_rearCenterBuckleStatus 3 "SEAT_BELT_BUCKLE_NOT_CONFIGURED" 2 "SEAT_BELT_BUCKLE_STATUS_FAULTED" 1 "SEAT_BELT_BUCKLE_STATUS_LATCHED" 0 "SEAT_BELT_BUCKLE_STATUS_UNLATCHED" ;
VAL_ 1862 VCRIGHT_rearRightBuckleStatus 3 "SEAT_BELT_BUCKLE_NOT_CONFIGURED" 2 "SEAT_BELT_BUCKLE_STATUS_FAULTED" 1 "SEAT_BELT_BUCKLE_STATUS_LATCHED" 0 "SEAT_BELT_BUCKLE_STATUS_UNLATCHED" ;
VAL_ 1862 VCRIGHT_rearRightOccupancyStatus 3 "SEAT_NOT_CONFIGURED" 2 "SEAT_OCCUPANCY_FAULTED" 1 "SEAT_OCCUPIED" 0 "SEAT_UNOCCUPIED" ;
VAL_ 1862 VCRIGHT_3RowLeftBuckleStatus 3 "SEAT_BELT_BUCKLE_NOT_CONFIGURED" 2 "SEAT_BELT_BUCKLE_STATUS_FAULTED" 1 "SEAT_BELT_BUCKLE_STATUS_LATCHED" 0 "SEAT_BELT_BUCKLE_STATUS_UNLATCHED" ;
VAL_ 1862 VCRIGHT_3RowRightBuckleStatus 3 "SEAT_BELT_BUCKLE_NOT_CONFIGURED" 2 "SEAT_BELT_BUCKLE_STATUS_FAULTED" 1 "SEAT_BELT_BUCKLE_STATUS_LATCHED" 0 "SEAT_BELT_BUCKLE_STATUS_UNLATCHED" ;
VAL_ 1862 VCRIGHT_3RowLeftOccupancyStatus 3 "SEAT_NOT_CONFIGURED" 2 "SEAT_OCCUPANCY_FAULTED" 1 "SEAT_OCCUPIED" 0 "SEAT_UNOCCUPIED" ;
VAL_ 1862 VCRIGHT_3RowRightOccupancyStatus 3 "SEAT_NOT_CONFIGURED" 2 "SEAT_OCCUPANCY_FAULTED" 1 "SEAT_OCCUPIED" 0 "SEAT_UNOCCUPIED" ;
VAL_ 1862 VCRIGHT_seatTrackPosition 7 "SEAT_TRACK_POSITION_SNA" 3 "SEAT_TRACK_POSITION_FAULTED" 2 "SEAT_TRACK_POSITION_NOT_CONFIGURED" 1 "SEAT_TRACK_POSITION_REARWARD" 0 "SEAT_TRACK_POSITION_FORWARD" ;
VAL_ 1862 VCRIGHT_occupantClassification 7 "SEAT_OCCUPANT_CLASSIFICATON_SNA" 6 "SEAT_OCCUPANT_CLASSIFICATON_OUT_OF_POSITION" 5 "SEAT_OCCUPANT_CLASSIFICATON_NOT_CONFIGURED" 4 "SEAT_OCCUPANT_CLASSIFICATON_INIT" 3 "SEAT_OCCUPANT_CLASSIFICATON_LARGE" 2 "SEAT_OCCUPANT_CLASSIFICATON_SMALL" 1 "SEAT_OCCUPANT_CLASSIFICATON_INHIBIT" 0 "SEAT_OCCUPANT_CLASSIFICATON_EMPTY" ;
VAL_ 1862 VCRIGHT_occupantClassificationQF 1 "SEAT_OCCUPANT_CLASSIFICATON_NOT_FAULTED" 0 "SEAT_OCCUPANT_CLASSIFICATON_FAULTED" ;
VAL_ 1862 VCRIGHT_classificationEnabled 1 "VCRIGHT_CLASSIFICATION_SOURCE" 0 "OCS1P_CLASSIFICATION_SOURCE" ;
VAL_ 1862 VCRIGHT_classificationEnabledQF 1 "CLASSIFICATION_ENABLED_NOT_FAULTED" 0 "CLASSIFICATION_ENABLED_FAULTED" ;
VAL_ 1251 VCRIGHT_seatStatusIndex 7 "RELATIVE_POSITION" 6 "OFFSETS" 5 "POSITION" 4 "LUMBAR" 3 "TILT" 2 "LIFT" 1 "BACK" 0 "TRACK" ;
VAL_ 1251 VCRIGHT_frontSeatTrackState 5 "SEAT_STATE_UNDEFINED" 4 "SEAT_STATE_CALIBRATING" 3 "SEAT_STATE_RECALLING" 2 "SEAT_STATE_MOVING_DOWN" 1 "SEAT_STATE_MOVING_UP" 0 "SEAT_STATE_STOPPED" ;
VAL_ 1251 VCRIGHT_frontSeatTrackBridgeSt 3 "IO_BRIDGE_STATE_COAST" 2 "IO_BRIDGE_STATE_BRAKE" 1 "IO_BRIDGE_STATE_ENABLED" 0 "IO_BRIDGE_STATE_DISABLED" ;
VAL_ 1251 VCRIGHT_frontSeatBackState 5 "SEAT_STATE_UNDEFINED" 4 "SEAT_STATE_CALIBRATING" 3 "SEAT_STATE_RECALLING" 2 "SEAT_STATE_MOVING_DOWN" 1 "SEAT_STATE_MOVING_UP" 0 "SEAT_STATE_STOPPED" ;
VAL_ 1251 VCRIGHT_frontSeatBackBridgeSt 3 "IO_BRIDGE_STATE_COAST" 2 "IO_BRIDGE_STATE_BRAKE" 1 "IO_BRIDGE_STATE_ENABLED" 0 "IO_BRIDGE_STATE_DISABLED" ;
VAL_ 1251 VCRIGHT_frontSeatLiftState 5 "SEAT_STATE_UNDEFINED" 4 "SEAT_STATE_CALIBRATING" 3 "SEAT_STATE_RECALLING" 2 "SEAT_STATE_MOVING_DOWN" 1 "SEAT_STATE_MOVING_UP" 0 "SEAT_STATE_STOPPED" ;
VAL_ 1251 VCRIGHT_frontSeatLiftBridgeSt 3 "IO_BRIDGE_STATE_COAST" 2 "IO_BRIDGE_STATE_BRAKE" 1 "IO_BRIDGE_STATE_ENABLED" 0 "IO_BRIDGE_STATE_DISABLED" ;
VAL_ 1251 VCRIGHT_frontSeatTiltState 5 "SEAT_STATE_UNDEFINED" 4 "SEAT_STATE_CALIBRATING" 3 "SEAT_STATE_RECALLING" 2 "SEAT_STATE_MOVING_DOWN" 1 "SEAT_STATE_MOVING_UP" 0 "SEAT_STATE_STOPPED" ;
VAL_ 1251 VCRIGHT_frontSeatTiltBridgeSt 3 "IO_BRIDGE_STATE_COAST" 2 "IO_BRIDGE_STATE_BRAKE" 1 "IO_BRIDGE_STATE_ENABLED" 0 "IO_BRIDGE_STATE_DISABLED" ;
VAL_ 1251 VCRIGHT_lumbarAState 5 "SEAT_STATE_UNDEFINED" 4 "SEAT_STATE_CALIBRATING" 3 "SEAT_STATE_RECALLING" 2 "SEAT_STATE_MOVING_DOWN" 1 "SEAT_STATE_MOVING_UP" 0 "SEAT_STATE_STOPPED" ;
VAL_ 1251 VCRIGHT_lumbarBState 5 "SEAT_STATE_UNDEFINED" 4 "SEAT_STATE_CALIBRATING" 3 "SEAT_STATE_RECALLING" 2 "SEAT_STATE_MOVING_DOWN" 1 "SEAT_STATE_MOVING_UP" 0 "SEAT_STATE_STOPPED" ;
VAL_ 739 VCRIGHT_seatStatus2Index 12 "SEAT_2ROW_ADJUSTABLE_FOLD_FLAT_2" 11 "SEAT_2ROW_ADJUSTABLE_FOLD_FLAT" 10 "OCS_IEE" 9 "SEAT_2ROW_EASY_ENTRY" 8 "SEAT_SWITCH_VOLTAGES_2" 7 "SEAT_SWITCH_VOLTAGES_1" 6 "SEAT_2ROW_ACTUATOR" 5 "SEAT_HEAT_REARR_BACKREST" 4 "OCCUPANCY" 3 "SEAT_HEAT_REARR" 2 "SEAT_HEAT_REARC" 1 "SEAT_HEAT_REARL_CUSHION" 0 "SEAT_HEAT_FRONT" ;
VAL_ 739 VCRIGHT_frontSeatHeatCurrent 12 "SNA" ;
VAL_ 835 VCRIGHT_LVBatteryTypeDBG 5 "LV_BATTERY_TYPE_TESLA_48V_LI_ION" 4 "LV_BATTERY_TYPE_TESLA_16V_LI_ION" 3 "LV_BATTERY_TYPE_CATL_LI_ION" 2 "LV_BATTERY_TYPE_CLARIOS_B24_FLOODED" 1 "LV_BATTERY_TYPE_ATLASBX_B24_FLOODED" 0 "LV_BATTERY_TYPE_UNKNOWN" ;
VAL_ 835 VCRIGHT_rearDefrostState 4 "HEATER_STATE_FAULT" 3 "HEATER_STATE_OFF_UNAVAILABLE" 2 "HEATER_STATE_OFF" 1 "HEATER_STATE_ON" 0 "HEATER_STATE_SNA" ;
VAL_ 835 VCRIGHT_mirrorHeatState 4 "HEATER_STATE_FAULT" 3 "HEATER_STATE_OFF_UNAVAILABLE" 2 "HEATER_STATE_OFF" 1 "HEATER_STATE_ON" 0 "HEATER_STATE_SNA" ;
VAL_ 835 VCRIGHT_steeringWheelHeaterDCTgt 127 "SNA" ;
VAL_ 963 VCRIGHT_switchStatusIndex 1 "1" 0 "0" ;
VAL_ 963 VCRIGHT_frontSeatTrackBack 3 "SWITCH_FAULT" 2 "SWITCH_ON" 1 "SWITCH_OFF" 0 "SWITCH_SNA" ;
VAL_ 963 VCRIGHT_frontSeatTrackForward 3 "SWITCH_FAULT" 2 "SWITCH_ON" 1 "SWITCH_OFF" 0 "SWITCH_SNA" ;
VAL_ 963 VCRIGHT_frontSeatTiltDown 3 "SWITCH_FAULT" 2 "SWITCH_ON" 1 "SWITCH_OFF" 0 "SWITCH_SNA" ;
VAL_ 963 VCRIGHT_frontSeatTiltUp 3 "SWITCH_FAULT" 2 "SWITCH_ON" 1 "SWITCH_OFF" 0 "SWITCH_SNA" ;
VAL_ 963 VCRIGHT_frontSeatLiftDown 3 "SWITCH_FAULT" 2 "SWITCH_ON" 1 "SWITCH_OFF" 0 "SWITCH_SNA" ;
VAL_ 963 VCRIGHT_frontSeatLiftUp 3 "SWITCH_FAULT" 2 "SWITCH_ON" 1 "SWITCH_OFF" 0 "SWITCH_SNA" ;
VAL_ 963 VCRIGHT_frontSeatBackrestBack 3 "SWITCH_FAULT" 2 "SWITCH_ON" 1 "SWITCH_OFF" 0 "SWITCH_SNA" ;
VAL_ 963 VCRIGHT_frontSeatBackrestForward 3 "SWITCH_FAULT" 2 "SWITCH_ON" 1 "SWITCH_OFF" 0 "SWITCH_SNA" ;
VAL_ 963 VCRIGHT_frontSeatLumbarDown 3 "SWITCH_FAULT" 2 "SWITCH_ON" 1 "SWITCH_OFF" 0 "SWITCH_SNA" ;
VAL_ 963 VCRIGHT_frontSeatLumbarUp 3 "SWITCH_FAULT" 2 "SWITCH_ON" 1 "SWITCH_OFF" 0 "SWITCH_SNA" ;
VAL_ 963 VCRIGHT_frontSeatLumbarIn 3 "SWITCH_FAULT" 2 "SWITCH_ON" 1 "SWITCH_OFF" 0 "SWITCH_SNA" ;
VAL_ 963 VCRIGHT_frontSeatLumbarOut 3 "SWITCH_FAULT" 2 "SWITCH_ON" 1 "SWITCH_OFF" 0 "SWITCH_SNA" ;
VAL_ 963 VCRIGHT_frontSeatALR 3 "SWITCH_FAULT" 2 "SWITCH_ON" 1 "SWITCH_OFF" 0 "SWITCH_SNA" ;
VAL_ 963 VCRIGHT_frontSeatResistiveOccupa 3 "SWITCH_FAULT" 2 "SWITCH_ON" 1 "SWITCH_OFF" 0 "SWITCH_SNA" ;
VAL_ 963 VCRIGHT_2RowSeatReclineSwitchpac 6 "FAULT" 5 "REARWARD_FAST" 4 "REARWARD_SLOW" 3 "FORWARD_FAST" 2 "FORWARD_SLOW" 1 "INACTIVE" 0 "DISCONNECTED" ;
VAL_ 537 VCSEC_TPMSDataIndex 4 "RCP" 3 "Sensor3" 2 "Sensor2" 1 "Sensor1" 0 "Sensor0" ;
VAL_ 537 VCSEC_TPMSPressure0 511 "SNA" 510 "OVER_RANGE" ;
VAL_ 537 VCSEC_TPMSTemperature0 255 "SNA" ;
VAL_ 537 VCSEC_TPMSBatVoltage0 255 "SNA" ;
VAL_ 537 VCSEC_TPMSLocation0 4 "LOCATION_UNKNOWN" 3 "LOCATION_RR" 2 "LOCATION_RL" 1 "LOCATION_FR" 0 "LOCATION_FL" ;
VAL_ 537 VCSEC_TPMSTemperatureCompensated 511 "SNA" 510 "OVER_RANGE" ;
VAL_ 537 VCSEC_TPMSPressure1 511 "SNA" 510 "OVER_RANGE" ;
VAL_ 537 VCSEC_TPMSTemperature1 255 "SNA" ;
VAL_ 537 VCSEC_TPMSBatVoltage1 255 "SNA" ;
VAL_ 537 VCSEC_TPMSLocation1 4 "LOCATION_UNKNOWN" 3 "LOCATION_RR" 2 "LOCATION_RL" 1 "LOCATION_FR" 0 "LOCATION_FL" ;
VAL_ 537 VCSEC_TPMSTemperatureCompen_0001 511 "SNA" 510 "OVER_RANGE" ;
VAL_ 537 VCSEC_TPMSPressure2 511 "SNA" 510 "OVER_RANGE" ;
VAL_ 537 VCSEC_TPMSTemperature2 255 "SNA" ;
VAL_ 537 VCSEC_TPMSBatVoltage2 255 "SNA" ;
VAL_ 537 VCSEC_TPMSLocation2 4 "LOCATION_UNKNOWN" 3 "LOCATION_RR" 2 "LOCATION_RL" 1 "LOCATION_FR" 0 "LOCATION_FL" ;
VAL_ 537 VCSEC_TPMSTemperatureCompen_0002 511 "SNA" 510 "OVER_RANGE" ;
VAL_ 537 VCSEC_TPMSPressure3 511 "SNA" 510 "OVER_RANGE" ;
VAL_ 537 VCSEC_TPMSTemperature3 255 "SNA" ;
VAL_ 537 VCSEC_TPMSBatVoltage3 255 "SNA" ;
VAL_ 537 VCSEC_TPMSLocation3 4 "LOCATION_UNKNOWN" 3 "LOCATION_RR" 2 "LOCATION_RL" 1 "LOCATION_FR" 0 "LOCATION_FL" ;
VAL_ 537 VCSEC_TPMSTemperatureCompen_0003 511 "SNA" 510 "OVER_RANGE" ;
VAL_ 537 VCSEC_TPMSRecommendedColdPressur 255 "SNA" 254 "OVER_RANGE" ;
VAL_ 537 VCSEC_TPMSRecommendedColdPr_0001 255 "SNA" 254 "OVER_RANGE" ;
VAL_ 537 VCSEC_TPMSFeature0 6 "FEATURE_0_BLOCKED" 5 "FEATURE_0_ACTIVE" 4 "FEATURE_0_READY" 3 "FEATURE_0_WAIT_FOR_STATIONARY" 2 "FEATURE_0_UNAVAILABLE_2" 1 "FEATURE_0_UNAVAILABLE_1" 0 "FEATURE_0_NOT_SUPPORTED" ;
VAL_ 537 VCSEC_TPMSFeature1 5 "FEATURE_1_CLOSE" 4 "FEATURE_1_MEDIUM" 3 "FEATURE_1_FAR_AWAY" 2 "FEATURE_1_INCORRECT" 1 "FEATURE_1_REACHED" 0 "FEATURE_1_NONE" ;
VAL_ 570 VCSEC_TPMSStatusIndex 28 "SensorConfiguration" 27 "ResetCountsContinuedSensor3" 26 "ResetCountsSensor3" 25 "ResetCountsContinuedSensor2" 24 "ResetCountsSensor2" 23 "ResetCountsContinuedSensor1" 22 "ResetCountsSensor1" 21 "ResetCountsContinuedSensor0" 20 "ResetCountsSensor0" 19 "SleepStatsSensor3" 18 "SleepStatsSensor2" 17 "SleepStatsSensor1" 16 "SleepStatsSensor0" 15 "CPUTimeSensor3" 14 "CPUTimeSensor2" 13 "CPUTimeSensor1" 12 "CPUTimeSensor0" 11 "CRCSensor3" 10 "CRCSensor2" 9 "CRCSensor1" 8 "CRCSensor0" 7 "ConnMetricsSensor3" 6 "ConnMetricsSensor2" 5 "ConnMetricsSensor1" 4 "ConnMetricsSensor0" 3 "MACAddressSensor3" 2 "MACAddressSensor2" 1 "MACAddressSensor1" 0 "MACAddressSensor0" ;
VAL_ 570 VCSEC_TPMSSystemState 1 "TPMS_SYSTEM_STATE_ACTIVE" 0 "TPMS_SYSTEM_STATE_IDLE" ;
VAL_ 570 VCSEC_BLEUnsuccessfulConnEventRa 1023 "SNA" ;
VAL_ 570 VCSEC_BLEUnsuccessfulConnEv_0001 1023 "SNA" ;
VAL_ 570 VCSEC_BLEUnsuccessfulConnEv_0002 1023 "SNA" ;
VAL_ 570 VCSEC_BLEUnsuccessfulConnEv_0003 1023 "SNA" ;
VAL_ 570 VCSEC_TPMSSensorTIAppCRC0 0 "TPMS_CRC_SNA" ;
VAL_ 570 VCSEC_TPMSSensorMLXAppCRC0 0 "TPMS_CRC_SNA" ;
VAL_ 570 VCSEC_TPMSSensorTIAppCRC1 0 "TPMS_CRC_SNA" ;
VAL_ 570 VCSEC_TPMSSensorMLXAppCRC1 0 "TPMS_CRC_SNA" ;
VAL_ 570 VCSEC_TPMSSensorTIAppCRC2 0 "TPMS_CRC_SNA" ;
VAL_ 570 VCSEC_TPMSSensorMLXAppCRC2 0 "TPMS_CRC_SNA" ;
VAL_ 570 VCSEC_TPMSSensorTIAppCRC3 0 "TPMS_CRC_SNA" ;
VAL_ 570 VCSEC_TPMSSensorMLXAppCRC3 0 "TPMS_CRC_SNA" ;
VAL_ 570 VCSEC_TPMSGenealogySensorState0 7 "SENSOR_STATE_DONE" 6 "SENSOR_STATE_WAIT_FOR_CAPABILITIES_RESPONSE" 5 "SENSOR_STATE_SEND_CAPABILITIES_REQUEST" 4 "SENSOR_STATE_WAIT_FOR_GENEALOGY_RESPONSE" 3 "SENSOR_STATE_SEND_GENEALOGY_REQUEST" 2 "SENSOR_STATE_WAIT_FOR_CODE_DESCRIPTOR_RESPONSE" 1 "SENSOR_STATE_SEND_CODE_DESCRIPTOR_REQUEST" 0 "SENSOR_STATE_WAIT_FOR_CONNECTION" ;
VAL_ 570 VCSEC_TPMSSensorType0 6 "SENSOR_TYPE_V5" 5 "SENSOR_TYPE_V4" 4 "SENSOR_TYPE_V3" 3 "SENSOR_TYPE_V2" 2 "SENSOR_TYPE_V1" 1 "SENSOR_TYPE_UNKNOWN" 0 "SENSOR_TYPE_NOT_IDENTIFIED" ;
VAL_ 570 VCSEC_TPMSGenealogySensorState1 7 "SENSOR_STATE_DONE" 6 "SENSOR_STATE_WAIT_FOR_CAPABILITIES_RESPONSE" 5 "SENSOR_STATE_SEND_CAPABILITIES_REQUEST" 4 "SENSOR_STATE_WAIT_FOR_GENEALOGY_RESPONSE" 3 "SENSOR_STATE_SEND_GENEALOGY_REQUEST" 2 "SENSOR_STATE_WAIT_FOR_CODE_DESCRIPTOR_RESPONSE" 1 "SENSOR_STATE_SEND_CODE_DESCRIPTOR_REQUEST" 0 "SENSOR_STATE_WAIT_FOR_CONNECTION" ;
VAL_ 570 VCSEC_TPMSSensorType1 6 "SENSOR_TYPE_V5" 5 "SENSOR_TYPE_V4" 4 "SENSOR_TYPE_V3" 3 "SENSOR_TYPE_V2" 2 "SENSOR_TYPE_V1" 1 "SENSOR_TYPE_UNKNOWN" 0 "SENSOR_TYPE_NOT_IDENTIFIED" ;
VAL_ 570 VCSEC_TPMSGenealogySensorState2 7 "SENSOR_STATE_DONE" 6 "SENSOR_STATE_WAIT_FOR_CAPABILITIES_RESPONSE" 5 "SENSOR_STATE_SEND_CAPABILITIES_REQUEST" 4 "SENSOR_STATE_WAIT_FOR_GENEALOGY_RESPONSE" 3 "SENSOR_STATE_SEND_GENEALOGY_REQUEST" 2 "SENSOR_STATE_WAIT_FOR_CODE_DESCRIPTOR_RESPONSE" 1 "SENSOR_STATE_SEND_CODE_DESCRIPTOR_REQUEST" 0 "SENSOR_STATE_WAIT_FOR_CONNECTION" ;
VAL_ 570 VCSEC_TPMSSensorType2 6 "SENSOR_TYPE_V5" 5 "SENSOR_TYPE_V4" 4 "SENSOR_TYPE_V3" 3 "SENSOR_TYPE_V2" 2 "SENSOR_TYPE_V1" 1 "SENSOR_TYPE_UNKNOWN" 0 "SENSOR_TYPE_NOT_IDENTIFIED" ;
VAL_ 570 VCSEC_TPMSGenealogySensorState3 7 "SENSOR_STATE_DONE" 6 "SENSOR_STATE_WAIT_FOR_CAPABILITIES_RESPONSE" 5 "SENSOR_STATE_SEND_CAPABILITIES_REQUEST" 4 "SENSOR_STATE_WAIT_FOR_GENEALOGY_RESPONSE" 3 "SENSOR_STATE_SEND_GENEALOGY_REQUEST" 2 "SENSOR_STATE_WAIT_FOR_CODE_DESCRIPTOR_RESPONSE" 1 "SENSOR_STATE_SEND_CODE_DESCRIPTOR_REQUEST" 0 "SENSOR_STATE_WAIT_FOR_CONNECTION" ;
VAL_ 570 VCSEC_TPMSSensorType3 6 "SENSOR_TYPE_V5" 5 "SENSOR_TYPE_V4" 4 "SENSOR_TYPE_V3" 3 "SENSOR_TYPE_V2" 2 "SENSOR_TYPE_V1" 1 "SENSOR_TYPE_UNKNOWN" 0 "SENSOR_TYPE_NOT_IDENTIFIED" ;
VAL_ 1067 VCSEC_UWBEndpointIndex 3 "UWBDistance0" 2 "UWBDistance1" 1 "UWBDistance2" 0 "UWBRearRightDistance" ;
VAL_ 1067 VCSEC_UWBRearRightDistance0 4095 "SNA" 4094 "NOT_ENABLED" 4093 "INITIATOR_TIMEOUT" 4092 "RESPONDER_TIMEOUT" 4091 "INVALID_DISTANCE" 4090 "HCI_TIMEOUT" 4089 "RESPONDER_ERROR" 4088 "KEYFOB_DIDNT_RESPOND" 4087 "TX_FAILED" 4086 "RX_TIMEOUT" 4085 "PHY_DEC_FAILED" 4084 "TOA_FAILED" 4083 "STS_FAILED" 4082 "MAC_DEC_FAILED" 4081 "IE_DEC_FAILED" 4080 "IE_MISSING" ;
VAL_ 1067 VCSEC_UWBRearRightDistance1 4095 "SNA" 4094 "NOT_ENABLED" 4093 "INITIATOR_TIMEOUT" 4092 "RESPONDER_TIMEOUT" 4091 "INVALID_DISTANCE" 4090 "HCI_TIMEOUT" 4089 "RESPONDER_ERROR" 4088 "KEYFOB_DIDNT_RESPOND" 4087 "TX_FAILED" 4086 "RX_TIMEOUT" 4085 "PHY_DEC_FAILED" 4084 "TOA_FAILED" 4083 "STS_FAILED" 4082 "MAC_DEC_FAILED" 4081 "IE_DEC_FAILED" 4080 "IE_MISSING" ;
VAL_ 1067 VCSEC_UWBRearRightDistance2 4095 "SNA" 4094 "NOT_ENABLED" 4093 "INITIATOR_TIMEOUT" 4092 "RESPONDER_TIMEOUT" 4091 "INVALID_DISTANCE" 4090 "HCI_TIMEOUT" 4089 "RESPONDER_ERROR" 4088 "KEYFOB_DIDNT_RESPOND" 4087 "TX_FAILED" 4086 "RX_TIMEOUT" 4085 "PHY_DEC_FAILED" 4084 "TOA_FAILED" 4083 "STS_FAILED" 4082 "MAC_DEC_FAILED" 4081 "IE_DEC_FAILED" 4080 "IE_MISSING" ;
VAL_ 1067 VCSEC_UWBLeftDistance2 4095 "SNA" 4094 "NOT_ENABLED" 4093 "INITIATOR_TIMEOUT" 4092 "RESPONDER_TIMEOUT" 4091 "INVALID_DISTANCE" 4090 "HCI_TIMEOUT" 4089 "RESPONDER_ERROR" 4088 "KEYFOB_DIDNT_RESPOND" 4087 "TX_FAILED" 4086 "RX_TIMEOUT" 4085 "PHY_DEC_FAILED" 4084 "TOA_FAILED" 4083 "STS_FAILED" 4082 "MAC_DEC_FAILED" 4081 "IE_DEC_FAILED" 4080 "IE_MISSING" ;
VAL_ 1067 VCSEC_UWBRightDistance2 4095 "SNA" 4094 "NOT_ENABLED" 4093 "INITIATOR_TIMEOUT" 4092 "RESPONDER_TIMEOUT" 4091 "INVALID_DISTANCE" 4090 "HCI_TIMEOUT" 4089 "RESPONDER_ERROR" 4088 "KEYFOB_DIDNT_RESPOND" 4087 "TX_FAILED" 4086 "RX_TIMEOUT" 4085 "PHY_DEC_FAILED" 4084 "TOA_FAILED" 4083 "STS_FAILED" 4082 "MAC_DEC_FAILED" 4081 "IE_DEC_FAILED" 4080 "IE_MISSING" ;
VAL_ 1067 VCSEC_UWBRearDistance2 4095 "SNA" 4094 "NOT_ENABLED" 4093 "INITIATOR_TIMEOUT" 4092 "RESPONDER_TIMEOUT" 4091 "INVALID_DISTANCE" 4090 "HCI_TIMEOUT" 4089 "RESPONDER_ERROR" 4088 "KEYFOB_DIDNT_RESPOND" 4087 "TX_FAILED" 4086 "RX_TIMEOUT" 4085 "PHY_DEC_FAILED" 4084 "TOA_FAILED" 4083 "STS_FAILED" 4082 "MAC_DEC_FAILED" 4081 "IE_DEC_FAILED" 4080 "IE_MISSING" ;
VAL_ 1067 VCSEC_UWBRearLeftDistance2 4095 "SNA" 4094 "NOT_ENABLED" 4093 "INITIATOR_TIMEOUT" 4092 "RESPONDER_TIMEOUT" 4091 "INVALID_DISTANCE" 4090 "HCI_TIMEOUT" 4089 "RESPONDER_ERROR" 4088 "KEYFOB_DIDNT_RESPOND" 4087 "TX_FAILED" 4086 "RX_TIMEOUT" 4085 "PHY_DEC_FAILED" 4084 "TOA_FAILED" 4083 "STS_FAILED" 4082 "MAC_DEC_FAILED" 4081 "IE_DEC_FAILED" 4080 "IE_MISSING" ;
VAL_ 1067 VCSEC_UWBCenterDistance2 4095 "SNA" 4094 "NOT_ENABLED" 4093 "INITIATOR_TIMEOUT" 4092 "RESPONDER_TIMEOUT" 4091 "INVALID_DISTANCE" 4090 "HCI_TIMEOUT" 4089 "RESPONDER_ERROR" 4088 "KEYFOB_DIDNT_RESPOND" 4087 "TX_FAILED" 4086 "RX_TIMEOUT" 4085 "PHY_DEC_FAILED" 4084 "TOA_FAILED" 4083 "STS_FAILED" 4082 "MAC_DEC_FAILED" 4081 "IE_DEC_FAILED" 4080 "IE_MISSING" ;
VAL_ 1067 VCSEC_UWBLeftDistance1 4095 "SNA" 4094 "NOT_ENABLED" 4093 "INITIATOR_TIMEOUT" 4092 "RESPONDER_TIMEOUT" 4091 "INVALID_DISTANCE" 4090 "HCI_TIMEOUT" 4089 "RESPONDER_ERROR" 4088 "KEYFOB_DIDNT_RESPOND" 4087 "TX_FAILED" 4086 "RX_TIMEOUT" 4085 "PHY_DEC_FAILED" 4084 "TOA_FAILED" 4083 "STS_FAILED" 4082 "MAC_DEC_FAILED" 4081 "IE_DEC_FAILED" 4080 "IE_MISSING" ;
VAL_ 1067 VCSEC_UWBRightDistance1 4095 "SNA" 4094 "NOT_ENABLED" 4093 "INITIATOR_TIMEOUT" 4092 "RESPONDER_TIMEOUT" 4091 "INVALID_DISTANCE" 4090 "HCI_TIMEOUT" 4089 "RESPONDER_ERROR" 4088 "KEYFOB_DIDNT_RESPOND" 4087 "TX_FAILED" 4086 "RX_TIMEOUT" 4085 "PHY_DEC_FAILED" 4084 "TOA_FAILED" 4083 "STS_FAILED" 4082 "MAC_DEC_FAILED" 4081 "IE_DEC_FAILED" 4080 "IE_MISSING" ;
VAL_ 1067 VCSEC_UWBRearDistance1 4095 "SNA" 4094 "NOT_ENABLED" 4093 "INITIATOR_TIMEOUT" 4092 "RESPONDER_TIMEOUT" 4091 "INVALID_DISTANCE" 4090 "HCI_TIMEOUT" 4089 "RESPONDER_ERROR" 4088 "KEYFOB_DIDNT_RESPOND" 4087 "TX_FAILED" 4086 "RX_TIMEOUT" 4085 "PHY_DEC_FAILED" 4084 "TOA_FAILED" 4083 "STS_FAILED" 4082 "MAC_DEC_FAILED" 4081 "IE_DEC_FAILED" 4080 "IE_MISSING" ;
VAL_ 1067 VCSEC_UWBRearLeftDistance1 4095 "SNA" 4094 "NOT_ENABLED" 4093 "INITIATOR_TIMEOUT" 4092 "RESPONDER_TIMEOUT" 4091 "INVALID_DISTANCE" 4090 "HCI_TIMEOUT" 4089 "RESPONDER_ERROR" 4088 "KEYFOB_DIDNT_RESPOND" 4087 "TX_FAILED" 4086 "RX_TIMEOUT" 4085 "PHY_DEC_FAILED" 4084 "TOA_FAILED" 4083 "STS_FAILED" 4082 "MAC_DEC_FAILED" 4081 "IE_DEC_FAILED" 4080 "IE_MISSING" ;
VAL_ 1067 VCSEC_UWBCenterDistance1 4095 "SNA" 4094 "NOT_ENABLED" 4093 "INITIATOR_TIMEOUT" 4092 "RESPONDER_TIMEOUT" 4091 "INVALID_DISTANCE" 4090 "HCI_TIMEOUT" 4089 "RESPONDER_ERROR" 4088 "KEYFOB_DIDNT_RESPOND" 4087 "TX_FAILED" 4086 "RX_TIMEOUT" 4085 "PHY_DEC_FAILED" 4084 "TOA_FAILED" 4083 "STS_FAILED" 4082 "MAC_DEC_FAILED" 4081 "IE_DEC_FAILED" 4080 "IE_MISSING" ;
VAL_ 1067 VCSEC_UWBLeftDistance0 4095 "SNA" 4094 "NOT_ENABLED" 4093 "INITIATOR_TIMEOUT" 4092 "RESPONDER_TIMEOUT" 4091 "INVALID_DISTANCE" 4090 "HCI_TIMEOUT" 4089 "RESPONDER_ERROR" 4088 "KEYFOB_DIDNT_RESPOND" 4087 "TX_FAILED" 4086 "RX_TIMEOUT" 4085 "PHY_DEC_FAILED" 4084 "TOA_FAILED" 4083 "STS_FAILED" 4082 "MAC_DEC_FAILED" 4081 "IE_DEC_FAILED" 4080 "IE_MISSING" ;
VAL_ 1067 VCSEC_UWBRightDistance0 4095 "SNA" 4094 "NOT_ENABLED" 4093 "INITIATOR_TIMEOUT" 4092 "RESPONDER_TIMEOUT" 4091 "INVALID_DISTANCE" 4090 "HCI_TIMEOUT" 4089 "RESPONDER_ERROR" 4088 "KEYFOB_DIDNT_RESPOND" 4087 "TX_FAILED" 4086 "RX_TIMEOUT" 4085 "PHY_DEC_FAILED" 4084 "TOA_FAILED" 4083 "STS_FAILED" 4082 "MAC_DEC_FAILED" 4081 "IE_DEC_FAILED" 4080 "IE_MISSING" ;
VAL_ 1067 VCSEC_UWBRearDistance0 4095 "SNA" 4094 "NOT_ENABLED" 4093 "INITIATOR_TIMEOUT" 4092 "RESPONDER_TIMEOUT" 4091 "INVALID_DISTANCE" 4090 "HCI_TIMEOUT" 4089 "RESPONDER_ERROR" 4088 "KEYFOB_DIDNT_RESPOND" 4087 "TX_FAILED" 4086 "RX_TIMEOUT" 4085 "PHY_DEC_FAILED" 4084 "TOA_FAILED" 4083 "STS_FAILED" 4082 "MAC_DEC_FAILED" 4081 "IE_DEC_FAILED" 4080 "IE_MISSING" ;
VAL_ 1067 VCSEC_UWBRearLeftDistance0 4095 "SNA" 4094 "NOT_ENABLED" 4093 "INITIATOR_TIMEOUT" 4092 "RESPONDER_TIMEOUT" 4091 "INVALID_DISTANCE" 4090 "HCI_TIMEOUT" 4089 "RESPONDER_ERROR" 4088 "KEYFOB_DIDNT_RESPOND" 4087 "TX_FAILED" 4086 "RX_TIMEOUT" 4085 "PHY_DEC_FAILED" 4084 "TOA_FAILED" 4083 "STS_FAILED" 4082 "MAC_DEC_FAILED" 4081 "IE_DEC_FAILED" 4080 "IE_MISSING" ;
VAL_ 1067 VCSEC_UWBCenterDistance0 4095 "SNA" 4094 "NOT_ENABLED" 4093 "INITIATOR_TIMEOUT" 4092 "RESPONDER_TIMEOUT" 4091 "INVALID_DISTANCE" 4090 "HCI_TIMEOUT" 4089 "RESPONDER_ERROR" 4088 "KEYFOB_DIDNT_RESPOND" 4087 "TX_FAILED" 4086 "RX_TIMEOUT" 4085 "PHY_DEC_FAILED" 4084 "TOA_FAILED" 4083 "STS_FAILED" 4082 "MAC_DEC_FAILED" 4081 "IE_DEC_FAILED" 4080 "IE_MISSING" ;
VAL_ 761 VCSEC_bleDisconnectionReason 255 "UNKNOWN_REASON_FF" 62 "CONNECTION_FAILED_TO_ESTABLISH" 61 "MIC_FAILURE" 59 "UNACCEPTABLE_CONNECTION_INTERVAL" 41 "KEY_PAIRING_NOT_SUPPORTED" 40 "CONTROL_PACKET_INSTANT_PASSED" 34 "CONTROL_PACKET_TIMEOUT" 26 "UNSUPPORTED_REMOTE_FEATURE" 22 "HOST_REQUESTED_TERMINATION" 21 "REMOTE_DEVICE_POWER_OFF" 20 "REMOTE_DEVICE_LOW_RESOURCES" 19 "REMOTE_USER_TERMINATED" 8 "CONNECTION_SUPERVISION_TIMEOUT" 5 "AUTHENTICATION_FAILURE" 0 "UNKNOWN_REASON_0" ;
VAL_ 761 VCSEC_AdditionalAuthInfoIndex 5 "WALKUP_UNLOCK_BEHAVIOR" 4 "UNKNOWN_BLE_DEVICE_WITH_IN_SUMMON_RANGE" 3 "KEY_WITH_IN_SUMMON_RANGE_2" 2 "KEY_WITH_IN_SUMMON_RANGE_1" 1 "KEY_WITH_IN_SUMMON_RANGE_0" 0 "ACTIVE_KEY_SHA1" ;
VAL_ 761 VCSEC_activeKeyReason 7 "ACTIVE_KEY_SELECTION_REASON_UWB_DEVICE_CLOSEST_TO_DOOR" 6 "ACTIVE_KEY_SELECTION_REASON_AUTO_PRESENT_DOOR_COMMAND" 5 "ACTIVE_KEY_SELECTION_REASON_ONLY_AUTHED_DEVICE" 4 "ACTIVE_KEY_SELECTION_REASON_RKE_ACTION" 3 "ACTIVE_KEY_SELECTION_REASON_BLE_DEVICE_CLOSEST_TO_DOOR" 2 "ACTIVE_KEY_SELECTION_REASON_RKE_AUTH" 1 "ACTIVE_KEY_SELECTION_REASON_NFC_AUTH" 0 "ACTIVE_KEY_SELECTION_REASON_NONE" ;
VAL_ 761 VCSEC_algoUsedForSummonRange0 1 "SUMMON_RANGE_ALGO_USED_UWB" 0 "SUMMON_RANGE_ALGO_USED_BLE" ;
VAL_ 761 VCSEC_algoUsedForSummonRange1 1 "SUMMON_RANGE_ALGO_USED_UWB" 0 "SUMMON_RANGE_ALGO_USED_BLE" ;
VAL_ 761 VCSEC_algoUsedForSummonRange2 1 "SUMMON_RANGE_ALGO_USED_UWB" 0 "SUMMON_RANGE_ALGO_USED_BLE" ;
VAL_ 761 VCSEC_NFCAuthFromBPillarFormFact 4 "KEY_FORM_FACTOR_COARSE_UNKNOWN" 3 "KEY_FORM_FACTOR_COARSE_ANDROID" 2 "KEY_FORM_FACTOR_COARSE_KEYFOB" 1 "KEY_FORM_FACTOR_COARSE_NFC_CARD" 0 "KEY_FORM_FACTOR_COARSE_NONE" ;
VAL_ 761 VCSEC_NFCAuthFromCenterConsoleFo 4 "KEY_FORM_FACTOR_COARSE_UNKNOWN" 3 "KEY_FORM_FACTOR_COARSE_ANDROID" 2 "KEY_FORM_FACTOR_COARSE_KEYFOB" 1 "KEY_FORM_FACTOR_COARSE_NFC_CARD" 0 "KEY_FORM_FACTOR_COARSE_NONE" ;
VAL_ 1817 VCSEC_debug100msIndex 23 "ConnectionBenchmark2" 22 "ConnectionBenchmark1" 21 "ConnectionBenchmark0" 20 "WatchDebug" 19 "SerialPortDebug" 14 "NNClassifierDebug" 13 "ProtobufDebug" 12 "RoutableDebug" 10 "UHFReceiver" 9 "NIState2" 8 "NIState0" 7 "BLEBondingState" 5 "Mux5" 2 "LastAdvertRSSI" 1 "Mux1" 0 "Mux0" ;
VAL_ 1817 VCSEC_walkAwayLockKeyState 3 "SECURITY_WALKAWAYLOCKING_NO_KEYS_PRESENT" 2 "SECURITY_WALKAWAYLOCKING_KEY_WAIT_FOR_NO_KEYS_PRESENT" 1 "SECURITY_WALKAWAYLOCKING_KEY_STATE_AWAITING_KEY_LEAVING" 0 "SECURITY_WALKAWAYLOCKING_KEY_STATE_IDLE" ;
VAL_ 1817 VCSEC_walkAwayLockState 5 "SECURITY_WALKAWAYLOCKING_STATE_INHIBITED" 4 "SECURITY_WALKAWAYLOCKING_STATE_DISABLED_DUE_TO_KEY_PRESENT" 3 "SECURITY_WALKAWAYLOCKING_STATE_LOCK_DESIRED" 2 "SECURITY_WALKAWAYLOCKING_STATE_WAITING_FOR_KEY_LEAVING" 1 "SECURITY_WALKAWAYLOCKING_STATE_WALK_AWAY_LOCK_ARMING" 0 "SECURITY_WALKAWAYLOCKING_STATE_IDLE" ;
VAL_ 1817 VCSEC_endpointLayout 2 "VCSEC_ENDPOINT_LAYOUT_3" 1 "VCSEC_ENDPOINT_LAYOUT_2" 0 "VCSEC_ENDPOINT_LAYOUT_1" ;
VAL_ 1817 VCSEC_walkUpUnlockState 4 "WALK_UP_UNLOCK_STATE_DISABLED" 3 "WALK_UP_UNLOCK_STATE_UNLOCK_DESIRED" 2 "WALK_UP_UNLOCK_STATE_AWAITING_KEY" 1 "WALK_UP_UNLOCK_STATE_ARMING" 0 "WALK_UP_UNLOCK_STATE_IDLE" ;
VAL_ 1817 VCSEC_pollingReason 13 "POLLINGREASON_MULTIPLE" 12 "POLLINGREASON_AUTOPILOT" 11 "POLLINGREASON_APPROACH_LIGHTING" 10 "POLLINGREASON_AUTO_PRESENT_HANDLES" 9 "POLLINGREASON_AUTORELOCK" 8 "POLLINGREASON_DRIVE_AWAY_CHECK_FOR_KEY" 7 "POLLINGREASON_AUTO_PRESENT_DOOR" 6 "POLLINGREASON_ACCESSORY_RAIL" 5 "POLLINGREASON_WALK_UP_UNLOCK" 4 "POLLINGREASON_WALK_AWAY_LOCK" 3 "POLLINGREASON_PASSIVE_UNLOCK" 2 "POLLINGREASON_PASSIVE_AUTHENTICATION" 1 "POLLINGREASON_IMMOBILIZER" 0 "POLLINGREASON_NONE" ;
VAL_ 1817 VCSEC_thermalDetectState 3 "VCSEC_THERMALDETECTIONSTATE_TRIPPED" 2 "VCSEC_THERMALDETECTIONSTATE_CONFIRMING_THRESHOLD" 1 "VCSEC_THERMALDETECTIONSTATE_MONITORING" 0 "VCSEC_THERMALDETECTIONSTATE_DISABLED" ;
VAL_ 1817 VCSEC_connection0BondingState 15 "WAIT_FOR_BOND_REJECTED" 14 "BOND" 13 "WAIT_FOR_BOND_REQUEST" 12 "BOND_FAILURE" 11 "PAIRING_REQUESTED" 10 "REJECT_BOND" 9 "WAIT_FOR_SIGNABLE" 8 "SEND_SIGNABLE" 7 "WAIT_FOR_BOND" 6 "WAIT_FOR_PAIRING" 5 "WAIT_FOR_AUTHENTICATE" 4 "SHOULD_BE_BONDED" 3 "BONDED" 2 "NOT_BONDED" 1 "CONNECTED" 0 "NOT_CONNECTED" ;
VAL_ 1817 VCSEC_connection1BondingState 15 "WAIT_FOR_BOND_REJECTED" 14 "BOND" 13 "WAIT_FOR_BOND_REQUEST" 12 "BOND_FAILURE" 11 "PAIRING_REQUESTED" 10 "REJECT_BOND" 9 "WAIT_FOR_SIGNABLE" 8 "SEND_SIGNABLE" 7 "WAIT_FOR_BOND" 6 "WAIT_FOR_PAIRING" 5 "WAIT_FOR_AUTHENTICATE" 4 "SHOULD_BE_BONDED" 3 "BONDED" 2 "NOT_BONDED" 1 "CONNECTED" 0 "NOT_CONNECTED" ;
VAL_ 1817 VCSEC_connection2BondingState 15 "WAIT_FOR_BOND_REJECTED" 14 "BOND" 13 "WAIT_FOR_BOND_REQUEST" 12 "BOND_FAILURE" 11 "PAIRING_REQUESTED" 10 "REJECT_BOND" 9 "WAIT_FOR_SIGNABLE" 8 "SEND_SIGNABLE" 7 "WAIT_FOR_BOND" 6 "WAIT_FOR_PAIRING" 5 "WAIT_FOR_AUTHENTICATE" 4 "SHOULD_BE_BONDED" 3 "BONDED" 2 "NOT_BONDED" 1 "CONNECTED" 0 "NOT_CONNECTED" ;
VAL_ 1817 VCSEC_connection0UWBAvailability 16 "UNAVAILABLE_UNKNOWN_REASON" 15 "UNAVAILABLE_UWB_DISABLED_BY_USER" 14 "PHONE_ERROR" 13 "RADIOCONFIG_NOT_READY" 12 "UPDATE_NOT_READY" 11 "GENEALOGY_NOT_READY" 10 "BLE_CHIP_NOT_READY" 9 "UWB_CHIP_NOT_READY" 8 "UNAVAILABLE_NOT_SELECTED" 7 "UWB_NOT_ENABLED_ON_THE_VEHICLE" 6 "AVAILBLE_BUT_NOT_GAP_BONDED" 5 "UNAVAILABLE_PERMISSION_DENIED" 4 "UNAVAILABLE_UNSUPPORTED_DEVICE" 3 "TEMPORARILY_UNAVAILABLE" 2 "AVAILABLE_BUT_NOT_RANGING_ON_DRIVER_ENDPOINT" 1 "AVAILABLE" 0 "NONE" ;
VAL_ 1817 VCSEC_connection1UWBAvailability 16 "UNAVAILABLE_UNKNOWN_REASON" 15 "UNAVAILABLE_UWB_DISABLED_BY_USER" 14 "PHONE_ERROR" 13 "RADIOCONFIG_NOT_READY" 12 "UPDATE_NOT_READY" 11 "GENEALOGY_NOT_READY" 10 "BLE_CHIP_NOT_READY" 9 "UWB_CHIP_NOT_READY" 8 "UNAVAILABLE_NOT_SELECTED" 7 "UWB_NOT_ENABLED_ON_THE_VEHICLE" 6 "AVAILBLE_BUT_NOT_GAP_BONDED" 5 "UNAVAILABLE_PERMISSION_DENIED" 4 "UNAVAILABLE_UNSUPPORTED_DEVICE" 3 "TEMPORARILY_UNAVAILABLE" 2 "AVAILABLE_BUT_NOT_RANGING_ON_DRIVER_ENDPOINT" 1 "AVAILABLE" 0 "NONE" ;
VAL_ 1817 VCSEC_connection2UWBAvailability 16 "UNAVAILABLE_UNKNOWN_REASON" 15 "UNAVAILABLE_UWB_DISABLED_BY_USER" 14 "PHONE_ERROR" 13 "RADIOCONFIG_NOT_READY" 12 "UPDATE_NOT_READY" 11 "GENEALOGY_NOT_READY" 10 "BLE_CHIP_NOT_READY" 9 "UWB_CHIP_NOT_READY" 8 "UNAVAILABLE_NOT_SELECTED" 7 "UWB_NOT_ENABLED_ON_THE_VEHICLE" 6 "AVAILBLE_BUT_NOT_GAP_BONDED" 5 "UNAVAILABLE_PERMISSION_DENIED" 4 "UNAVAILABLE_UNSUPPORTED_DEVICE" 3 "TEMPORARILY_UNAVAILABLE" 2 "AVAILABLE_BUT_NOT_RANGING_ON_DRIVER_ENDPOINT" 1 "AVAILABLE" 0 "NONE" ;
VAL_ 1817 VCSEC_NISessionStateCenter0 21 "COUNT" 20 "SESSION_INITIATE" 19 "WAIT_FOR_SESSION_INITIATE" 18 "WAIT_FOR_SESSION_STATE_ACTIVE" 17 "UNRECOVERABLE_DEVICE_ERROR" 16 "ERROR_WAIT_FOR_RESET" 15 "WAIT_FOR_RETRY_AFTER_ERROR" 14 "WAIT_FOR_SESSION_DEINIT" 13 "DEINIT_SESSION" 12 "WAIT_FOR_SESSION_STOP" 11 "STOP_SESSION" 10 "RANGING" 9 "WAIT_FOR_RANGING_STARTED_CONFIRMATION" 8 "WAIT_FOR_APPLE_SESSION_INITIATE" 7 "APPLE_SESSION_INITIATE" 6 "WAIT_FOR_APPLE_SHAREABLE_CONFIGURATION_DATA" 5 "SEND_CONFIGURATION_DATA_TO_PHONE" 4 "WAIT_FOR_CONFIGURATION_DATA" 3 "REQUEST_CONFIGURATION_DATA" 2 "WAIT_FOR_CORE_CONFIG_DATA" 1 "APPLY_CORE_CONFIG_DATA" 0 "IDLE" ;
VAL_ 1817 VCSEC_NISessionStateLeft0 21 "COUNT" 20 "SESSION_INITIATE" 19 "WAIT_FOR_SESSION_INITIATE" 18 "WAIT_FOR_SESSION_STATE_ACTIVE" 17 "UNRECOVERABLE_DEVICE_ERROR" 16 "ERROR_WAIT_FOR_RESET" 15 "WAIT_FOR_RETRY_AFTER_ERROR" 14 "WAIT_FOR_SESSION_DEINIT" 13 "DEINIT_SESSION" 12 "WAIT_FOR_SESSION_STOP" 11 "STOP_SESSION" 10 "RANGING" 9 "WAIT_FOR_RANGING_STARTED_CONFIRMATION" 8 "WAIT_FOR_APPLE_SESSION_INITIATE" 7 "APPLE_SESSION_INITIATE" 6 "WAIT_FOR_APPLE_SHAREABLE_CONFIGURATION_DATA" 5 "SEND_CONFIGURATION_DATA_TO_PHONE" 4 "WAIT_FOR_CONFIGURATION_DATA" 3 "REQUEST_CONFIGURATION_DATA" 2 "WAIT_FOR_CORE_CONFIG_DATA" 1 "APPLY_CORE_CONFIG_DATA" 0 "IDLE" ;
VAL_ 1817 VCSEC_NISessionStateRight0 21 "COUNT" 20 "SESSION_INITIATE" 19 "WAIT_FOR_SESSION_INITIATE" 18 "WAIT_FOR_SESSION_STATE_ACTIVE" 17 "UNRECOVERABLE_DEVICE_ERROR" 16 "ERROR_WAIT_FOR_RESET" 15 "WAIT_FOR_RETRY_AFTER_ERROR" 14 "WAIT_FOR_SESSION_DEINIT" 13 "DEINIT_SESSION" 12 "WAIT_FOR_SESSION_STOP" 11 "STOP_SESSION" 10 "RANGING" 9 "WAIT_FOR_RANGING_STARTED_CONFIRMATION" 8 "WAIT_FOR_APPLE_SESSION_INITIATE" 7 "APPLE_SESSION_INITIATE" 6 "WAIT_FOR_APPLE_SHAREABLE_CONFIGURATION_DATA" 5 "SEND_CONFIGURATION_DATA_TO_PHONE" 4 "WAIT_FOR_CONFIGURATION_DATA" 3 "REQUEST_CONFIGURATION_DATA" 2 "WAIT_FOR_CORE_CONFIG_DATA" 1 "APPLY_CORE_CONFIG_DATA" 0 "IDLE" ;
VAL_ 1817 VCSEC_NISessionStateRearLeft0 21 "COUNT" 20 "SESSION_INITIATE" 19 "WAIT_FOR_SESSION_INITIATE" 18 "WAIT_FOR_SESSION_STATE_ACTIVE" 17 "UNRECOVERABLE_DEVICE_ERROR" 16 "ERROR_WAIT_FOR_RESET" 15 "WAIT_FOR_RETRY_AFTER_ERROR" 14 "WAIT_FOR_SESSION_DEINIT" 13 "DEINIT_SESSION" 12 "WAIT_FOR_SESSION_STOP" 11 "STOP_SESSION" 10 "RANGING" 9 "WAIT_FOR_RANGING_STARTED_CONFIRMATION" 8 "WAIT_FOR_APPLE_SESSION_INITIATE" 7 "APPLE_SESSION_INITIATE" 6 "WAIT_FOR_APPLE_SHAREABLE_CONFIGURATION_DATA" 5 "SEND_CONFIGURATION_DATA_TO_PHONE" 4 "WAIT_FOR_CONFIGURATION_DATA" 3 "REQUEST_CONFIGURATION_DATA" 2 "WAIT_FOR_CORE_CONFIG_DATA" 1 "APPLY_CORE_CONFIG_DATA" 0 "IDLE" ;
VAL_ 1817 VCSEC_NISessionStateRearRight0 21 "COUNT" 20 "SESSION_INITIATE" 19 "WAIT_FOR_SESSION_INITIATE" 18 "WAIT_FOR_SESSION_STATE_ACTIVE" 17 "UNRECOVERABLE_DEVICE_ERROR" 16 "ERROR_WAIT_FOR_RESET" 15 "WAIT_FOR_RETRY_AFTER_ERROR" 14 "WAIT_FOR_SESSION_DEINIT" 13 "DEINIT_SESSION" 12 "WAIT_FOR_SESSION_STOP" 11 "STOP_SESSION" 10 "RANGING" 9 "WAIT_FOR_RANGING_STARTED_CONFIRMATION" 8 "WAIT_FOR_APPLE_SESSION_INITIATE" 7 "APPLE_SESSION_INITIATE" 6 "WAIT_FOR_APPLE_SHAREABLE_CONFIGURATION_DATA" 5 "SEND_CONFIGURATION_DATA_TO_PHONE" 4 "WAIT_FOR_CONFIGURATION_DATA" 3 "REQUEST_CONFIGURATION_DATA" 2 "WAIT_FOR_CORE_CONFIG_DATA" 1 "APPLY_CORE_CONFIG_DATA" 0 "IDLE" ;
VAL_ 1817 VCSEC_NISessionStateRear0 21 "COUNT" 20 "SESSION_INITIATE" 19 "WAIT_FOR_SESSION_INITIATE" 18 "WAIT_FOR_SESSION_STATE_ACTIVE" 17 "UNRECOVERABLE_DEVICE_ERROR" 16 "ERROR_WAIT_FOR_RESET" 15 "WAIT_FOR_RETRY_AFTER_ERROR" 14 "WAIT_FOR_SESSION_DEINIT" 13 "DEINIT_SESSION" 12 "WAIT_FOR_SESSION_STOP" 11 "STOP_SESSION" 10 "RANGING" 9 "WAIT_FOR_RANGING_STARTED_CONFIRMATION" 8 "WAIT_FOR_APPLE_SESSION_INITIATE" 7 "APPLE_SESSION_INITIATE" 6 "WAIT_FOR_APPLE_SHAREABLE_CONFIGURATION_DATA" 5 "SEND_CONFIGURATION_DATA_TO_PHONE" 4 "WAIT_FOR_CONFIGURATION_DATA" 3 "REQUEST_CONFIGURATION_DATA" 2 "WAIT_FOR_CORE_CONFIG_DATA" 1 "APPLY_CORE_CONFIG_DATA" 0 "IDLE" ;
VAL_ 1817 VCSEC_NISessionStateCenter1 21 "COUNT" 20 "SESSION_INITIATE" 19 "WAIT_FOR_SESSION_INITIATE" 18 "WAIT_FOR_SESSION_STATE_ACTIVE" 17 "UNRECOVERABLE_DEVICE_ERROR" 16 "ERROR_WAIT_FOR_RESET" 15 "WAIT_FOR_RETRY_AFTER_ERROR" 14 "WAIT_FOR_SESSION_DEINIT" 13 "DEINIT_SESSION" 12 "WAIT_FOR_SESSION_STOP" 11 "STOP_SESSION" 10 "RANGING" 9 "WAIT_FOR_RANGING_STARTED_CONFIRMATION" 8 "WAIT_FOR_APPLE_SESSION_INITIATE" 7 "APPLE_SESSION_INITIATE" 6 "WAIT_FOR_APPLE_SHAREABLE_CONFIGURATION_DATA" 5 "SEND_CONFIGURATION_DATA_TO_PHONE" 4 "WAIT_FOR_CONFIGURATION_DATA" 3 "REQUEST_CONFIGURATION_DATA" 2 "WAIT_FOR_CORE_CONFIG_DATA" 1 "APPLY_CORE_CONFIG_DATA" 0 "IDLE" ;
VAL_ 1817 VCSEC_NISessionStateLeft1 21 "COUNT" 20 "SESSION_INITIATE" 19 "WAIT_FOR_SESSION_INITIATE" 18 "WAIT_FOR_SESSION_STATE_ACTIVE" 17 "UNRECOVERABLE_DEVICE_ERROR" 16 "ERROR_WAIT_FOR_RESET" 15 "WAIT_FOR_RETRY_AFTER_ERROR" 14 "WAIT_FOR_SESSION_DEINIT" 13 "DEINIT_SESSION" 12 "WAIT_FOR_SESSION_STOP" 11 "STOP_SESSION" 10 "RANGING" 9 "WAIT_FOR_RANGING_STARTED_CONFIRMATION" 8 "WAIT_FOR_APPLE_SESSION_INITIATE" 7 "APPLE_SESSION_INITIATE" 6 "WAIT_FOR_APPLE_SHAREABLE_CONFIGURATION_DATA" 5 "SEND_CONFIGURATION_DATA_TO_PHONE" 4 "WAIT_FOR_CONFIGURATION_DATA" 3 "REQUEST_CONFIGURATION_DATA" 2 "WAIT_FOR_CORE_CONFIG_DATA" 1 "APPLY_CORE_CONFIG_DATA" 0 "IDLE" ;
VAL_ 1817 VCSEC_NISessionStateRight1 21 "COUNT" 20 "SESSION_INITIATE" 19 "WAIT_FOR_SESSION_INITIATE" 18 "WAIT_FOR_SESSION_STATE_ACTIVE" 17 "UNRECOVERABLE_DEVICE_ERROR" 16 "ERROR_WAIT_FOR_RESET" 15 "WAIT_FOR_RETRY_AFTER_ERROR" 14 "WAIT_FOR_SESSION_DEINIT" 13 "DEINIT_SESSION" 12 "WAIT_FOR_SESSION_STOP" 11 "STOP_SESSION" 10 "RANGING" 9 "WAIT_FOR_RANGING_STARTED_CONFIRMATION" 8 "WAIT_FOR_APPLE_SESSION_INITIATE" 7 "APPLE_SESSION_INITIATE" 6 "WAIT_FOR_APPLE_SHAREABLE_CONFIGURATION_DATA" 5 "SEND_CONFIGURATION_DATA_TO_PHONE" 4 "WAIT_FOR_CONFIGURATION_DATA" 3 "REQUEST_CONFIGURATION_DATA" 2 "WAIT_FOR_CORE_CONFIG_DATA" 1 "APPLY_CORE_CONFIG_DATA" 0 "IDLE" ;
VAL_ 1817 VCSEC_NISessionStateRearLeft1 21 "COUNT" 20 "SESSION_INITIATE" 19 "WAIT_FOR_SESSION_INITIATE" 18 "WAIT_FOR_SESSION_STATE_ACTIVE" 17 "UNRECOVERABLE_DEVICE_ERROR" 16 "ERROR_WAIT_FOR_RESET" 15 "WAIT_FOR_RETRY_AFTER_ERROR" 14 "WAIT_FOR_SESSION_DEINIT" 13 "DEINIT_SESSION" 12 "WAIT_FOR_SESSION_STOP" 11 "STOP_SESSION" 10 "RANGING" 9 "WAIT_FOR_RANGING_STARTED_CONFIRMATION" 8 "WAIT_FOR_APPLE_SESSION_INITIATE" 7 "APPLE_SESSION_INITIATE" 6 "WAIT_FOR_APPLE_SHAREABLE_CONFIGURATION_DATA" 5 "SEND_CONFIGURATION_DATA_TO_PHONE" 4 "WAIT_FOR_CONFIGURATION_DATA" 3 "REQUEST_CONFIGURATION_DATA" 2 "WAIT_FOR_CORE_CONFIG_DATA" 1 "APPLY_CORE_CONFIG_DATA" 0 "IDLE" ;
VAL_ 1817 VCSEC_NISessionStateRearRight1 21 "COUNT" 20 "SESSION_INITIATE" 19 "WAIT_FOR_SESSION_INITIATE" 18 "WAIT_FOR_SESSION_STATE_ACTIVE" 17 "UNRECOVERABLE_DEVICE_ERROR" 16 "ERROR_WAIT_FOR_RESET" 15 "WAIT_FOR_RETRY_AFTER_ERROR" 14 "WAIT_FOR_SESSION_DEINIT" 13 "DEINIT_SESSION" 12 "WAIT_FOR_SESSION_STOP" 11 "STOP_SESSION" 10 "RANGING" 9 "WAIT_FOR_RANGING_STARTED_CONFIRMATION" 8 "WAIT_FOR_APPLE_SESSION_INITIATE" 7 "APPLE_SESSION_INITIATE" 6 "WAIT_FOR_APPLE_SHAREABLE_CONFIGURATION_DATA" 5 "SEND_CONFIGURATION_DATA_TO_PHONE" 4 "WAIT_FOR_CONFIGURATION_DATA" 3 "REQUEST_CONFIGURATION_DATA" 2 "WAIT_FOR_CORE_CONFIG_DATA" 1 "APPLY_CORE_CONFIG_DATA" 0 "IDLE" ;
VAL_ 1817 VCSEC_NISessionStateRear1 21 "COUNT" 20 "SESSION_INITIATE" 19 "WAIT_FOR_SESSION_INITIATE" 18 "WAIT_FOR_SESSION_STATE_ACTIVE" 17 "UNRECOVERABLE_DEVICE_ERROR" 16 "ERROR_WAIT_FOR_RESET" 15 "WAIT_FOR_RETRY_AFTER_ERROR" 14 "WAIT_FOR_SESSION_DEINIT" 13 "DEINIT_SESSION" 12 "WAIT_FOR_SESSION_STOP" 11 "STOP_SESSION" 10 "RANGING" 9 "WAIT_FOR_RANGING_STARTED_CONFIRMATION" 8 "WAIT_FOR_APPLE_SESSION_INITIATE" 7 "APPLE_SESSION_INITIATE" 6 "WAIT_FOR_APPLE_SHAREABLE_CONFIGURATION_DATA" 5 "SEND_CONFIGURATION_DATA_TO_PHONE" 4 "WAIT_FOR_CONFIGURATION_DATA" 3 "REQUEST_CONFIGURATION_DATA" 2 "WAIT_FOR_CORE_CONFIG_DATA" 1 "APPLY_CORE_CONFIG_DATA" 0 "IDLE" ;
VAL_ 1817 VCSEC_NISessionStateCenter2 21 "COUNT" 20 "SESSION_INITIATE" 19 "WAIT_FOR_SESSION_INITIATE" 18 "WAIT_FOR_SESSION_STATE_ACTIVE" 17 "UNRECOVERABLE_DEVICE_ERROR" 16 "ERROR_WAIT_FOR_RESET" 15 "WAIT_FOR_RETRY_AFTER_ERROR" 14 "WAIT_FOR_SESSION_DEINIT" 13 "DEINIT_SESSION" 12 "WAIT_FOR_SESSION_STOP" 11 "STOP_SESSION" 10 "RANGING" 9 "WAIT_FOR_RANGING_STARTED_CONFIRMATION" 8 "WAIT_FOR_APPLE_SESSION_INITIATE" 7 "APPLE_SESSION_INITIATE" 6 "WAIT_FOR_APPLE_SHAREABLE_CONFIGURATION_DATA" 5 "SEND_CONFIGURATION_DATA_TO_PHONE" 4 "WAIT_FOR_CONFIGURATION_DATA" 3 "REQUEST_CONFIGURATION_DATA" 2 "WAIT_FOR_CORE_CONFIG_DATA" 1 "APPLY_CORE_CONFIG_DATA" 0 "IDLE" ;
VAL_ 1817 VCSEC_NISessionStateLeft2 21 "COUNT" 20 "SESSION_INITIATE" 19 "WAIT_FOR_SESSION_INITIATE" 18 "WAIT_FOR_SESSION_STATE_ACTIVE" 17 "UNRECOVERABLE_DEVICE_ERROR" 16 "ERROR_WAIT_FOR_RESET" 15 "WAIT_FOR_RETRY_AFTER_ERROR" 14 "WAIT_FOR_SESSION_DEINIT" 13 "DEINIT_SESSION" 12 "WAIT_FOR_SESSION_STOP" 11 "STOP_SESSION" 10 "RANGING" 9 "WAIT_FOR_RANGING_STARTED_CONFIRMATION" 8 "WAIT_FOR_APPLE_SESSION_INITIATE" 7 "APPLE_SESSION_INITIATE" 6 "WAIT_FOR_APPLE_SHAREABLE_CONFIGURATION_DATA" 5 "SEND_CONFIGURATION_DATA_TO_PHONE" 4 "WAIT_FOR_CONFIGURATION_DATA" 3 "REQUEST_CONFIGURATION_DATA" 2 "WAIT_FOR_CORE_CONFIG_DATA" 1 "APPLY_CORE_CONFIG_DATA" 0 "IDLE" ;
VAL_ 1817 VCSEC_NISessionStateRight2 21 "COUNT" 20 "SESSION_INITIATE" 19 "WAIT_FOR_SESSION_INITIATE" 18 "WAIT_FOR_SESSION_STATE_ACTIVE" 17 "UNRECOVERABLE_DEVICE_ERROR" 16 "ERROR_WAIT_FOR_RESET" 15 "WAIT_FOR_RETRY_AFTER_ERROR" 14 "WAIT_FOR_SESSION_DEINIT" 13 "DEINIT_SESSION" 12 "WAIT_FOR_SESSION_STOP" 11 "STOP_SESSION" 10 "RANGING" 9 "WAIT_FOR_RANGING_STARTED_CONFIRMATION" 8 "WAIT_FOR_APPLE_SESSION_INITIATE" 7 "APPLE_SESSION_INITIATE" 6 "WAIT_FOR_APPLE_SHAREABLE_CONFIGURATION_DATA" 5 "SEND_CONFIGURATION_DATA_TO_PHONE" 4 "WAIT_FOR_CONFIGURATION_DATA" 3 "REQUEST_CONFIGURATION_DATA" 2 "WAIT_FOR_CORE_CONFIG_DATA" 1 "APPLY_CORE_CONFIG_DATA" 0 "IDLE" ;
VAL_ 1817 VCSEC_NISessionStateRearLeft2 21 "COUNT" 20 "SESSION_INITIATE" 19 "WAIT_FOR_SESSION_INITIATE" 18 "WAIT_FOR_SESSION_STATE_ACTIVE" 17 "UNRECOVERABLE_DEVICE_ERROR" 16 "ERROR_WAIT_FOR_RESET" 15 "WAIT_FOR_RETRY_AFTER_ERROR" 14 "WAIT_FOR_SESSION_DEINIT" 13 "DEINIT_SESSION" 12 "WAIT_FOR_SESSION_STOP" 11 "STOP_SESSION" 10 "RANGING" 9 "WAIT_FOR_RANGING_STARTED_CONFIRMATION" 8 "WAIT_FOR_APPLE_SESSION_INITIATE" 7 "APPLE_SESSION_INITIATE" 6 "WAIT_FOR_APPLE_SHAREABLE_CONFIGURATION_DATA" 5 "SEND_CONFIGURATION_DATA_TO_PHONE" 4 "WAIT_FOR_CONFIGURATION_DATA" 3 "REQUEST_CONFIGURATION_DATA" 2 "WAIT_FOR_CORE_CONFIG_DATA" 1 "APPLY_CORE_CONFIG_DATA" 0 "IDLE" ;
VAL_ 1817 VCSEC_NISessionStateRearRight2 21 "COUNT" 20 "SESSION_INITIATE" 19 "WAIT_FOR_SESSION_INITIATE" 18 "WAIT_FOR_SESSION_STATE_ACTIVE" 17 "UNRECOVERABLE_DEVICE_ERROR" 16 "ERROR_WAIT_FOR_RESET" 15 "WAIT_FOR_RETRY_AFTER_ERROR" 14 "WAIT_FOR_SESSION_DEINIT" 13 "DEINIT_SESSION" 12 "WAIT_FOR_SESSION_STOP" 11 "STOP_SESSION" 10 "RANGING" 9 "WAIT_FOR_RANGING_STARTED_CONFIRMATION" 8 "WAIT_FOR_APPLE_SESSION_INITIATE" 7 "APPLE_SESSION_INITIATE" 6 "WAIT_FOR_APPLE_SHAREABLE_CONFIGURATION_DATA" 5 "SEND_CONFIGURATION_DATA_TO_PHONE" 4 "WAIT_FOR_CONFIGURATION_DATA" 3 "REQUEST_CONFIGURATION_DATA" 2 "WAIT_FOR_CORE_CONFIG_DATA" 1 "APPLY_CORE_CONFIG_DATA" 0 "IDLE" ;
VAL_ 1817 VCSEC_NISessionStateRear2 21 "COUNT" 20 "SESSION_INITIATE" 19 "WAIT_FOR_SESSION_INITIATE" 18 "WAIT_FOR_SESSION_STATE_ACTIVE" 17 "UNRECOVERABLE_DEVICE_ERROR" 16 "ERROR_WAIT_FOR_RESET" 15 "WAIT_FOR_RETRY_AFTER_ERROR" 14 "WAIT_FOR_SESSION_DEINIT" 13 "DEINIT_SESSION" 12 "WAIT_FOR_SESSION_STOP" 11 "STOP_SESSION" 10 "RANGING" 9 "WAIT_FOR_RANGING_STARTED_CONFIRMATION" 8 "WAIT_FOR_APPLE_SESSION_INITIATE" 7 "APPLE_SESSION_INITIATE" 6 "WAIT_FOR_APPLE_SHAREABLE_CONFIGURATION_DATA" 5 "SEND_CONFIGURATION_DATA_TO_PHONE" 4 "WAIT_FOR_CONFIGURATION_DATA" 3 "REQUEST_CONFIGURATION_DATA" 2 "WAIT_FOR_CORE_CONFIG_DATA" 1 "APPLY_CORE_CONFIG_DATA" 0 "IDLE" ;
VAL_ 1655 VC_lvbmsStatusHighIndex 6 "INVALID" 5 "PCS_INTERFACE" 4 "STATE_AND_COMMANDS" 3 "TARGETS" 2 "CELL_VITALS_2" 1 "CELL_VITALS_1" 0 "PACK_VITALS_1" ;
VAL_ 1655 VC_LVBMS_packCurrent 4194303 "SNA" ;
VAL_ 1655 VC_LVBMS_packVoltage 65535 "SNA" ;
VAL_ 1655 VC_LVBMS_packTemperature 511 "SNA" ;
VAL_ 1655 VC_LVBMS_MOSTemperature 4095 "SNA" ;
VAL_ 1655 VC_LVBMS_sumCellVoltage 65535 "SNA" 65534 "INVALID" ;
VAL_ 1655 VC_LVBMS_maxBrickVoltage 8191 "SNA" ;
VAL_ 1655 VC_LVBMS_maxBrickVoltageIndex 255 "SNA" ;
VAL_ 1655 VC_LVBMS_avgBrickVoltage 8191 "SNA" ;
VAL_ 1655 VC_LVBMS_minBrickVoltage 8191 "SNA" ;
VAL_ 1655 VC_LVBMS_minBrickVoltageIndex 255 "SNA" ;
VAL_ 1655 VC_LVBMS_voltageTarget 65535 "SNA" ;
VAL_ 1655 VC_LVBMS_currentTarget 131071 "SNA" ;
VAL_ 1655 VC_LVBMS_maxAllowedChargeCurrent 8191 "SNA" ;
VAL_ 1655 VC_LVBMS_maxAllowedDischargeCurr 8191 "SNA" ;
VAL_ 1655 VC_LVBMS_ECPAState 3 "LVBMS_ECPA_STATE_SNA" 2 "LVBMS_ECPA_STATE_INVALID" 1 "LVBMS_ECPA_STATE_CLOSED" 0 "LVBMS_ECPA_STATE_OPEN" ;
VAL_ 1655 VC_LVBMS_MOSState 3 "LVBMS_MOS_STATE_SNA" 2 "LVBMS_MOS_STATE_INVALID" 1 "LVBMS_MOS_STATE_CLOSED" 0 "LVBMS_MOS_STATE_OPEN" ;
VAL_ 1655 VC_LVBMS_VehicleState 3 "LVBMS_VEHICLE_STATE_OFF" 2 "LVBMS_VEHICLE_STATE_CONDITIONING" 1 "LVBMS_VEHICLE_STATE_ACCESSORY" 0 "LVBMS_VEHICLE_STATE_DRIVE" ;
VAL_ 1655 VC_LVBMS_LINWakeDisabled 1 "LVBMS_LIN_WAKE_DISABLED" 0 "LVBMS_LIN_WAKE_ENABLED" ;
VAL_ 1655 VC_LVBMS_chargeType 4 "LVBMS_CHARGE_SNA" 3 "LVBMS_CHARGE_COMPLETE" 2 "LVBMS_CHARGE_CONSTANT_VOLTAGE" 1 "LVBMS_CHARGE_CONSTANT_CURRENT" 0 "LVBMS_CHARGE_UNDEFINED" ;
VAL_ 1816 VC_lvbmsStatusLowIndex 6 "INVALID" 5 "FAULT_STATS" 4 "PACK_VITALS_2" 3 "THROUGHPUT_3" 2 "THROUGHPUT_2" 1 "THROUGHPUT_1" 0 "STATE" ;
VAL_ 1816 VC_LVBMS_SOC 127 "SNA" ;
VAL_ 1816 VC_LVBMS_SOE 127 "SNA" ;
VAL_ 1816 VC_LVBMS_SOH 127 "SNA" ;
VAL_ 1816 VC_LVBMS_SOP 16777215 "SNA" ;
VAL_ 1816 VC_LVBMS_AvgSleepCurrent 65535 "SNA" ;
VAL_ 1816 VC_LVBMS_TimeSlept 16777215 "SNA" ;
VAL_ 1816 VC_LVBMS_AhCharged 4294967295 "SNA" ;
VAL_ 1816 VC_LVBMS_MinSleepCurrent 65535 "SNA" ;
VAL_ 1816 VC_LVBMS_AhDischarged 4294967295 "SNA" ;
VAL_ 1816 VC_LVBMS_MaxSleepCurrent 65535 "SNA" ;
VAL_ 1816 VC_LVBMS_sumCellVoltageFiltered 65535 "SNA" 65534 "INVALID" ;
VAL_ 1816 VC_LVBMS_maxCellSOC 127 "SNA" ;
VAL_ 1816 VC_LVBMS_minCellSOC 127 "SNA" ;
VAL_ 1816 VC_LVBMS_staticSOCCorrection 1 "LVBMS_CORRECTION_STATE_ACTIVE" 0 "LVBMS_CORRECTION_STATE_INACTIVE" ;
VAL_ 1816 VC_LVBMS_dynamicSOCCorrection 1 "LVBMS_CORRECTION_STATE_ACTIVE" 0 "LVBMS_CORRECTION_STATE_INACTIVE" ;
VAL_ 1816 VC_LVBMS_usableEnergyAvailable 4095 "SNA" ;
VAL_ 1089 VC_pcsInterfaceMuxIndex 1 "1" 0 "0" ;
VAL_ 1089 VC_pcsResistanceFiltered 65535 "SNA" ;
